VERSION "dbc-export 1 2026.26.6.5"

NS_ :

BS_:

BU_: APP BMS CC CMP CMPD CP DAS DI DIF DIR EPBL EPBR EVSE FC GTW HCML HCMR HVP ICR PCS PCS2 PM PMF PMR PTC SCCM SDCR TAS UMC V2G VC VCBATT VCBATT1 VCBATT2 VCFRONT VCFRONT1 VCLEFT VCRIGHT VCSEC

BO_ 947 UI_vehicleControl2: 8 GTW
 SG_ UI_gloveboxRequest : 0|1@1+ (1,0) [0|1] "" Vector__XXX
 SG_ UI_trunkRequest : 1|1@1+ (1,0) [0|1] "" Vector__XXX
 SG_ UI_PINToDriveEnabled : 6|1@1+ (1,0) [0|1] "" Vector__XXX
 SG_ UI_PINToDrivePassed : 7|1@1+ (1,0) [0|1] "" Vector__XXX
 SG_ UI_disableMirrorAutoDim : 8|1@1+ (1,0) [0|1] "" Vector__XXX
 SG_ UI_lightSwitch : 9|3@1+ (1,0) [0|7] "" Vector__XXX
 SG_ UI_readyToAddKey : 12|1@1+ (1,0) [0|1] "" Vector__XXX
 SG_ UI_alarmTriggerRequest : 13|1@1+ (1,0) [0|1] "" Vector__XXX
 SG_ UI_displayOnForUser : 18|1@1+ (1,0) [0|1] "" Vector__XXX
 SG_ UI_BLEPushNotificationRequest : 20|1@1+ (1,0) [0|1] "" Vector__XXX
 SG_ UI_keepAutopilotAwake : 22|1@1+ (1,0) [0|1] "" Vector__XXX
 SG_ UI_batteryPreconditioningRequest : 23|1@1+ (1,0) [0|1] "" Vector__XXX
 SG_ UI_autopilotPowerStateRequest : 25|2@1+ (1,0) [0|3] "" Vector__XXX
 SG_ UI_autoRollWindowsOnLockEnable : 29|1@1+ (1,0) [0|1] "" Vector__XXX
 SG_ UI_steeringWheelHeatReq : 33|1@1+ (1,0) [0|1] "" Vector__XXX
 SG_ UI_disableHorn : 34|1@1+ (1,0) [0|1] "" Vector__XXX
 SG_ UI_frontLeftSeatFanReq : 37|2@1+ (1,0) [0|3] "" Vector__XXX
 SG_ UI_frontRightSeatAutoClimateReq : 39|1@1+ (1,0) [0|1] "" Vector__XXX
 SG_ UI_frontRightSeatFanReq : 40|2@1+ (1,0) [0|3] "" Vector__XXX
 SG_ UI_frontLeftSeatAutoClimateReq : 56|1@1+ (1,0) [0|1] "" Vector__XXX
 SG_ UI_wiperHeaterReq : 57|1@1+ (1,0) [0|1] "" Vector__XXX
 SG_ UI_silentAlarm : 61|1@1+ (1,0) [0|1] "" Vector__XXX

BO_ 660 UI_vehicleControl3: 8 GTW
 SG_ UI_lightFlashRequest : 0|2@1+ (1,0) [0|3] "" Vector__XXX
 SG_ UI_phoneCallActive : 3|1@1+ (1,0) [0|1] "" Vector__XXX
 SG_ UI_lightShowClosuresEnabled : 8|1@1+ (1,0) [0|1] "" Vector__XXX
 SG_ UI_steeringWheelHeatAutoReq : 9|1@1+ (1,0) [0|1] "" Vector__XXX
 SG_ UI_steeringWheelHeatLevelReq : 10|2@1+ (1,0) [0|3] "" Vector__XXX
 SG_ UI_headlightPulseRequest : 12|1@1+ (1,0) [0|1] "" Vector__XXX
 SG_ UI_displayRedShiftActive : 24|1@1+ (1,0) [0|1] "" Vector__XXX
 SG_ UI_fasciaCameraWashRequest : 26|1@1+ (1,0) [0|1] "" Vector__XXX
 SG_ UI_leftRearSeatAdjustmentRequest : 28|3@1+ (1,0) [0|7] "" Vector__XXX
 SG_ UI_rightRearSeatAdjustmentReques : 32|3@1+ (1,0) [0|7] "" Vector__XXX
 SG_ UI_blindSpotIndicatorLightReques : 35|1@1+ (1,0) [0|1] "" Vector__XXX
 SG_ UI_keepOnAccessoryPortsReq : 38|1@1+ (1,0) [0|1] "" Vector__XXX
 SG_ UI_fasciaCameraShown : 39|1@1+ (1,0) [0|1] "" Vector__XXX
 SG_ UI_rearSeatChildLock : 40|2@1+ (1,0) [0|3] "" Vector__XXX
 SG_ UI_windowPercentageRequest : 42|6@1- (5,0) [-100|100] "%" Vector__XXX
 SG_ UI_windowRequestedFL : 48|1@1+ (1,0) [0|1] "" Vector__XXX
 SG_ UI_windowRequestedFR : 49|1@1+ (1,0) [0|1] "" Vector__XXX
 SG_ UI_windowRequestedRL : 50|1@1+ (1,0) [0|1] "" Vector__XXX
 SG_ UI_windowRequestedRR : 51|1@1+ (1,0) [0|1] "" Vector__XXX
 SG_ UI_windowRequest : 52|3@1+ (1,0) [0|7] "" Vector__XXX
 SG_ UI_closeTrunkRequest : 55|1@1+ (1,0) [0|1] "" Vector__XXX
 SG_ UI_childPresenceDetectionDisable : 56|1@1+ (1,0) [0|1] "" Vector__XXX
 SG_ UI_derivedLoadshedFeature : 59|1@1+ (1,0) [0|1] "" Vector__XXX
 SG_ UI_selfParkStandingBy : 62|1@1+ (1,0) [0|1] "" Vector__XXX

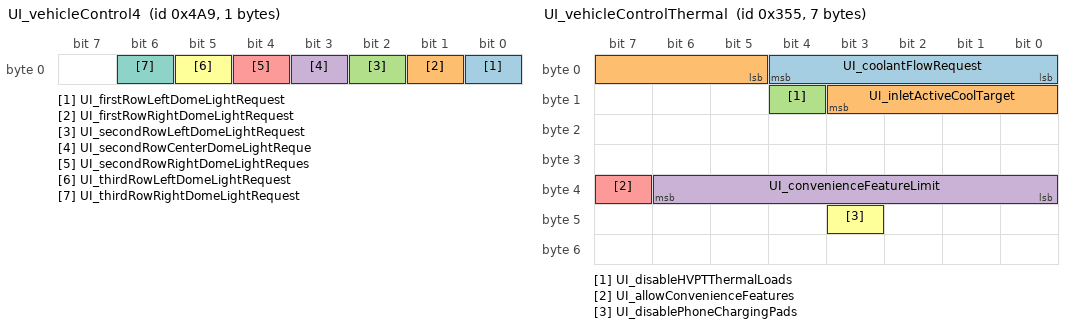
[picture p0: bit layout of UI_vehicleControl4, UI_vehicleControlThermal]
BO_ 1193 UI_vehicleControl4: 1 GTW
 SG_ UI_firstRowLeftDomeLightRequest : 0|1@1+ (1,0) [0|1] "" Vector__XXX
 SG_ UI_firstRowRightDomeLightRequest : 1|1@1+ (1,0) [0|1] "" Vector__XXX
 SG_ UI_secondRowLeftDomeLightRequest : 2|1@1+ (1,0) [0|1] "" Vector__XXX
 SG_ UI_secondRowCenterDomeLightReque : 3|1@1+ (1,0) [0|1] "" Vector__XXX
 SG_ UI_secondRowRightDomeLightReques : 4|1@1+ (1,0) [0|1] "" Vector__XXX
 SG_ UI_thirdRowLeftDomeLightRequest : 5|1@1+ (1,0) [0|1] "" Vector__XXX
 SG_ UI_thirdRowRightDomeLightRequest : 6|1@1+ (1,0) [0|1] "" Vector__XXX

BO_ 853 UI_vehicleControlThermal: 7 GTW
 SG_ UI_coolantFlowRequest : 0|5@1+ (1,0) [0|25] "LPM" Vector__XXX
 SG_ UI_inletActiveCoolTarget : 5|7@1+ (1,0) [0|127] "degC" Vector__XXX
 SG_ UI_disableHVPTThermalLoads : 12|1@1+ (1,0) [0|1] "" Vector__XXX
 SG_ UI_convenienceFeatureLimit : 32|7@1+ (1,0) [0|127] "%" Vector__XXX
 SG_ UI_allowConvenienceFeatures : 39|1@1+ (1,0) [0|1] "" Vector__XXX
 SG_ UI_disablePhoneChargingPads : 43|1@1+ (1,0) [0|1] "" Vector__XXX

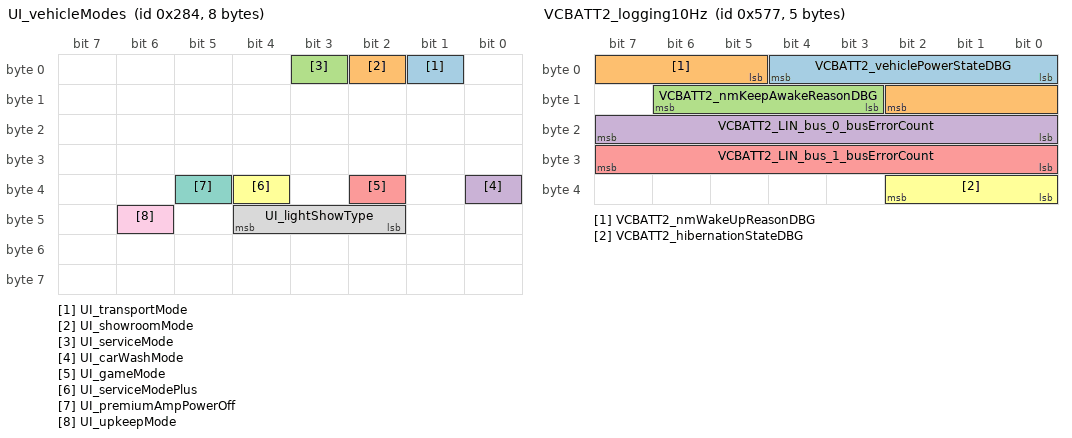
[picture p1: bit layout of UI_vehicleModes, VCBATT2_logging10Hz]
BO_ 644 UI_vehicleModes: 8 GTW
 SG_ UI_transportMode : 1|1@1+ (1,0) [0|1] "" Vector__XXX
 SG_ UI_showroomMode : 2|1@1+ (1,0) [0|1] "" Vector__XXX
 SG_ UI_serviceMode : 3|1@1+ (1,0) [0|1] "" Vector__XXX
 SG_ UI_carWashMode : 32|1@1+ (1,0) [0|1] "" Vector__XXX
 SG_ UI_gameMode : 34|1@1+ (1,0) [0|1] "" Vector__XXX
 SG_ UI_serviceModePlus : 36|1@1+ (1,0) [0|1] "" Vector__XXX
 SG_ UI_premiumAmpPowerOff : 37|1@1+ (1,0) [0|1] "" Vector__XXX
 SG_ UI_lightShowType : 42|3@1+ (1,0) [0|7] "" Vector__XXX
 SG_ UI_upkeepMode : 46|1@1+ (1,0) [0|1] "" Vector__XXX

BO_ 595 UI_ventPanelControlRequest: 8 GTW
 SG_ UI_ventPanelControlRequestIndex M : 0|1@1+ (1,0) [0|1] "" Vector__XXX
 SG_ UI_ventPanelLeftPositionX m0 : 8|8@1+ (0.5,0) [0|100] "%" Vector__XXX
 SG_ UI_ventPanelLeftPositionY m0 : 16|8@1+ (0.5,0) [0|100] "%" Vector__XXX
 SG_ UI_ventPanelLeftLateralSplit m0 : 24|8@1+ (0.5,0) [0|100] "%" Vector__XXX
 SG_ UI_ventPanelRightPositionX m0 : 32|8@1+ (0.5,0) [0|100] "%" Vector__XXX
 SG_ UI_ventPanelRightPositionY m0 : 40|8@1+ (0.5,0) [0|100] "%" Vector__XXX
 SG_ UI_ventPanelRightLateralSplit m0 : 48|8@1+ (0.5,0) [0|100] "%" Vector__XXX
 SG_ UI_ventPanelLeftLateralMode m0 : 56|2@1+ (1,0) [0|3] "" Vector__XXX
 SG_ UI_ventPanelRightLateralMode m0 : 58|2@1+ (1,0) [0|3] "" Vector__XXX
 SG_ UI_hvacReqActiveVents m0 : 60|2@1+ (1,0) [0|3] "" Vector__XXX
 SG_ UI_vent2RLeftPositionX m1 : 8|8@1+ (0.5,0) [0|100] "%" Vector__XXX
 SG_ UI_vent2RLeftPositionY m1 : 16|8@1+ (0.5,0) [0|100] "%" Vector__XXX
 SG_ UI_vent2RRightPositionX m1 : 24|8@1+ (0.5,0) [0|100] "%" Vector__XXX
 SG_ UI_vent2RRightPositionY m1 : 32|8@1+ (0.5,0) [0|100] "%" Vector__XXX
 SG_ UI_hvacReqThirdRowState m1 : 40|2@1+ (1,0) [0|3] "" Vector__XXX

BO_ 1285 UMC_smartAdapterInfo: 8 UMC
 SG_ SA_infoIndex M : 0|8@1+ (1,0) [0|255] "" Vector__XXX
 SG_ SA_genealogyVersion m0 : 8|8@1+ (1,0) [0|255] "" Vector__XXX
 SG_ SA_genealogyCrc m0 : 16|32@1+ (1,0) [0|4294967295] "" Vector__XXX
 SG_ SA_region m0 : 48|4@1+ (1,0) [0|15] "" Vector__XXX
 SG_ SA_OverTempThreshold m0 : 56|8@1+ (1,0) [0|255] "" Vector__XXX
 SG_ SA_partNumInt m31 : 8|32@1+ (1,0) [0|4294967295] "" Vector__XXX
 SG_ SA_partNumRev m31 : 40|8@1+ (1,0) [0|255] "" Vector__XXX
 SG_ SA_currentLimit m31 : 48|8@1+ (1,0) [0|255] "" Vector__XXX
 SG_ SA_l1Voltage m31 : 56|8@1+ (1,0) [0|255] "" Vector__XXX

BO_ 1949 V2G_evseLogData: 8 V2G
 SG_ V2G_evseLogDataSelect M : 0|5@1+ (1,0) [0|31] "" Vector__XXX
 SG_ V2G_chgParamRes_respCode m7 : 8|5@1+ (1,0) [0|31] "" Vector__XXX
 SG_ V2G_chgParamRes_finished m7 : 13|1@1+ (1,0) [0|1] "" Vector__XXX
 SG_ V2G_chgParamRes_evseStatus m7 : 14|4@1+ (1,0) [0|15] "" Vector__XXX
 SG_ V2G_chgParamRes_evseMaxILim m7 : 18|8@1+ (7.032,0) [0|1793.16] "A" Vector__XXX
 SG_ V2G_chgParamRes_evseMaxVLim m7 : 26|8@1+ (4.688,0) [0|1195.44] "V" Vector__XXX
 SG_ V2G_chgParamRes_evseMinILim m7 : 34|8@1+ (7.032,0) [0|1793.16] "A" Vector__XXX
 SG_ V2G_chgParamRes_evseMinVLim m7 : 42|8@1+ (4.688,0) [0|1195.44] "V" Vector__XXX
 SG_ V2G_chgParamRes_evseMaxPowerLim m7 : 50|8@1+ (5.9766,0) [0|1524.033] "kW" Vector__XXX
 SG_ V2G_chgParamRes_evseMaxPower_val m7 : 58|1@1+ (1,0) [0|1] "" Vector__XXX
 SG_ V2G_chgParamRes_isoState m7 : 59|3@1+ (1,0) [0|7] "" Vector__XXX
 SG_ V2G_chgParamRes_isoState_val m7 : 62|1@1+ (1,0) [0|1] "" Vector__XXX

BO_ 1858 VCBATT1_LVBMS_statusHigh: 8 VCBATT1
 SG_ VCBATT1_lvbmsStatusHighIndex M : 0|3@1+ (1,0) [0|7] "" Vector__XXX
 SG_ VCBATT1_LVBMS_packCurrent m0 : 3|22@1+ (0.001,-2000) [-2000|2194.302] "A" Vector__XXX
 SG_ VCBATT1_LVBMS_packVoltage m0 : 25|16@1+ (0.001,0) [0|65.534] "V" Vector__XXX
 SG_ VCBATT1_LVBMS_packTemperature m0 : 41|9@1+ (0.5,-50) [-50|205] "degC" Vector__XXX
 SG_ VCBATT1_LVBMS_MOSTemperature m0 : 50|12@1+ (0.5,-50) [-50|1997] "degC" Vector__XXX
 SG_ VCBATT1_LVBMS_sumCellVoltage m1 : 8|16@1+ (0.001,0) [0|65.534] "V" Vector__XXX
 SG_ VCBATT1_LVBMS_maxBrickVoltage m1 : 24|13@1+ (0.001,0) [0|8.19] "V" Vector__XXX
 SG_ VCBATT1_LVBMS_maxBrickVoltageInd m1 : 40|8@1+ (1,0) [0|254] "" Vector__XXX
 SG_ VCBATT1_totalLVLoadCurrent m2 : 8|14@1- (0.1,0) [-200|400] "A" Vector__XXX
 SG_ VCBATT1_LVPackChargeCurrentLimit m2 : 22|12@1+ (0.1,0) [0|400] "A" Vector__XXX
 SG_ VCBATT1_LVPackCurrent m2 : 34|14@1- (0.1,0) [-200|400] "A" Vector__XXX
 SG_ VCBATT1_LVBMS_estimatedPackOcv m2 : 48|16@1+ (0.001,0) [0|65.535] "V" Vector__XXX
 SG_ VCBATT1_LVBMS_voltageTarget m3 : 3|16@1+ (0.001,0) [0|65.534] "V" Vector__XXX
 SG_ VCBATT1_LVBMS_currentTarget m3 : 19|18@1+ (0.001,-122) [-120|120] "A" Vector__XXX
 SG_ VCBATT1_LVBMS_maxAllowedChargeCu m3 : 37|13@1+ (0.1,0) [0|819] "A" Vector__XXX
 SG_ VCBATT1_LVBMS_maxAllowedDischarg m3 : 50|13@1+ (0.1,0) [0|819] "A" Vector__XXX
 SG_ VCBATT1_LVBMS_MOSCommand m4 : 3|1@1+ (1,0) [0|1] "" Vector__XXX
 SG_ VCBATT1_LVBMS_ClearErrorCntrComm m4 : 4|1@1+ (1,0) [0|1] "" Vector__XXX
 SG_ VCBATT1_LVBMS_ClearHistoricFault m4 : 5|1@1+ (1,0) [0|1] "" Vector__XXX
 SG_ VCBATT1_LVBMS_ResetLVBMSCommand m4 : 6|1@1+ (1,0) [0|1] "" Vector__XXX
 SG_ VCBATT1_LVBMS_EnterHibernationCo m4 : 7|1@1+ (1,0) [0|1] "" Vector__XXX
 SG_ VCBATT1_LVBMS_ECPAState m4 : 8|2@1+ (1,0) [0|2] "" Vector__XXX
 SG_ VCBATT1_LVBMS_MOSState m4 : 10|2@1+ (1,0) [0|2] "" Vector__XXX
 SG_ VCBATT1_LVBMS_VehicleState m4 : 12|2@1+ (1,0) [0|3] "" Vector__XXX
 SG_ VCBATT1_LVBMS_LINWakeDisabled m4 : 14|1@1+ (1,0) [0|1] "" Vector__XXX
 SG_ VCBATT1_LVBMS_chargeType m4 : 16|3@1+ (1,0) [0|7] "" Vector__XXX
 SG_ VCBATT1_LVBMS_cellAndArcProtEnab m4 : 19|1@1+ (1,0) [0|1] "" Vector__XXX
 SG_ VCBATT1_LVBMS_avgBrickVoltage m4 : 24|13@1+ (0.001,0) [0|8.19] "V" Vector__XXX
 SG_ VCBATT1_LVBMS_minBrickVoltage m4 : 40|13@1+ (0.001,0) [0|8.19] "V" Vector__XXX
 SG_ VCBATT1_LVBMS_minBrickVoltageInd m4 : 56|8@1+ (1,0) [0|254] "" Vector__XXX

BO_ 1119 VCBATT1_LVSelfTests: 8 VCBATT1
 SG_ VCBATT1_LVSelfTestsChecksum : 0|8@1+ (1,0) [0|255] "" Vector__XXX
 SG_ VCBATT1_LVSelfTestsCounter : 8|4@1+ (1,0) [0|15] "" Vector__XXX
 SG_ VCBATT1_LVSelfTestsIndex M : 12|1@1+ (1,0) [0|1] "" Vector__XXX
 SG_ VCBATT1_lvProtectionSelfTestsEna m1 : 13|1@1+ (1,0) [0|1] "" Vector__XXX
 SG_ VCBATT1_startBattDomainOvercurre m1 : 14|1@1+ (1,0) [0|1] "" Vector__XXX
 SG_ VCBATT1_startBattDomainOvervolta m1 : 15|1@1+ (1,0) [0|1] "" Vector__XXX
 SG_ VCBATT1_startBattDomainUndervolt m1 : 16|1@1+ (1,0) [0|1] "" Vector__XXX
 SG_ VCBATT1_startDualPowerLoadsSelfT m1 : 17|1@1+ (1,0) [0|1] "" Vector__XXX
 SG_ VCBATT1_startVCBattBridgeEFuseAS m1 : 18|1@1+ (1,0) [0|1] "" Vector__XXX
 SG_ VCBATT1_startPCSOVShutdownSelfTe m1 : 19|1@1+ (1,0) [0|1] "" Vector__XXX
 SG_ VCBATT1_startPCSDomainOvervoltag m1 : 20|1@1+ (1,0) [0|1] "" Vector__XXX
 SG_ VCBATT1_startBattDomainUnde_0001 m1 : 21|1@1+ (1,0) [0|1] "" Vector__XXX
 SG_ VCBATT1_startPCSDomainUndervolta m1 : 22|1@1+ (1,0) [0|1] "" Vector__XXX
 SG_ VCBATT1_startVCFrontBridgeEFuseA m1 : 23|1@1+ (1,0) [0|1] "" Vector__XXX
 SG_ VCBATT1_battDomainOvercurrentSel m1 : 24|2@1+ (1,0) [0|3] "" Vector__XXX
 SG_ VCBATT1_battDomainOvercurre_0001 m1 : 26|3@1+ (1,0) [0|7] "" Vector__XXX
 SG_ VCBATT1_battDomainOvervoltageSel m1 : 29|2@1+ (1,0) [0|3] "" Vector__XXX
 SG_ VCBATT1_battDomainOvervolta_0001 m1 : 32|3@1+ (1,0) [0|7] "" Vector__XXX
 SG_ VCBATT1_battDomainUndervoltageSe m1 : 35|2@1+ (1,0) [0|3] "" Vector__XXX
 SG_ VCBATT1_battDomainUndervolt_0001 m1 : 37|3@1+ (1,0) [0|7] "" Vector__XXX
 SG_ VCBATT1_dualPowerLoadsSelfTestRe m1 : 40|2@1+ (1,0) [0|3] "" Vector__XXX
 SG_ VCBATT1_dualPowerLoadsSelfTestSt m1 : 42|3@1+ (1,0) [0|7] "" Vector__XXX
 SG_ VCBATT1_vcbattBridgeEFuseASICSel m1 : 45|2@1+ (1,0) [0|3] "" Vector__XXX
 SG_ VCBATT1_vcbattBridgeEFuseAS_0001 m1 : 48|3@1+ (1,0) [0|7] "" Vector__XXX
 SG_ VCBATT1_uvProtectionState m1 : 51|4@1+ (1,0) [0|15] "" Vector__XXX
 SG_ VCBATT1_undervoltageSelfTestFaul m1 : 55|1@1+ (1,0) [0|1] "" Vector__XXX
 SG_ VC_selfTestsRunningMode m1 : 56|3@1+ (1,0) [0|7] "" Vector__XXX

BO_ 1030 VCBATT1_eFuseDebugStatus: 7 VCBATT1
 SG_ VCBATT1_eFuseDebugStatusIndex M : 0|3@1+ (1,0) [0|7] "" Vector__XXX
 SG_ VCBATT1_leftControllerEFuseState m0 : 3|3@1+ (1,0) [0|7] "" Vector__XXX
 SG_ VCBATT1_leftControllerEFuseCurre m0 : 8|12@1+ (0.05,0) [0|204.75] "A" Vector__XXX
 SG_ VCBATT1_leftControllerEFuseOutpu m0 : 20|1@1+ (1,0) [0|1] "" Vector__XXX
 SG_ VCBATT1_leftControllerEFuse_0002 m0 : 21|1@1+ (1,0) [0|1] "" Vector__XXX
 SG_ VCBATT1_leftControllerEFuseBypas m0 : 22|1@1+ (1,0) [0|1] "" Vector__XXX
 SG_ VCBATT1_leftControllerEFuse_0001 m0 : 23|1@1+ (1,0) [0|1] "" Vector__XXX
 SG_ VCBATT1_leftControllerEFuseVolta m0 : 24|8@1+ (0.07,0) [0|17.85] "V" Vector__XXX
 SG_ VCBATT1_leftControllerEFuseTempe m0 : 32|8@1+ (1,-40) [-40|150] "degC" Vector__XXX
 SG_ VCBATT1_leftControllerEFuseManag m0 : 40|4@1+ (1,0) [0|15] "" Vector__XXX
 SG_ VCBATT1_leftControllerEFuseHardS m0 : 44|4@1+ (1,0) [0|15] "" Vector__XXX
 SG_ VCBATT1_leftControllerEFuseOCThr m0 : 48|5@1+ (1,0) [0|31] "" Vector__XXX
 SG_ VCBATT1_leftControllerEFuseType m0 : 53|2@1+ (1,0) [0|3] "" Vector__XXX
 SG_ VCBATT1_EPAS1EFuseState m1 : 3|3@1+ (1,0) [0|7] "" Vector__XXX
 SG_ VCBATT1_EPAS1EFuseCurrent m1 : 8|12@1+ (0.05,0) [0|204.75] "A" Vector__XXX
 SG_ VCBATT1_EPAS1EFuseOutput m1 : 20|1@1+ (1,0) [0|1] "" Vector__XXX
 SG_ VCBATT1_EPAS1EFuseOutputDesired m1 : 21|1@1+ (1,0) [0|1] "" Vector__XXX
 SG_ VCBATT1_EPAS1EFuseBypass m1 : 22|1@1+ (1,0) [0|1] "" Vector__XXX
 SG_ VCBATT1_EPAS1EFuseBypassDesired m1 : 23|1@1+ (1,0) [0|1] "" Vector__XXX
 SG_ VCBATT1_EPAS1EFuseVoltage m1 : 24|8@1+ (0.07,0) [0|17.85] "V" Vector__XXX
 SG_ VCBATT1_EPAS1EFuseTemperature m1 : 32|8@1+ (1,-40) [-40|150] "degC" Vector__XXX
 SG_ VCBATT1_EPAS1EFuseManagerState m1 : 40|4@1+ (1,0) [0|15] "" Vector__XXX
 SG_ VCBATT1_EPAS1EFuseHardShortThres m1 : 44|4@1+ (1,0) [0|15] "" Vector__XXX
 SG_ VCBATT1_EPAS1EFuseOCThreshold m1 : 48|5@1+ (1,0) [0|31] "" Vector__XXX
 SG_ VCBATT1_EPAS1EFuseType m1 : 53|2@1+ (1,0) [0|3] "" Vector__XXX
 SG_ VCBATT1_autopilot1EFuseState m3 : 3|3@1+ (1,0) [0|7] "" Vector__XXX
 SG_ VCBATT1_autopilot1EFuseCurrent m3 : 8|12@1+ (0.05,0) [0|204.75] "A" Vector__XXX
 SG_ VCBATT1_autopilot1EFuseOutput m3 : 20|1@1+ (1,0) [0|1] "" Vector__XXX
 SG_ VCBATT1_autopilot1EFuseOutputDes m3 : 21|1@1+ (1,0) [0|1] "" Vector__XXX
 SG_ VCBATT1_autopilot1EFuseBypass m3 : 22|1@1+ (1,0) [0|1] "" Vector__XXX
 SG_ VCBATT1_autopilot1EFuseBypassDes m3 : 23|1@1+ (1,0) [0|1] "" Vector__XXX
 SG_ VCBATT1_autopilot1EFuseVoltage m3 : 24|8@1+ (0.07,0) [0|17.85] "V" Vector__XXX
 SG_ VCBATT1_autopilot1EFuseTemperatu m3 : 32|8@1+ (1,-40) [-40|150] "degC" Vector__XXX
 SG_ VCBATT1_autopilot1EFuseManagerSt m3 : 40|4@1+ (1,0) [0|15] "" Vector__XXX
 SG_ VCBATT1_autopilot1EFuseHardShort m3 : 44|4@1+ (1,0) [0|15] "" Vector__XXX
 SG_ VCBATT1_autopilot1EFuseOCThresho m3 : 48|5@1+ (1,0) [0|31] "" Vector__XXX
 SG_ VCBATT1_autopilot1EFuseType m3 : 53|2@1+ (1,0) [0|3] "" Vector__XXX

BO_ 1399 VCBATT2_logging10Hz: 5 VCBATT2
 SG_ VCBATT2_vehiclePowerStateDBG : 0|5@1+ (1,0) [0|31] "" Vector__XXX
 SG_ VCBATT2_nmWakeUpReasonDBG : 5|6@1+ (1,0) [0|63] "" Vector__XXX
 SG_ VCBATT2_nmKeepAwakeReasonDBG : 11|4@1+ (1,0) [1|15] "" Vector__XXX
 SG_ VCBATT2_LIN_bus_0_busErrorCount : 16|8@1+ (1,0) [0|255] "" Vector__XXX
 SG_ VCBATT2_LIN_bus_1_busErrorCount : 24|8@1+ (1,0) [0|255] "" Vector__XXX
 SG_ VCBATT2_hibernationStateDBG : 32|3@1+ (1,0) [0|7] "" Vector__XXX

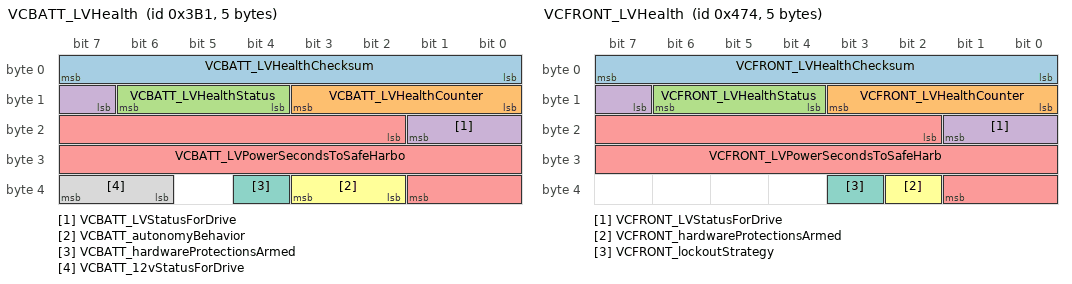
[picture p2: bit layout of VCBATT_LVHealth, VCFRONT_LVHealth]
BO_ 945 VCBATT_LVHealth: 5 VCBATT
 SG_ VCBATT_LVHealthChecksum : 0|8@1+ (1,0) [0|255] "" Vector__XXX
 SG_ VCBATT_LVHealthCounter : 8|4@1+ (1,0) [0|15] "" Vector__XXX
 SG_ VCBATT_LVHealthStatus : 12|3@1+ (1,0) [0|7] "" Vector__XXX
 SG_ VCBATT_LVStatusForDrive : 15|3@1+ (1,0) [0|7] "" Vector__XXX
 SG_ VCBATT_LVPowerSecondsToSafeHarbo : 18|16@1+ (1,0) [0|65535] "" Vector__XXX
 SG_ VCBATT_autonomyBehavior : 34|2@1+ (1,0) [0|3] "" Vector__XXX
 SG_ VCBATT_hardwareProtectionsArmed : 36|1@1+ (1,0) [0|1] "" Vector__XXX
 SG_ VCBATT_12vStatusForDrive : 38|2@1+ (1,0) [0|3] "" Vector__XXX

BO_ 1090 VCBATT_pcsInterface: 8 VCBATT
 SG_ VCBATT_pcsInterfaceMuxIndex M : 48|1@1+ (1,0) [0|1] "" Vector__XXX
 SG_ VCBATT_pcsInterfaceCounter : 50|4@1+ (1,0) [0|15] "" Vector__XXX
 SG_ VCBATT_pcsInterfaceChecksum : 56|8@1+ (1,0) [0|255] "" Vector__XXX
 SG_ VCBATT_pcsLVVoltageTarget m0 : 0|13@1+ (0.01,0) [0|65.535] "V" Vector__XXX
 SG_ VCBATT_pcsLVMinVoltageLimit m0 : 13|13@1+ (0.01,0) [0|65.535] "V" Vector__XXX
 SG_ VCBATT_pcsLVMaxVoltageLimit m0 : 27|13@1+ (0.01,0) [0|65.535] "V" Vector__XXX
 SG_ VCBATT_goodForPCSPowerCycle m0 : 46|1@1+ (1,0) [0|1] "" Vector__XXX
 SG_ VCBATT_LVBatteryCannotSupportVeh m0 : 47|1@1+ (1,0) [0|1] "" Vector__XXX
 SG_ VCBATT_pcsResistanceFiltered m1 : 0|16@1+ (0.01,0) [0|655.34] "mOhm" Vector__XXX
 SG_ VCBATT_pcsLVMaxDchrgCurrentLimit m1 : 16|12@1+ (0.1,0) [0|400] "A" Vector__XXX
 SG_ VCBATT_defaultPcsLVVoltageTarget m1 : 28|13@1+ (0.01,0) [0|65.535] "V" Vector__XXX
 SG_ VCBATT_lvHwProtSelfTestActive m1 : 41|1@1+ (1,0) [0|1] "" Vector__XXX
 SG_ VCBATT_lvBatteryDischargeRequest m1 : 42|1@1+ (1,0) [0|1] "" Vector__XXX

BO_ 1027 VCFRONT1_eFuseDebugStatus: 7 VCFRONT1
 SG_ VCFRONT1_eFuseDebugStatusIndex M : 0|3@1+ (1,0) [0|7] "" Vector__XXX
 SG_ VCFRONT1_EPAS2EFuseState m0 : 3|3@1+ (1,0) [0|7] "" Vector__XXX
 SG_ VCFRONT1_EPAS2EFuseCurrent m0 : 8|12@1+ (0.05,0) [0|204.75] "A" Vector__XXX
 SG_ VCFRONT1_EPAS2EFuseOutput m0 : 20|1@1+ (1,0) [0|1] "" Vector__XXX
 SG_ VCFRONT1_EPAS2EFuseOutputDesired m0 : 21|1@1+ (1,0) [0|1] "" Vector__XXX
 SG_ VCFRONT1_EPAS2EFuseBypass m0 : 22|1@1+ (1,0) [0|1] "" Vector__XXX
 SG_ VCFRONT1_EPAS2EFuseBypassDesired m0 : 23|1@1+ (1,0) [0|1] "" Vector__XXX
 SG_ VCFRONT1_EPAS2EFuseVoltage m0 : 24|8@1+ (0.07,0) [0|17.85] "V" Vector__XXX
 SG_ VCFRONT1_EPAS2EFuseTemperature m0 : 32|8@1+ (1,-40) [-40|150] "degC" Vector__XXX
 SG_ VCFRONT1_EPAS2EFuseManagerState m0 : 40|4@1+ (1,0) [0|15] "" Vector__XXX
 SG_ VCFRONT1_EPAS2EFuseHardShortThre m0 : 44|4@1+ (1,0) [0|15] "" Vector__XXX
 SG_ VCFRONT1_EPAS2EFuseOCThreshold m0 : 48|5@1+ (1,0) [0|31] "" Vector__XXX
 SG_ VCFRONT1_EPAS2EFuseType m0 : 53|2@1+ (1,0) [0|3] "" Vector__XXX
 SG_ VCFRONT1_rightControllerEFuseSta m1 : 3|3@1+ (1,0) [0|7] "" Vector__XXX
 SG_ VCFRONT1_rightControllerEFuseCur m1 : 8|12@1+ (0.05,0) [0|204.75] "A" Vector__XXX
 SG_ VCFRONT1_rightControllerEFuseOut m1 : 20|1@1+ (1,0) [0|1] "" Vector__XXX
 SG_ VCFRONT1_rightControllerEFu_0002 m1 : 21|1@1+ (1,0) [0|1] "" Vector__XXX
 SG_ VCFRONT1_rightControllerEFuseByp m1 : 22|1@1+ (1,0) [0|1] "" Vector__XXX
 SG_ VCFRONT1_rightControllerEFu_0001 m1 : 23|1@1+ (1,0) [0|1] "" Vector__XXX
 SG_ VCFRONT1_rightControllerEFuseVol m1 : 24|8@1+ (0.07,0) [0|17.85] "V" Vector__XXX
 SG_ VCFRONT1_rightControllerEFuseTem m1 : 32|8@1+ (1,-40) [-40|150] "degC" Vector__XXX
 SG_ VCFRONT1_rightControllerEFuseMan m1 : 40|4@1+ (1,0) [0|15] "" Vector__XXX
 SG_ VCFRONT1_rightControllerEFuseHar m1 : 44|4@1+ (1,0) [0|15] "" Vector__XXX
 SG_ VCFRONT1_rightControllerEFuseOCT m1 : 48|5@1+ (1,0) [0|31] "" Vector__XXX
 SG_ VCFRONT1_rightControllerEFuseTyp m1 : 53|2@1+ (1,0) [0|3] "" Vector__XXX
 SG_ VCFRONT1_autopilot2EFuseState m3 : 3|3@1+ (1,0) [0|7] "" Vector__XXX
 SG_ VCFRONT1_autopilot2EFuseCurrent m3 : 8|12@1+ (0.05,0) [0|204.75] "A" Vector__XXX
 SG_ VCFRONT1_autopilot2EFuseOutput m3 : 20|1@1+ (1,0) [0|1] "" Vector__XXX
 SG_ VCFRONT1_autopilot2EFuseOutputDe m3 : 21|1@1+ (1,0) [0|1] "" Vector__XXX
 SG_ VCFRONT1_autopilot2EFuseBypass m3 : 22|1@1+ (1,0) [0|1] "" Vector__XXX
 SG_ VCFRONT1_autopilot2EFuseBypassDe m3 : 23|1@1+ (1,0) [0|1] "" Vector__XXX
 SG_ VCFRONT1_autopilot2EFuseVoltage m3 : 24|8@1+ (0.07,0) [0|17.85] "V" Vector__XXX
 SG_ VCFRONT1_autopilot2EFuseTemperat m3 : 32|8@1+ (1,-40) [-40|150] "degC" Vector__XXX
 SG_ VCFRONT1_autopilot2EFuseManagerS m3 : 40|4@1+ (1,0) [0|15] "" Vector__XXX
 SG_ VCFRONT1_autopilot2EFuseHardShor m3 : 44|4@1+ (1,0) [0|15] "" Vector__XXX
 SG_ VCFRONT1_autopilot2EFuseOCThresh m3 : 48|5@1+ (1,0) [0|31] "" Vector__XXX
 SG_ VCFRONT1_autopilot2EFuseType m3 : 53|2@1+ (1,0) [0|3] "" Vector__XXX

BO_ 609 VCFRONT_12VBatteryStatus: 8 VCFRONT
 SG_ VCFRONT_12VBatteryStatusIndex M : 0|3@1+ (1,0) [0|7] "" Vector__XXX
 SG_ VCFRONT_good12VforUpdate : 46|1@1+ (1,0) [0|1] "" Vector__XXX
 SG_ VCFRONT_LVLoadRequest : 47|1@1+ (1,0) [0|1] "" Vector__XXX
 SG_ VCFRONT_12VBatteryStatusCounter : 52|4@1+ (1,0) [0|15] "" Vector__XXX
 SG_ VCFRONT_12VBatteryStatusChecksum : 56|8@1+ (1,0) [0|255] "" Vector__XXX
 SG_ VCFRONT_batterySupportRequest m1 : 3|1@1+ (1,0) [0|1] "" Vector__XXX
 SG_ VCFRONT_batterySMState m1 : 4|4@1+ (1,0) [0|15] "" Vector__XXX
 SG_ VCFRONT_eFuseRecoveryStateDBG m1 : 8|3@1+ (1,0) [0|7] "" Vector__XXX
 SG_ VCFRONT_batteryLINScheduleDBG m1 : 11|3@1+ (1,0) [0|6] "" Vector__XXX
 SG_ VCFRONT_resistanceEstimationTest m1 : 14|2@1+ (1,0) [0|3] "" Vector__XXX
 SG_ VCFRONT_IBSCurrent m1 : 16|16@1- (0.005,0) [-163.84|163.835] "A" Vector__XXX
 SG_ VCFRONT_IBSVoltage m1 : 32|14@1+ (0.005443676,0) [0|65.535] "V" Vector__XXX
 SG_ VCFRONT_reverseBatteryFault m1 : 48|1@1+ (1,0) [0|1] "" Vector__XXX
 SG_ VCFRONT_LVBatterySupported m1 : 49|1@1+ (1,0) [0|1] "" Vector__XXX
 SG_ VCFRONT_LVBatteryCannotSupportVe m1 : 50|1@1+ (1,0) [0|1] "" Vector__XXX
 SG_ VCFRONT_goodTemp12VforUpdate m1 : 51|1@1+ (1,0) [0|1] "" Vector__XXX
 SG_ VCFRONT_12VBatteryTargetVoltage m2 : 3|13@1+ (0.01,0) [0|65.535] "V" Vector__XXX
 SG_ VCFRONT_IBSTemperature m2 : 16|11@1+ (0.1,-24) [-24|124] "degC" Vector__XXX
 SG_ VCFRONT_currentSensorMismatchLea m2 : 27|7@1+ (2,0) [0|254] "PCT" Vector__XXX
 SG_ VCFRONT_LVBatteryEnergyRemaining m2 : 37|7@1+ (1,0) [0|127] "%" Vector__XXX
 SG_ VCFRONT_LVBatteryStatusForDrive m2 : 44|2@1+ (1,0) [0|3] "" Vector__XXX
 SG_ VCFRONT_LVBatteryType m2 : 48|3@1+ (1,0) [0|7] "" Vector__XXX
 SG_ VCFRONT_resistanceEstimationNeed m2 : 51|1@1+ (1,0) [0|1] "" Vector__XXX
 SG_ VCFRONT_IBSVoltageFiltered m3 : 3|14@1+ (0.005443676,0) [0|65.535] "V" Vector__XXX
 SG_ VCFRONT_LVBMS_LVBusVoltageSource m3 : 17|2@1+ (1,0) [0|3] "" Vector__XXX
 SG_ VCFRONT_LVBMS_LVPackCurrentSourc m3 : 19|2@1+ (1,0) [0|3] "" Vector__XXX
 SG_ VCFRONT_LVBatterySupportRqrdTrig m3 : 24|14@1+ (1,0) [0|16383] "" Vector__XXX
 SG_ VCFRONT_goodForPCSPowerCycleLeak m3 : 40|5@1+ (0.0005,0) [0|0.0155] "Ah" Vector__XXX
 SG_ VCFRONT_LVBusControlsFutile m3 : 45|1@1+ (1,0) [0|1] "" Vector__XXX
 SG_ VCFRONT_resistanceEstimatio_0001 m3 : 48|1@1+ (1,0) [0|1] "" Vector__XXX
 SG_ VCFRONT_resistanceEstimatio_0002 m3 : 49|1@1+ (1,0) [0|1] "" Vector__XXX
 SG_ VCFRONT_goodLVChargeForUpdate m3 : 50|1@1+ (1,0) [0|1] "" Vector__XXX
 SG_ VCFRONT_opportunisticDCRTestNeed m3 : 51|1@1+ (1,0) [0|1] "" Vector__XXX
 SG_ VCFRONT_voltageProfile m4 : 3|2@1+ (1,0) [0|3] "" Vector__XXX
 SG_ VCFRONT_IBSAmpHours m4 : 5|14@1- (0.005,0) [-40.96|40.955] "Ah" Vector__XXX
 SG_ VCFRONT_IBSVoltageRawDBG m4 : 19|14@1+ (0.005443676,0) [0|65.535] "V" Vector__XXX
 SG_ VCFRONT_LVBatteryLINCommsDetecte m4 : 33|1@1+ (1,0) [0|1] "" Vector__XXX
 SG_ VCFRONT_voltageSensorMismatchLea m4 : 34|7@1+ (2,0) [0|254] "PCT" Vector__XXX
 SG_ VCFRONT_LVBusControlMode m4 : 41|4@1+ (1,0) [0|15] "" Vector__XXX
 SG_ VCFRONT_resistanceEstimationExte m4 : 45|1@1+ (1,0) [0|1] "" Vector__XXX
 SG_ VCFRONT_LVBatteryFctryLimOverrid m4 : 50|1@1+ (1,0) [0|1] "" Vector__XXX
 SG_ VCFRONT_LVBatterySPICommsDetecte m4 : 51|1@1+ (1,0) [0|1] "" Vector__XXX
 SG_ VCFRONT_targetCurrent m5 : 3|11@1+ (0.125,-127) [0|120] "A" Vector__XXX
 SG_ VCFRONT_PCSMia m5 : 14|1@1+ (1,0) [0|1] "" Vector__XXX
 SG_ VCFRONT_chargeNeeded m5 : 15|1@1+ (1,0) [0|1] "" Vector__XXX
 SG_ VCFRONT_voltageControlLoopIntegr m5 : 16|14@1+ (0.006,0) [0|65.535] "V" Vector__XXX
 SG_ VCFRONT_currentControlLoopIntegr m5 : 30|14@1+ (0.006,0) [0|65.535] "V" Vector__XXX

BO_ 1847 VCFRONT_LVBMS_info: 7 VCFRONT
 SG_ VCFRONT_LVBMS_InfoIndex M : 0|8@1+ (1,0) [0|255] "" Vector__XXX
 SG_ VCFRONT_LVBMS_PcbaId m0 : 8|16@1+ (1,0) [0|65535] "" Vector__XXX
 SG_ VCFRONT_LVBMS_AssemblyId m0 : 24|16@1+ (1,0) [0|65535] "" Vector__XXX
 SG_ VCFRONT_LVBMS_SubUsageId m0 : 40|16@1+ (1,0) [0|65534] "" Vector__XXX
 SG_ VCFRONT_LVBMS_UsageId m1 : 8|16@1+ (1,0) [0|65535] "" Vector__XXX
 SG_ VCFRONT_LVBMS_AppCRC m1 : 24|32@1+ (1,0) [0|4294967295] "" Vector__XXX
 SG_ VCFRONT_LVBMS_FWBuildType m3 : 8|8@1+ (1,0) [0|255] "" Vector__XXX

BO_ 1140 VCFRONT_LVHealth: 5 VCFRONT
 SG_ VCFRONT_LVHealthChecksum : 0|8@1+ (1,0) [0|255] "" Vector__XXX
 SG_ VCFRONT_LVHealthCounter : 8|4@1+ (1,0) [0|15] "" Vector__XXX
 SG_ VCFRONT_LVHealthStatus : 12|3@1+ (1,0) [0|7] "" Vector__XXX
 SG_ VCFRONT_LVStatusForDrive : 15|3@1+ (1,0) [0|7] "" Vector__XXX
 SG_ VCFRONT_LVPowerSecondsToSafeHarb : 18|16@1+ (1,0) [0|65535] "" Vector__XXX
 SG_ VCFRONT_hardwareProtectionsArmed : 34|1@1+ (1,0) [0|1] "" Vector__XXX
 SG_ VCFRONT_lockoutStrategy : 35|1@1+ (1,0) [0|1] "" Vector__XXX

BO_ 1173 VCFRONT_LVHealthDebug: 6 VCFRONT
 SG_ VCFRONT_LVHealthDebugIndex M : 0|4@1+ (1,0) [0|15] "" Vector__XXX
 SG_ VCFRONT_LVHEALTH_placeholder m0 : 8|1@1+ (1,0) [0|1] "" Vector__XXX
 SG_ VCFRONT_LVHEALTH_activeDecelEner m0 : 9|1@1+ (1,0) [0|1] "" Vector__XXX
 SG_ VCFRONT_LVHEALTH_criticalPullove m0 : 10|1@1+ (1,0) [0|1] "" Vector__XXX
 SG_ VCFRONT_LVHEALTH_revBattEFuseOff m0 : 11|1@1+ (1,0) [0|1] "" Vector__XXX
 SG_ VCFRONT_LVHEALTH_LVBMBEFuseOpen m0 : 12|1@1+ (1,0) [0|1] "" Vector__XXX
 SG_ VCFRONT_LVHEALTH_lvBatteryCommsM m0 : 13|1@1+ (1,0) [0|1] "" Vector__XXX
 SG_ VCFRONT_LVHEALTH_pcsEFuseOff m0 : 14|1@1+ (1,0) [0|1] "" Vector__XXX
 SG_ VCFRONT_LVHEALTH_pcsNotActive m0 : 15|1@1+ (1,0) [0|1] "" Vector__XXX
 SG_ VCFRONT_LVHEALTH_pcsMIA m0 : 16|1@1+ (1,0) [0|1] "" Vector__XXX
 SG_ VCFRONT_LVHEALTH_IBSMIA m0 : 17|1@1+ (1,0) [0|1] "" Vector__XXX
 SG_ VCFRONT_LVHEALTH_LVBatteryElecDi m0 : 18|1@1+ (1,0) [0|1] "" Vector__XXX
 SG_ VCFRONT_LVHEALTH_LVBatteryE_0001 m0 : 19|1@1+ (1,0) [0|1] "" Vector__XXX
 SG_ VCFRONT_LVHEALTH_pcsOpenCircuit m0 : 20|1@1+ (1,0) [0|1] "" Vector__XXX
 SG_ VCFRONT_LVHEALTH_activeDecelPowe m0 : 21|1@1+ (1,0) [0|1] "" Vector__XXX
 SG_ VCFRONT_LVHEALTH_lvBatteryCapabi m0 : 22|1@1+ (1,0) [0|1] "" Vector__XXX
 SG_ VCFRONT_LVHEALTH_lvBatteryConfig m0 : 23|1@1+ (1,0) [0|1] "" Vector__XXX
 SG_ VCFRONT_LVHEALTH_lvBatteryImpeda m0 : 24|1@1+ (1,0) [0|1] "" Vector__XXX
 SG_ VCFRONT_LVHEALTH_lvBatteryExtend m0 : 25|1@1+ (1,0) [0|1] "" Vector__XXX

BO_ 545 VCFRONT_LVPowerState: 8 VCFRONT
 SG_ VCFRONT_LVPowerStateIndex M : 0|5@1+ (1,0) [0|31] "" Vector__XXX
 SG_ VCFRONT_vehiclePowerState : 5|2@1+ (1,0) [0|3] "" Vector__XXX
 SG_ VCFRONT_inAccessoryPlus : 50|1@1+ (1,0) [0|1] "" Vector__XXX
 SG_ VCFRONT_LVShuttingDown : 51|1@1+ (1,0) [0|1] "" Vector__XXX
 SG_ VCFRONT_LVPowerStateCounter : 52|4@1+ (1,0) [0|15] "" Vector__XXX
 SG_ VCFRONT_LVPowerStateChecksum : 56|8@1+ (1,0) [0|255] "" Vector__XXX
 SG_ VCFRONT_cpLVRequest m1 : 8|2@1+ (1,0) [0|3] "" Vector__XXX
 SG_ VCFRONT_epasLVState m1 : 10|2@1+ (1,0) [0|3] "" Vector__XXX
 SG_ VCFRONT_hvcLVRequest m1 : 12|2@1+ (1,0) [0|3] "" Vector__XXX
 SG_ VCFRONT_tasLVState m1 : 14|2@1+ (1,0) [0|3] "" Vector__XXX
 SG_ VCFRONT_pcsLVState m1 : 16|2@1+ (1,0) [0|3] "" Vector__XXX
 SG_ VCFRONT_CMPDLVState m1 : 18|2@1+ (1,0) [0|3] "" Vector__XXX
 SG_ VCFRONT_hcmlLVState m1 : 20|2@1+ (1,0) [0|3] "" Vector__XXX
 SG_ VCFRONT_hcmrLVState m1 : 22|2@1+ (1,0) [0|3] "" Vector__XXX
 SG_ VCFRONT_MCUAudioLVState m1 : 24|2@1+ (1,0) [0|3] "" Vector__XXX
 SG_ VCFRONT_espValveLVState m1 : 26|2@1+ (1,0) [0|3] "" Vector__XXX
 SG_ VCFRONT_MCUGraphicsLVState m1 : 28|2@1+ (1,0) [0|3] "" Vector__XXX
 SG_ VC_dcdcSupportRequest m1 : 30|1@1+ (1,0) [0|1] "" Vector__XXX
 SG_ VC_hvStateRequest m1 : 31|3@1+ (1,0) [0|7] "" Vector__XXX
 SG_ VC_autonomyBehavior m1 : 34|2@1+ (1,0) [0|3] "" Vector__XXX
 SG_ VC_persistAccPowerRequestOverrid m1 : 39|1@1+ (1,0) [0|1] "" Vector__XXX
 SG_ VC_accPortPowerRequest m1 : 40|1@1+ (1,0) [0|1] "" Vector__XXX
 SG_ VC_persistAccPortPowerState m1 : 41|3@1+ (1,0) [0|7] "" Vector__XXX
 SG_ VC_noAccDeviceDetectedWhileIdle m1 : 46|1@1+ (1,0) [0|1] "" Vector__XXX

BO_ 700 VCFRONT_LVThermalMotors10Hz: 8 VCFRONT
 SG_ VCFRONT_LVThermalMotorsIndex M : 0|4@1+ (1,0) [0|15] "" Vector__XXX
 SG_ VCFRONT_radiatorFanState m0 : 4|3@1+ (1,0) [0|7] "" Vector__XXX
 SG_ VCFRONT_radiatorFanTorque m0 : 8|10@1+ (0.006,-1.5) [-1.5|4.5] "Nm" Vector__XXX
 SG_ VCFRONT_radiatorFanIDc m0 : 24|7@1+ (0.5,0) [0|63] "A" Vector__XXX
 SG_ VCFRONT_mlxLINCurrentSchedule m0 : 32|2@1+ (1,0) [0|3] "" Vector__XXX
 SG_ VCFRONT_pumpPowertrainState m3 : 4|3@1+ (1,0) [0|7] "" Vector__XXX
 SG_ VCFRONT_pumpPowertrainTorque m3 : 8|10@1+ (0.006,-1.5) [-1.5|4.5] "Nm" Vector__XXX
 SG_ VCFRONT_pumpPowertrainIDc m3 : 24|7@1+ (0.5,0) [0|63] "A" Vector__XXX
 SG_ VCFRONT_pumpBatteryState m6 : 4|3@1+ (1,0) [0|7] "" Vector__XXX
 SG_ VCFRONT_pumpBatteryTorque m6 : 8|10@1+ (0.006,-1.5) [-1.5|4.5] "Nm" Vector__XXX
 SG_ VCFRONT_pumpBatteryIDc m6 : 24|7@1+ (0.5,0) [0|63] "A" Vector__XXX

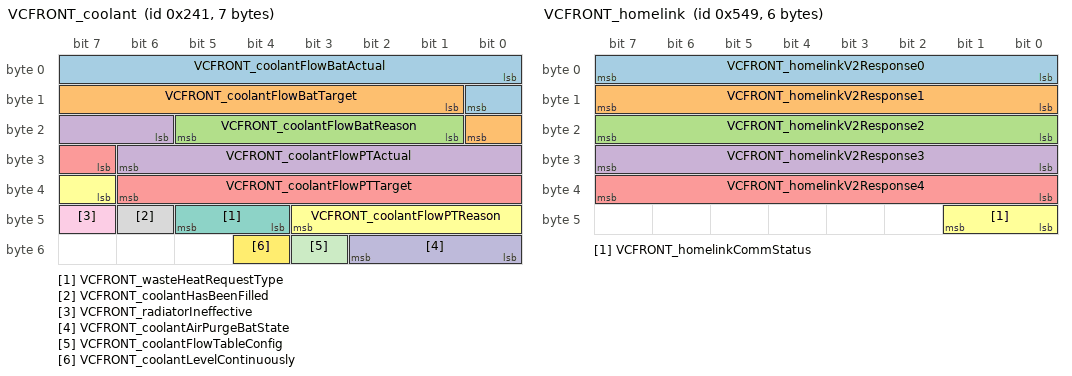
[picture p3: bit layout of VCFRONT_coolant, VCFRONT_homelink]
BO_ 577 VCFRONT_coolant: 7 VCFRONT
 SG_ VCFRONT_coolantFlowBatActual : 0|9@1+ (0.1,0) [0|40] "LPM" Vector__XXX
 SG_ VCFRONT_coolantFlowBatTarget : 9|8@1+ (0.2,0) [0|40] "LPM" Vector__XXX
 SG_ VCFRONT_coolantFlowBatReason : 17|5@1+ (1,0) [0|31] "" Vector__XXX
 SG_ VCFRONT_coolantFlowPTActual : 22|9@1+ (0.1,0) [0|40] "LPM" Vector__XXX
 SG_ VCFRONT_coolantFlowPTTarget : 31|8@1+ (0.2,0) [0|40] "LPM" Vector__XXX
 SG_ VCFRONT_coolantFlowPTReason : 39|5@1+ (1,0) [0|31] "" Vector__XXX
 SG_ VCFRONT_wasteHeatRequestType : 44|2@1+ (1,0) [0|3] "" Vector__XXX
 SG_ VCFRONT_coolantHasBeenFilled : 46|1@1+ (1,0) [0|1] "" Vector__XXX
 SG_ VCFRONT_radiatorIneffective : 47|1@1+ (1,0) [0|1] "" Vector__XXX
 SG_ VCFRONT_coolantAirPurgeBatState : 48|3@1+ (1,0) [0|7] "" Vector__XXX
 SG_ VCFRONT_coolantFlowTableConfig : 51|1@1+ (1,0) [0|1] "" Vector__XXX
 SG_ VCFRONT_coolantLevelContinuously : 52|1@1+ (1,0) [0|1] "" Vector__XXX

BO_ 753 VCFRONT_eFuseDebugStatus: 8 VCFRONT
 SG_ VCFRONT_eFuseDebugStatusIndex M : 0|5@1+ (1,0) [0|31] "" Vector__XXX
 SG_ VCFRONT_leftControllerState m1 : 8|2@1+ (1,0) [0|2] "" Vector__XXX
 SG_ VCFRONT_leftControllerFault m1 : 10|1@1+ (1,0) [0|1] "" Vector__XXX
 SG_ VCFRONT_vcleftSelfTestResult m1 : 11|4@1+ (1,0) [0|15] "" Vector__XXX
 SG_ VCFRONT_leftControllerTemp m1 : 15|11@1+ (0.125,-40) [-40|150] "degC" Vector__XXX
 SG_ VCFRONT_leftControllerEFuseVNFSt m1 : 26|3@1+ (1,0) [0|7] "" Vector__XXX
 SG_ VCFRONT_leftControllerEFuseOutpu m1 : 29|1@1+ (1,0) [0|1] "" Vector__XXX
 SG_ VCFRONT_leftControllerEFuse_0002 m1 : 30|1@1+ (1,0) [0|1] "" Vector__XXX
 SG_ VCFRONT_leftControllerVoltage m1 : 31|14@1+ (0.1,0) [0|1638.3] "V" Vector__XXX
 SG_ VCFRONT_leftControllerEFuseBypas m1 : 45|1@1+ (1,0) [0|1] "" Vector__XXX
 SG_ VCFRONT_leftControllerEFuse_0001 m1 : 46|1@1+ (1,0) [0|1] "" Vector__XXX
 SG_ VCFRONT_leftControllerCurrent m1 : 47|14@1+ (0.1,0) [0|1638.3] "A" Vector__XXX
 SG_ VCFRONT_leftControllerEFuseVNFSe m1 : 61|2@1+ (1,0) [0|3] "" Vector__XXX
 SG_ VCFRONT_PCSState m2 : 8|2@1+ (1,0) [0|2] "" Vector__XXX
 SG_ VCFRONT_PCSFault m2 : 10|1@1+ (1,0) [0|1] "" Vector__XXX
 SG_ VCFRONT_pcsSelfTestResult m2 : 11|4@1+ (1,0) [0|15] "" Vector__XXX
 SG_ VCFRONT_PCSTemp m2 : 15|11@1+ (0.125,-40) [-40|150] "degC" Vector__XXX
 SG_ VCFRONT_PCSEFuseVNFState m2 : 26|3@1+ (1,0) [0|7] "" Vector__XXX
 SG_ VCFRONT_PCSEFuseOutput m2 : 29|1@1+ (1,0) [0|1] "" Vector__XXX
 SG_ VCFRONT_PCSEFuseOutputDesired m2 : 30|1@1+ (1,0) [0|1] "" Vector__XXX
 SG_ VCFRONT_PCSVoltage m2 : 31|14@1+ (0.1,0) [0|1638.3] "V" Vector__XXX
 SG_ VCFRONT_PCSEFuseBypass m2 : 45|1@1+ (1,0) [0|1] "" Vector__XXX
 SG_ VCFRONT_PCSEFuseBypassDesired m2 : 46|1@1+ (1,0) [0|1] "" Vector__XXX
 SG_ VCFRONT_PCSEFuseVNFSelfTestStatu m2 : 61|2@1+ (1,0) [0|3] "" Vector__XXX
 SG_ VCFRONT_iBoosterState m3 : 8|2@1+ (1,0) [0|2] "" Vector__XXX
 SG_ VCFRONT_iBoosterFault m3 : 10|1@1+ (1,0) [0|1] "" Vector__XXX
 SG_ VCFRONT_iBoosterSelfTestResult m3 : 11|4@1+ (1,0) [0|15] "" Vector__XXX
 SG_ VCFRONT_iBoosterTemp m3 : 15|11@1+ (0.125,-40) [-40|150] "degC" Vector__XXX
 SG_ VCFRONT_iBoosterEFuseVNFState m3 : 26|3@1+ (1,0) [0|7] "" Vector__XXX
 SG_ VCFRONT_iBoosterEFuseOutput m3 : 29|1@1+ (1,0) [0|1] "" Vector__XXX
 SG_ VCFRONT_iBoosterEFuseOutputDesir m3 : 30|1@1+ (1,0) [0|1] "" Vector__XXX
 SG_ VCFRONT_iBoosterVoltage m3 : 31|9@1+ (0.1,0) [0|51.1] "V" Vector__XXX
 SG_ VCFRONT_iBoosterHardshortThresho m3 : 40|4@1+ (1,0) [0|15] "" Vector__XXX
 SG_ VCFRONT_iBoosterEFuseBypass m3 : 45|1@1+ (1,0) [0|1] "" Vector__XXX
 SG_ VCFRONT_iBoosterEFuseBypassDesir m3 : 46|1@1+ (1,0) [0|1] "" Vector__XXX
 SG_ VCFRONT_iBoosterCurrent m3 : 47|14@1+ (0.1,0) [0|1638.3] "A" Vector__XXX
 SG_ VCFRONT_iBoosterEFuseVNFSelfTest m3 : 61|2@1+ (1,0) [0|3] "" Vector__XXX
 SG_ VCFRONT_EPAS3PState m4 : 8|2@1+ (1,0) [0|2] "" Vector__XXX
 SG_ VCFRONT_EPAS3PFault m4 : 10|1@1+ (1,0) [0|1] "" Vector__XXX
 SG_ VCFRONT_EPAS3PSelfTestResult m4 : 11|4@1+ (1,0) [0|15] "" Vector__XXX
 SG_ VCFRONT_EPAS3PTemp m4 : 15|11@1+ (0.125,-40) [-40|150] "degC" Vector__XXX
 SG_ VCFRONT_EPAS3PEFuseVNFState m4 : 26|3@1+ (1,0) [0|7] "" Vector__XXX
 SG_ VCFRONT_EPAS3PEFuseOutput m4 : 29|1@1+ (1,0) [0|1] "" Vector__XXX
 SG_ VCFRONT_EPAS3PEFuseOutputDesired m4 : 30|1@1+ (1,0) [0|1] "" Vector__XXX
 SG_ VCFRONT_EPAS3PVoltage m4 : 31|9@1+ (0.1,0) [0|51.1] "V" Vector__XXX
 SG_ VCFRONT_EPAS3PEFuseHardshortThre m4 : 40|4@1+ (1,0) [0|15] "" Vector__XXX
 SG_ VCFRONT_EPAS3PEFuseBypass m4 : 45|1@1+ (1,0) [0|1] "" Vector__XXX
 SG_ VCFRONT_EPAS3PEFuseBypassDesired m4 : 46|1@1+ (1,0) [0|1] "" Vector__XXX
 SG_ VCFRONT_EPAS3PCurrent m4 : 47|14@1+ (0.1,0) [0|1638.3] "A" Vector__XXX
 SG_ VCFRONT_EPAS3PEFuseVNFSelfTestSt m4 : 61|2@1+ (1,0) [0|3] "" Vector__XXX
 SG_ VCFRONT_EPAS3SState m5 : 8|2@1+ (1,0) [0|2] "" Vector__XXX
 SG_ VCFRONT_EPAS3SFault m5 : 10|1@1+ (1,0) [0|1] "" Vector__XXX
 SG_ VCFRONT_EPAS3SSelfTestResult m5 : 11|4@1+ (1,0) [0|15] "" Vector__XXX
 SG_ VCFRONT_EPAS3STemp m5 : 15|11@1+ (0.125,-40) [-40|150] "degC" Vector__XXX
 SG_ VCFRONT_EPAS3SEFuseVNFState m5 : 26|3@1+ (1,0) [0|7] "" Vector__XXX
 SG_ VCFRONT_EPAS3SEFuseOutput m5 : 29|1@1+ (1,0) [0|1] "" Vector__XXX
 SG_ VCFRONT_EPAS3SEFuseOutputDesired m5 : 30|1@1+ (1,0) [0|1] "" Vector__XXX
 SG_ VCFRONT_EPAS3SVoltage m5 : 31|14@1+ (0.1,0) [0|1638.3] "V" Vector__XXX
 SG_ VCFRONT_EPAS3SEFuseBypass m5 : 45|1@1+ (1,0) [0|1] "" Vector__XXX
 SG_ VCFRONT_EPAS3SEFuseBypassDesired m5 : 46|1@1+ (1,0) [0|1] "" Vector__XXX
 SG_ VCFRONT_EPAS3SCurrent m5 : 47|14@1+ (0.1,0) [0|1638.3] "A" Vector__XXX
 SG_ VCFRONT_EPAS3SEFuseVNFSelfTestSt m5 : 61|2@1+ (1,0) [0|3] "" Vector__XXX
 SG_ VCFRONT_ESPMotorState m6 : 8|2@1+ (1,0) [0|2] "" Vector__XXX
 SG_ VCFRONT_ESPMotorFault m6 : 10|1@1+ (1,0) [0|1] "" Vector__XXX
 SG_ VCFRONT_ESPMotorSelfTestResult m6 : 11|4@1+ (1,0) [0|15] "" Vector__XXX
 SG_ VCFRONT_ESPMotorTemp m6 : 15|11@1+ (0.125,-40) [-40|150] "degC" Vector__XXX
 SG_ VCFRONT_ESPMotorEFuseVNFState m6 : 26|3@1+ (1,0) [0|7] "" Vector__XXX
 SG_ VCFRONT_ESPMotorEFuseOutput m6 : 29|1@1+ (1,0) [0|1] "" Vector__XXX
 SG_ VCFRONT_ESPMotorEFuseOutputDesir m6 : 30|1@1+ (1,0) [0|1] "" Vector__XXX
 SG_ VCFRONT_ESPMotorVoltage m6 : 31|14@1+ (0.1,0) [0|1638.3] "V" Vector__XXX
 SG_ VCFRONT_ESPMotorEFuseBypass m6 : 45|1@1+ (1,0) [0|1] "" Vector__XXX
 SG_ VCFRONT_ESPMotorEFuseBypassDesir m6 : 46|1@1+ (1,0) [0|1] "" Vector__XXX
 SG_ VCFRONT_ESPMotorCurrent m6 : 47|14@1+ (0.1,0) [0|1638.3] "A" Vector__XXX
 SG_ VCFRONT_ESPMotorEFuseVNFSelfTest m6 : 61|2@1+ (1,0) [0|3] "" Vector__XXX
 SG_ VCFRONT_ESPValveState m7 : 8|2@1+ (1,0) [0|2] "" Vector__XXX
 SG_ VCFRONT_ESPValveFault m7 : 10|1@1+ (1,0) [0|1] "" Vector__XXX
 SG_ VCFRONT_ESPValveTemp m7 : 12|11@1+ (0.125,-40) [-40|150] "degC" Vector__XXX
 SG_ VCFRONT_ESPValveVoltage m7 : 28|16@1+ (0.1,0) [0|6553.5] "V" Vector__XXX
 SG_ VCFRONT_ESPValveCurrent m7 : 44|16@1+ (0.01,0) [0|655.35] "A" Vector__XXX
 SG_ VCFRONT_autopilot2State m9 : 8|2@1+ (1,0) [0|2] "" Vector__XXX
 SG_ VCFRONT_autopilot2Fault m9 : 10|1@1+ (1,0) [0|1] "" Vector__XXX
 SG_ VCFRONT_autopilot2Temp m9 : 11|11@1+ (0.125,-40) [-40|150] "degC" Vector__XXX
 SG_ VCFRONT_autopilot2Voltage m9 : 27|16@1+ (0.1,0) [0|6553.5] "V" Vector__XXX
 SG_ VCFRONT_autopilot2Current m9 : 43|10@1+ (0.044,0) [0|45.012] "A" Vector__XXX
 SG_ VCFRONT_sleepBypassState m10 : 8|1@1+ (1,0) [0|1] "" Vector__XXX
 SG_ VCFRONT_sleepBypassFault m10 : 9|1@1+ (1,0) [0|1] "" Vector__XXX
 SG_ VCFRONT_sleepBypassVoltage m10 : 10|16@1+ (0.1,0) [0|6553.5] "V" Vector__XXX
 SG_ VCFRONT_sleepBypassCurrent m10 : 26|16@1+ (0.1,0) [0|6553.5] "A" Vector__XXX
 SG_ VCFRONT_vbatFusedHighState m13 : 8|1@1+ (1,0) [0|1] "" Vector__XXX
 SG_ VCFRONT_vbatFusedHighFault m13 : 9|1@1+ (1,0) [0|1] "" Vector__XXX
 SG_ VCFRONT_vbatFusedSelfTestResult m13 : 10|4@1+ (1,0) [0|15] "" Vector__XXX
 SG_ VCFRONT_vbatFusedHighTemp m13 : 14|11@1+ (0.125,-40) [-40|150] "degC" Vector__XXX
 SG_ VCFRONT_vbatFusedHighVoltage m13 : 30|16@1+ (0.1,0) [0|6553.5] "V" Vector__XXX
 SG_ VCFRONT_vbatFusedHighCurrent m13 : 46|16@1+ (0.1,0) [0|6553.5] "A" Vector__XXX
 SG_ VCFRONT_chargedIBSAmpHours m17 : 8|16@1+ (1,0) [0|65535] "Ah" Vector__XXX
 SG_ VCFRONT_dischargedIBSAmpHours m17 : 24|16@1+ (1,0) [0|65535] "Ah" Vector__XXX
 SG_ VCFRONT_IBSUnfilteredTemperature m17 : 40|16@1- (0.01,0) [-327.67|327.67] "degC" Vector__XXX

BO_ 1353 VCFRONT_homelink: 6 VCFRONT
 SG_ VCFRONT_homelinkV2Response0 : 0|8@1+ (1,0) [0|255] "" Vector__XXX
 SG_ VCFRONT_homelinkV2Response1 : 8|8@1+ (1,0) [0|255] "" Vector__XXX
 SG_ VCFRONT_homelinkV2Response2 : 16|8@1+ (1,0) [0|255] "" Vector__XXX
 SG_ VCFRONT_homelinkV2Response3 : 24|8@1+ (1,0) [0|255] "" Vector__XXX
 SG_ VCFRONT_homelinkV2Response4 : 32|8@1+ (1,0) [0|255] "" Vector__XXX
 SG_ VCFRONT_homelinkCommStatus : 40|2@1+ (1,0) [1|3] "" Vector__XXX

BO_TX_BU_ 947 : GTW;
BO_TX_BU_ 660 : GTW;
BO_TX_BU_ 1193 : GTW;
BO_TX_BU_ 853 : GTW;
BO_TX_BU_ 644 : GTW;
BO_TX_BU_ 595 : GTW;
BO_TX_BU_ 1285 : UMC;
BO_TX_BU_ 1949 : V2G;
BO_TX_BU_ 1858 : VCBATT1;
BO_TX_BU_ 1119 : VCBATT1;
BO_TX_BU_ 1030 : VCBATT1;
BO_TX_BU_ 1399 : VCBATT2;
BO_TX_BU_ 945 : VCBATT;
BO_TX_BU_ 1090 : VCBATT;
BO_TX_BU_ 1027 : VCFRONT1;
BO_TX_BU_ 609 : VCFRONT;
BO_TX_BU_ 1847 : VCFRONT;
BO_TX_BU_ 1140 : VCFRONT;
BO_TX_BU_ 1173 : VCFRONT;
BO_TX_BU_ 545 : VCFRONT;
BO_TX_BU_ 700 : VCFRONT;
BO_TX_BU_ 577 : VCFRONT;
BO_TX_BU_ 753 : VCFRONT;
BO_TX_BU_ 1353 : VCFRONT;
CM_ BO_ 947 "Touchscreen user interface computer message: vehicle control2; forwarded onto this bus by the gateway";
CM_ SG_ 947 UI_gloveboxRequest "UI request to open the glovebox";
CM_ SG_ 947 UI_trunkRequest "Rear trunk request";
CM_ SG_ 947 UI_PINToDriveEnabled "UI customer level request to pin to drive enabled.";
CM_ SG_ 947 UI_PINToDrivePassed "UI customer level request to enable drive with pin passed.";
CM_ SG_ 947 UI_disableMirrorAutoDim "Request to disable side and rear-view mirror auto dim";
CM_ SG_ 947 UI_lightSwitch "Headlight mode; raw 4 = signal not available (SNA)";
CM_ SG_ 947 UI_readyToAddKey "Ready to add key";
CM_ SG_ 947 UI_alarmTriggerRequest "Alarm activation request from UI";
CM_ SG_ 947 UI_displayOnForUser "User is present";
CM_ SG_ 947 UI_BLEPushNotificationRequest "Reports that the User Interface (UI) wants to talk to a phone and Vehicle Controller Security (VCSEC) should let all connected phones know.";
CM_ SG_ 947 UI_keepAutopilotAwake "Reports the request for Vehicle Controller (VC) to keep autopilot awake.";
CM_ SG_ 947 UI_batteryPreconditioningRequest "Requests battery preconditioning.";
CM_ SG_ 947 UI_autopilotPowerStateRequest "Requests different power states from autopilot ECU depending on feature usage.";
CM_ SG_ 947 UI_autoRollWindowsOnLockEnable "UI customer level request to enable auto-roll windows on lock";
CM_ SG_ 947 UI_steeringWheelHeatReq "Request to enable steering wheel heater";
CM_ SG_ 947 UI_disableHorn "Request to disable horn";
CM_ SG_ 947 UI_frontLeftSeatFanReq "Request for front left seat ventilation";
CM_ SG_ 947 UI_frontRightSeatAutoClimateReq "UI setting to enable auto seat heating and cooling for front right seat";
CM_ SG_ 947 UI_frontRightSeatFanReq "Request for front left seat ventilation";
CM_ SG_ 947 UI_frontLeftSeatAutoClimateReq "UI setting to enable auto seat heating and cooling for front left seat";
CM_ SG_ 947 UI_wiperHeaterReq "UI request to enable the wiper heater";
CM_ SG_ 947 UI_silentAlarm "Signal indicating alarms should be silenced";
CM_ BO_ 660 "Touchscreen user interface computer message: vehicle control3; forwarded onto this bus by the gateway";
CM_ SG_ 660 UI_lightFlashRequest "UI flash lights request";
CM_ SG_ 660 UI_phoneCallActive "On phone call via Bluetooth if active";
CM_ SG_ 660 UI_lightShowClosuresEnabled "Closure movements enabled during light show";
CM_ SG_ 660 UI_steeringWheelHeatAutoReq "UI setting to request auto steering wheel heat";
CM_ SG_ 660 UI_steeringWheelHeatLevelReq "Request for steering wheel heat";
CM_ SG_ 660 UI_headlightPulseRequest "Request headlights to pulse";
CM_ SG_ 660 UI_displayRedShiftActive "UI's reduce blue light setting is active";
CM_ SG_ 660 UI_fasciaCameraWashRequest "User request to activate fascia camera wash";
CM_ SG_ 660 UI_leftRearSeatAdjustmentRequest "Reports request from UI to actuate the left rear seat";
CM_ SG_ 660 UI_rightRearSeatAdjustmentReques "Reports request from UI to actuate the right rear seat";
CM_ SG_ 660 UI_blindSpotIndicatorLightReques "Request for blind spot indicator light";
CM_ SG_ 660 UI_keepOnAccessoryPortsReq "User setting to keep 12V outlets, USB ports, and phone chargers powered in CONDITIONING";
CM_ SG_ 660 UI_fasciaCameraShown "Whether the UI is currently showing the fascia camera view";
CM_ SG_ 660 UI_rearSeatChildLock "Reports the state of second row seat fold flat child lock from the UI";
CM_ SG_ 660 UI_windowPercentageRequest "Reports the window percentage value when window request is WINDOW_REQUEST_GOTO_PERCENT.";
CM_ SG_ 660 UI_windowRequestedFL "Reports that the front left window is requested.";
CM_ SG_ 660 UI_windowRequestedFR "Reports that the front right window is requested.";
CM_ SG_ 660 UI_windowRequestedRL "Reports that the rear left window is requested.";
CM_ SG_ 660 UI_windowRequestedRR "Reports that the rear right window is requested.";
CM_ SG_ 660 UI_windowRequest "Window operation request from the mobile app.";
CM_ SG_ 660 UI_closeTrunkRequest "Explicity request for the rear trunk to close";
CM_ SG_ 660 UI_childPresenceDetectionDisable "User request to disable child presence detection behaviors until the next drive cycle";
CM_ SG_ 660 UI_derivedLoadshedFeature "Reports whether vehicle controllers should enable derived loadshed feature.";
CM_ SG_ 660 UI_selfParkStandingBy "Reports that summon is in standby.";
CM_ BO_ 1193 "Touchscreen user interface computer message: vehicle control4; forwarded onto this bus by the gateway";
CM_ SG_ 1193 UI_firstRowLeftDomeLightRequest "Monitors the dome light switch for first row left side";
CM_ SG_ 1193 UI_firstRowRightDomeLightRequest "Monitors the dome light switch for first row right side";
CM_ SG_ 1193 UI_secondRowLeftDomeLightRequest "Monitors the dome light switch for second row left side";
CM_ SG_ 1193 UI_secondRowCenterDomeLightReque "Monitors the dome light switch for second row center side";
CM_ SG_ 1193 UI_secondRowRightDomeLightReques "Monitors the dome light switch for second row right side";
CM_ SG_ 1193 UI_thirdRowLeftDomeLightRequest "Monitors the dome light switch for third row left side";
CM_ SG_ 1193 UI_thirdRowRightDomeLightRequest "Monitors the dome light switch for third row right side";
CM_ BO_ 853 "Touchscreen user interface computer message: vehicle control thermal; forwarded onto this bus by the gateway";
CM_ SG_ 853 UI_coolantFlowRequest "request for coolant flow to MCU in LPM";
CM_ SG_ 853 UI_inletActiveCoolTarget "request for coolant temperature at Car Computer inlet";
CM_ SG_ 853 UI_disableHVPTThermalLoads "Request thermal system to disable active battery heating";
CM_ SG_ 853 UI_convenienceFeatureLimit "UI limit request in SOE (UI Gauge) for convenience features";
CM_ SG_ 853 UI_allowConvenienceFeatures "Whether UI allows convenenience features";
CM_ SG_ 853 UI_disablePhoneChargingPads "Reports requests from the User Interface (UI) to disable wireless phone charging.";
CM_ BO_ 644 "Touchscreen user interface computer message: vehicle modes; forwarded onto this bus by the gateway";
CM_ SG_ 644 UI_transportMode "Reports UI Transport mode. Distinct from GTW transport mode.";
CM_ SG_ 644 UI_showroomMode "Reports UI showroom mode.";
CM_ SG_ 644 UI_serviceMode "Service diagnostics mode active";
CM_ SG_ 644 UI_carWashMode "Car Wash Mode";
CM_ SG_ 644 UI_gameMode "Game mode";
CM_ SG_ 644 UI_serviceModePlus "Extended service diagnostics mode active";
CM_ SG_ 644 UI_premiumAmpPowerOff "Premium amplifier power off request";
CM_ SG_ 644 UI_lightShowType "Type of the light show to be run";
CM_ SG_ 644 UI_upkeepMode "Reports UI Upkeep Mode state.";
CM_ BO_ 595 "Touchscreen user interface computer message: vent panel control request; forwarded onto this bus by the gateway";
CM_ SG_ 595 UI_ventPanelControlRequestIndex "Touchscreen user interface computer: vent panel control request index";
CM_ SG_ 595 UI_ventPanelLeftPositionX "Airwave left X position.";
CM_ SG_ 595 UI_ventPanelLeftPositionY "Airwave left Y position.";
CM_ SG_ 595 UI_ventPanelLeftLateralSplit "Airwave left split amount.";
CM_ SG_ 595 UI_ventPanelRightPositionX "Airwave right X position.";
CM_ SG_ 595 UI_ventPanelRightPositionY "Airwave right Y position.";
CM_ SG_ 595 UI_ventPanelRightLateralSplit "Airwave right split amount.";
CM_ SG_ 595 UI_ventPanelLeftLateralMode "Airwave left focus or split.";
CM_ SG_ 595 UI_ventPanelRightLateralMode "Airwave right focus or split.";
CM_ SG_ 595 UI_hvacReqActiveVents "Active airwave sides - left/right/both";
CM_ SG_ 595 UI_vent2RLeftPositionX "Airwave left X position.";
CM_ SG_ 595 UI_vent2RLeftPositionY "Airwave left Y position.";
CM_ SG_ 595 UI_vent2RRightPositionX "Airwave left X position.";
CM_ SG_ 595 UI_vent2RRightPositionY "Airwave left Y position.";
CM_ SG_ 595 UI_hvacReqThirdRowState "Detects HVAC third row fan speed request.";
CM_ BO_ 1285 "UMC ECU message: smart adapter info";
CM_ SG_ 1285 SA_infoIndex "UMC ECU: info index";
CM_ SG_ 1285 SA_genealogyVersion "UMC ECU: genealogy version";
CM_ SG_ 1285 SA_genealogyCrc "UMC ECU: genealogy crc";
CM_ SG_ 1285 SA_region "Reports the smart adapter region from Electrically Erasable Programmable Read-Only Memory (EEPROM).";
CM_ SG_ 1285 SA_OverTempThreshold "Reports the smart adapter overtemperature threshold from Electrically Erasable Programmable Read-Only Memory (EEPROM).";
CM_ SG_ 1285 SA_partNumInt "Reports the smart adapter part number integer representation.";
CM_ SG_ 1285 SA_partNumRev "Reports the smart adapter part number revision.";
CM_ SG_ 1285 SA_currentLimit "Reports the smart adapter current limit from Electrically Erasable Programmable Read-Only Memory (EEPROM).";
CM_ SG_ 1285 SA_l1Voltage "Reports the smart adapter nominal voltage request from Electrically Erasable Programmable Read-Only Memory (EEPROM).";
CM_ BO_ 1949 "V2G ECU message: evse log data";
CM_ SG_ 1949 V2G_evseLogDataSelect "V2G ECU: evse log data select";
CM_ SG_ 1949 V2G_chgParamRes_respCode "Charge parameter response code reported by CCS DC charger";
CM_ SG_ 1949 V2G_chgParamRes_finished "V2G ECU: chg param res finished";
CM_ SG_ 1949 V2G_chgParamRes_evseStatus "Charge parameter discovery status reported by CCS DC charger";
CM_ SG_ 1949 V2G_chgParamRes_evseMaxILim "Maximum current limit reported by CCS DC charger in charge parameter discovery message";
CM_ SG_ 1949 V2G_chgParamRes_evseMaxVLim "Maximum voltage limit reported by CCS DC charger in charge parameter discovery message";
CM_ SG_ 1949 V2G_chgParamRes_evseMinILim "Minimum current limit reported by CCS DC charger in charge parameter discovery message";
CM_ SG_ 1949 V2G_chgParamRes_evseMinVLim "Minimum voltage limit reported by CCS DC charger in charge parameter discovery message";
CM_ SG_ 1949 V2G_chgParamRes_evseMaxPowerLim "Maximum power limit reported by CCS DC charger in charge parameter discovery message";
CM_ SG_ 1949 V2G_chgParamRes_evseMaxPower_val "Whether maximum power limit reported by CCS DC charger is valid in charge parameter discovery message";
CM_ SG_ 1949 V2G_chgParamRes_isoState "The EVSE's reported isolation status";
CM_ SG_ 1949 V2G_chgParamRes_isoState_val "The validity of the EVSE's reported isolation status";
CM_ BO_ 1858 "VCBATT1 ECU message: LVBMS status high";
CM_ SG_ 1858 VCBATT1_lvbmsStatusHighIndex "VCBATT1 ECU: lvbms status high index";
CM_ SG_ 1858 VCBATT1_LVBMS_packCurrent "Electrical current into the low voltage battery; raw 4194303 = signal not available (SNA)";
CM_ SG_ 1858 VCBATT1_LVBMS_packVoltage "Voltage of the low voltage battery; raw 65535 = signal not available (SNA)";
CM_ SG_ 1858 VCBATT1_LVBMS_packTemperature "Temperature of the low voltage battery; raw 511 = signal not available (SNA)";
CM_ SG_ 1858 VCBATT1_LVBMS_MOSTemperature "Temperature of the MOSFET on the low voltage battery; raw 4095 = signal not available (SNA)";
CM_ SG_ 1858 VCBATT1_LVBMS_sumCellVoltage "Sum of the cell voltage of the low voltage battery; raw 65535 = signal not available (SNA)";
CM_ SG_ 1858 VCBATT1_LVBMS_maxBrickVoltage "Maximum cell voltage in the low voltage battery; raw 8191 = signal not available (SNA)";
CM_ SG_ 1858 VCBATT1_LVBMS_maxBrickVoltageInd "VCBATT1 ECU: LVBMS max brick voltage index; raw 255 = signal not available (SNA)";
CM_ SG_ 1858 VCBATT1_totalLVLoadCurrent "Total LV load current of the vehicle.";
CM_ SG_ 1858 VCBATT1_LVPackChargeCurrentLimit "Charge current limit for the LV battery pack.";
CM_ SG_ 1858 VCBATT1_LVPackCurrent "Current of the LV battery pack.";
CM_ SG_ 1858 VCBATT1_LVBMS_estimatedPackOcv "VCBATT1 ECU: LVBMS estimated pack ocv";
CM_ SG_ 1858 VCBATT1_LVBMS_voltageTarget "Voltage target of the LV battery; raw 65535 = signal not available (SNA)";
CM_ SG_ 1858 VCBATT1_LVBMS_currentTarget "Target current requested by the LV battery; raw 262143 = signal not available (SNA)";
CM_ SG_ 1858 VCBATT1_LVBMS_maxAllowedChargeCu "Maximum allowed charge current of the battery; raw 8191 = signal not available (SNA)";
CM_ SG_ 1858 VCBATT1_LVBMS_maxAllowedDischarg "Maximum allowed discharge current of the battery; raw 8191 = signal not available (SNA)";
CM_ SG_ 1858 VCBATT1_LVBMS_MOSCommand "Current state of the MOS command to the LV battery";
CM_ SG_ 1858 VCBATT1_LVBMS_ClearErrorCntrComm "VCBATT1 ECU: LVBMS clear error cntr command";
CM_ SG_ 1858 VCBATT1_LVBMS_ClearHistoricFault "VCBATT1 ECU: LVBMS clear historic fault command";
CM_ SG_ 1858 VCBATT1_LVBMS_ResetLVBMSCommand "Reset command issued to LVBMS, commanded by VC";
CM_ SG_ 1858 VCBATT1_LVBMS_EnterHibernationCo "VCBATT1 ECU: LVBMS enter hibernation command";
CM_ SG_ 1858 VCBATT1_LVBMS_ECPAState "Current state of the E-CPA on the LV battery; raw 3 = signal not available (SNA)";
CM_ SG_ 1858 VCBATT1_LVBMS_MOSState "Current state of the MOS on the LV battery; raw 3 = signal not available (SNA)";
CM_ SG_ 1858 VCBATT1_LVBMS_VehicleState "VCBATT1 ECU: LVBMS vehicle state";
CM_ SG_ 1858 VCBATT1_LVBMS_LINWakeDisabled "VCBATT1 ECU: LVBMS LIN wake disabled";
CM_ SG_ 1858 VCBATT1_LVBMS_chargeType "VCBATT1 ECU: LVBMS charge type; raw 4 = signal not available (SNA)";
CM_ SG_ 1858 VCBATT1_LVBMS_cellAndArcProtEnab "Indicates whether the VC has commanded cell protections to be active";
CM_ SG_ 1858 VCBATT1_LVBMS_avgBrickVoltage "Average voltage of all cells in the low voltage battery; raw 8191 = signal not available (SNA)";
CM_ SG_ 1858 VCBATT1_LVBMS_minBrickVoltage "Minimum cell voltage in the low voltage battery; raw 8191 = signal not available (SNA)";
CM_ SG_ 1858 VCBATT1_LVBMS_minBrickVoltageInd "VCBATT1 ECU: LVBMS min brick voltage index; raw 255 = signal not available (SNA)";
CM_ BO_ 1119 "VCBATT1 ECU message: LV self tests";
CM_ SG_ 1119 VCBATT1_LVSelfTestsChecksum "VCBATT1 ECU: LV self tests checksum";
CM_ SG_ 1119 VCBATT1_LVSelfTestsCounter "VCBATT1 ECU: LV self tests counter";
CM_ SG_ 1119 VCBATT1_LVSelfTestsIndex "VCBATT1 ECU: LV self tests index";
CM_ SG_ 1119 VCBATT1_lvProtectionSelfTestsEna "VCBATT1 ECU: lv protection self tests enabled";
CM_ SG_ 1119 VCBATT1_startBattDomainOvercurre "VCBATT1 ECU: start batt domain overcurrent self test";
CM_ SG_ 1119 VCBATT1_startBattDomainOvervolta "VCBATT1 ECU: start batt domain overvoltage self test";
CM_ SG_ 1119 VCBATT1_startBattDomainUndervolt "VCBATT1 ECU: start batt domain undervoltage self test";
CM_ SG_ 1119 VCBATT1_startDualPowerLoadsSelfT "VCBATT1 ECU: start dual power loads self test";
CM_ SG_ 1119 VCBATT1_startVCBattBridgeEFuseAS "VCBATT1 ECU: start VC batt bridge e fuse ASIC self test";
CM_ SG_ 1119 VCBATT1_startPCSOVShutdownSelfTe "VCBATT1 ECU: start PCSOV shutdown self test";
CM_ SG_ 1119 VCBATT1_startPCSDomainOvervoltag "VCBATT1 ECU: start PCS domain overvoltage self test";
CM_ SG_ 1119 VCBATT1_startBattDomainUnde_0001 "VCBATT1 ECU: start batt domain undervoltage VC left self test";
CM_ SG_ 1119 VCBATT1_startPCSDomainUndervolta "VCBATT1 ECU: start PCS domain undervoltage self test";
CM_ SG_ 1119 VCBATT1_startVCFrontBridgeEFuseA "VCBATT1 ECU: start VC front bridge e fuse ASIC self test";
CM_ SG_ 1119 VCBATT1_battDomainOvercurrentSel "Self-Test Result.";
CM_ SG_ 1119 VCBATT1_battDomainOvercurre_0001 "Self-Test State.; raw 4 = signal not available (SNA)";
CM_ SG_ 1119 VCBATT1_battDomainOvervoltageSel "Self-Test Result.";
CM_ SG_ 1119 VCBATT1_battDomainOvervolta_0001 "Self-Test State.; raw 4 = signal not available (SNA)";
CM_ SG_ 1119 VCBATT1_battDomainUndervoltageSe "Self-Test Result.";
CM_ SG_ 1119 VCBATT1_battDomainUndervolt_0001 "Self-Test State.; raw 4 = signal not available (SNA)";
CM_ SG_ 1119 VCBATT1_dualPowerLoadsSelfTestRe "Self-Test Result.";
CM_ SG_ 1119 VCBATT1_dualPowerLoadsSelfTestSt "Self-Test State.; raw 4 = signal not available (SNA)";
CM_ SG_ 1119 VCBATT1_vcbattBridgeEFuseASICSel "Self-Test Result.";
CM_ SG_ 1119 VCBATT1_vcbattBridgeEFuseAS_0001 "Self-Test State.; raw 4 = signal not available (SNA)";
CM_ SG_ 1119 VCBATT1_uvProtectionState "VCBATT1 ECU: uv protection state";
CM_ SG_ 1119 VCBATT1_undervoltageSelfTestFaul "VCBATT1 ECU: undervoltage self test fault injection ready";
CM_ SG_ 1119 VC_selfTestsRunningMode "VCBATT1 ECU: self tests running mode";
CM_ BO_ 1030 "VCBATT1 ECU message: e fuse debug status";
CM_ SG_ 1030 VCBATT1_eFuseDebugStatusIndex "VCBATT1 ECU: e fuse debug status index";
CM_ SG_ 1030 VCBATT1_leftControllerEFuseState "VCBATT1 ECU: left controller e fuse state";
CM_ SG_ 1030 VCBATT1_leftControllerEFuseCurre "VCBATT1 ECU: left controller e fuse current";
CM_ SG_ 1030 VCBATT1_leftControllerEFuseOutpu "VCBATT1 ECU: left controller e fuse output";
CM_ SG_ 1030 VCBATT1_leftControllerEFuse_0002 "VCBATT1 ECU: left controller e fuse output desired";
CM_ SG_ 1030 VCBATT1_leftControllerEFuseBypas "VCBATT1 ECU: left controller e fuse bypass";
CM_ SG_ 1030 VCBATT1_leftControllerEFuse_0001 "VCBATT1 ECU: left controller e fuse bypass desired";
CM_ SG_ 1030 VCBATT1_leftControllerEFuseVolta "VCBATT1 ECU: left controller e fuse voltage";
CM_ SG_ 1030 VCBATT1_leftControllerEFuseTempe "VCBATT1 ECU: left controller e fuse temperature";
CM_ SG_ 1030 VCBATT1_leftControllerEFuseManag "VCBATT1 ECU: left controller e fuse manager state";
CM_ SG_ 1030 VCBATT1_leftControllerEFuseHardS "VCBATT1 ECU: left controller e fuse hard short threshold";
CM_ SG_ 1030 VCBATT1_leftControllerEFuseOCThr "VCBATT1 ECU: left controller e fuse OC threshold";
CM_ SG_ 1030 VCBATT1_leftControllerEFuseType "Reports the type of the left controller eFuse.";
CM_ SG_ 1030 VCBATT1_EPAS1EFuseState "VCBATT1 ECU: EPAS1 e fuse state";
CM_ SG_ 1030 VCBATT1_EPAS1EFuseCurrent "VCBATT1 ECU: EPAS1 e fuse current";
CM_ SG_ 1030 VCBATT1_EPAS1EFuseOutput "VCBATT1 ECU: EPAS1 e fuse output";
CM_ SG_ 1030 VCBATT1_EPAS1EFuseOutputDesired "VCBATT1 ECU: EPAS1 e fuse output desired";
CM_ SG_ 1030 VCBATT1_EPAS1EFuseBypass "VCBATT1 ECU: EPAS1 e fuse bypass";
CM_ SG_ 1030 VCBATT1_EPAS1EFuseBypassDesired "VCBATT1 ECU: EPAS1 e fuse bypass desired";
CM_ SG_ 1030 VCBATT1_EPAS1EFuseVoltage "VCBATT1 ECU: EPAS1 e fuse voltage";
CM_ SG_ 1030 VCBATT1_EPAS1EFuseTemperature "VCBATT1 ECU: EPAS1 e fuse temperature";
CM_ SG_ 1030 VCBATT1_EPAS1EFuseManagerState "VCBATT1 ECU: EPAS1 e fuse manager state";
CM_ SG_ 1030 VCBATT1_EPAS1EFuseHardShortThres "VCBATT1 ECU: EPAS1 e fuse hard short threshold";
CM_ SG_ 1030 VCBATT1_EPAS1EFuseOCThreshold "VCBATT1 ECU: EPAS1 e fuse OC threshold";
CM_ SG_ 1030 VCBATT1_EPAS1EFuseType "Reports the type of the EPAS1 eFuse.";
CM_ SG_ 1030 VCBATT1_autopilot1EFuseState "VCBATT1 ECU: autopilot1 e fuse state";
CM_ SG_ 1030 VCBATT1_autopilot1EFuseCurrent "VCBATT1 ECU: autopilot1 e fuse current";
CM_ SG_ 1030 VCBATT1_autopilot1EFuseOutput "VCBATT1 ECU: autopilot1 e fuse output";
CM_ SG_ 1030 VCBATT1_autopilot1EFuseOutputDes "VCBATT1 ECU: autopilot1 e fuse output desired";
CM_ SG_ 1030 VCBATT1_autopilot1EFuseBypass "VCBATT1 ECU: autopilot1 e fuse bypass";
CM_ SG_ 1030 VCBATT1_autopilot1EFuseBypassDes "VCBATT1 ECU: autopilot1 e fuse bypass desired";
CM_ SG_ 1030 VCBATT1_autopilot1EFuseVoltage "VCBATT1 ECU: autopilot1 e fuse voltage";
CM_ SG_ 1030 VCBATT1_autopilot1EFuseTemperatu "VCBATT1 ECU: autopilot1 e fuse temperature";
CM_ SG_ 1030 VCBATT1_autopilot1EFuseManagerSt "VCBATT1 ECU: autopilot1 e fuse manager state";
CM_ SG_ 1030 VCBATT1_autopilot1EFuseHardShort "VCBATT1 ECU: autopilot1 e fuse hard short threshold";
CM_ SG_ 1030 VCBATT1_autopilot1EFuseOCThresho "VCBATT1 ECU: autopilot1 e fuse OC threshold";
CM_ SG_ 1030 VCBATT1_autopilot1EFuseType "Reports the type of the autopilot1 eFuse.";
CM_ BO_ 1399 "VCBATT2 ECU message: logging10 hz";
CM_ SG_ 1399 VCBATT2_vehiclePowerStateDBG "VCBATT2 ECU: vehicle power state DBG";
CM_ SG_ 1399 VCBATT2_nmWakeUpReasonDBG "VCBATT2 ECU: nm wake up reason DBG";
CM_ SG_ 1399 VCBATT2_nmKeepAwakeReasonDBG "VCBATT2 ECU: nm keep awake reason DBG; raw 0 = signal not available (SNA)";
CM_ SG_ 1399 VCBATT2_LIN_bus_0_busErrorCount "LIN bus 0 (Thermal) HW bus error count";
CM_ SG_ 1399 VCBATT2_LIN_bus_1_busErrorCount "LIN bus 1 (Homelink/Headlamp) HW bus error count";
CM_ SG_ 1399 VCBATT2_hibernationStateDBG "VCBATT2 ECU: hibernation state DBG";
CM_ BO_ 945 "VCBATT ECU message: LV health";
CM_ SG_ 945 VCBATT_LVHealthChecksum "VCBATT ECU: LV health checksum";
CM_ SG_ 945 VCBATT_LVHealthCounter "VCBATT ECU: LV health counter";
CM_ SG_ 945 VCBATT_LVHealthStatus "Health status of the LV system";
CM_ SG_ 945 VCBATT_LVStatusForDrive "Status for drive based on health status of the LV system";
CM_ SG_ 945 VCBATT_LVPowerSecondsToSafeHarbo "Reports the amount of time (in seconds) the Low Voltage (LV) power system indicates the vehicle has to achieve safe harbor.";
CM_ SG_ 945 VCBATT_autonomyBehavior "Current autonomy mode and expected vehicle behaviors.";
CM_ SG_ 945 VCBATT_hardwareProtectionsArmed "Hardware protections armed";
CM_ SG_ 945 VCBATT_12vStatusForDrive "VCBATT ECU: 12v status for drive";
CM_ BO_ 1090 "VCBATT ECU message: pcs interface";
CM_ SG_ 1090 VCBATT_pcsInterfaceMuxIndex "VCBATT ECU: pcs interface mux index";
CM_ SG_ 1090 VCBATT_pcsInterfaceCounter "VCBATT ECU: pcs interface counter";
CM_ SG_ 1090 VCBATT_pcsInterfaceChecksum "VCBATT ECU: pcs interface checksum";
CM_ SG_ 1090 VCBATT_pcsLVVoltageTarget "VCBATT ECU: pcs LV voltage target";
CM_ SG_ 1090 VCBATT_pcsLVMinVoltageLimit "VCBATT ECU: pcs LV min voltage limit";
CM_ SG_ 1090 VCBATT_pcsLVMaxVoltageLimit "VCBATT ECU: pcs LV max voltage limit";
CM_ SG_ 1090 VCBATT_goodForPCSPowerCycle "VCBATT ECU: good for PCS power cycle";
CM_ SG_ 1090 VCBATT_LVBatteryCannotSupportVeh "VCBATT ECU: LV battery cannot support vehicle";
CM_ SG_ 1090 VCBATT_pcsResistanceFiltered "VCBATT ECU: pcs resistance filtered; raw 65535 = signal not available (SNA)";
CM_ SG_ 1090 VCBATT_pcsLVMaxDchrgCurrentLimit "VCBATT ECU: pcs LV max dchrg current limit";
CM_ SG_ 1090 VCBATT_defaultPcsLVVoltageTarget "VCBATT ECU: default pcs LV voltage target";
CM_ SG_ 1090 VCBATT_lvHwProtSelfTestActive "Reports whether Low Voltage (LV) Hardware (HW) protection self-tests are running or about to run due to a retry.";
CM_ SG_ 1090 VCBATT_lvBatteryDischargeRequest "VCBATT ECU: lv battery discharge request";
CM_ BO_ 1027 "VCFRONT1 ECU message: e fuse debug status";
CM_ SG_ 1027 VCFRONT1_eFuseDebugStatusIndex "VCFRONT1 ECU: e fuse debug status index";
CM_ SG_ 1027 VCFRONT1_EPAS2EFuseState "VCFRONT1 ECU: EPAS2 e fuse state";
CM_ SG_ 1027 VCFRONT1_EPAS2EFuseCurrent "VCFRONT1 ECU: EPAS2 e fuse current";
CM_ SG_ 1027 VCFRONT1_EPAS2EFuseOutput "VCFRONT1 ECU: EPAS2 e fuse output";
CM_ SG_ 1027 VCFRONT1_EPAS2EFuseOutputDesired "VCFRONT1 ECU: EPAS2 e fuse output desired";
CM_ SG_ 1027 VCFRONT1_EPAS2EFuseBypass "VCFRONT1 ECU: EPAS2 e fuse bypass";
CM_ SG_ 1027 VCFRONT1_EPAS2EFuseBypassDesired "VCFRONT1 ECU: EPAS2 e fuse bypass desired";
CM_ SG_ 1027 VCFRONT1_EPAS2EFuseVoltage "VCFRONT1 ECU: EPAS2 e fuse voltage";
CM_ SG_ 1027 VCFRONT1_EPAS2EFuseTemperature "VCFRONT1 ECU: EPAS2 e fuse temperature";
CM_ SG_ 1027 VCFRONT1_EPAS2EFuseManagerState "VCFRONT1 ECU: EPAS2 e fuse manager state";
CM_ SG_ 1027 VCFRONT1_EPAS2EFuseHardShortThre "VCFRONT1 ECU: EPAS2 e fuse hard short threshold";
CM_ SG_ 1027 VCFRONT1_EPAS2EFuseOCThreshold "VCFRONT1 ECU: EPAS2 e fuse OC threshold";
CM_ SG_ 1027 VCFRONT1_EPAS2EFuseType "Reports the type of the EPAS2 eFuse.";
CM_ SG_ 1027 VCFRONT1_rightControllerEFuseSta "VCFRONT1 ECU: right controller e fuse state";
CM_ SG_ 1027 VCFRONT1_rightControllerEFuseCur "VCFRONT1 ECU: right controller e fuse current";
CM_ SG_ 1027 VCFRONT1_rightControllerEFuseOut "VCFRONT1 ECU: right controller e fuse output";
CM_ SG_ 1027 VCFRONT1_rightControllerEFu_0002 "VCFRONT1 ECU: right controller e fuse output desired";
CM_ SG_ 1027 VCFRONT1_rightControllerEFuseByp "VCFRONT1 ECU: right controller e fuse bypass";
CM_ SG_ 1027 VCFRONT1_rightControllerEFu_0001 "VCFRONT1 ECU: right controller e fuse bypass desired";
CM_ SG_ 1027 VCFRONT1_rightControllerEFuseVol "VCFRONT1 ECU: right controller e fuse voltage";
CM_ SG_ 1027 VCFRONT1_rightControllerEFuseTem "VCFRONT1 ECU: right controller e fuse temperature";
CM_ SG_ 1027 VCFRONT1_rightControllerEFuseMan "VCFRONT1 ECU: right controller e fuse manager state";
CM_ SG_ 1027 VCFRONT1_rightControllerEFuseHar "VCFRONT1 ECU: right controller e fuse hard short threshold";
CM_ SG_ 1027 VCFRONT1_rightControllerEFuseOCT "VCFRONT1 ECU: right controller e fuse OC threshold";
CM_ SG_ 1027 VCFRONT1_rightControllerEFuseTyp "Reports the type of the right controller eFuse.";
CM_ SG_ 1027 VCFRONT1_autopilot2EFuseState "VCFRONT1 ECU: autopilot2 e fuse state";
CM_ SG_ 1027 VCFRONT1_autopilot2EFuseCurrent "VCFRONT1 ECU: autopilot2 e fuse current";
CM_ SG_ 1027 VCFRONT1_autopilot2EFuseOutput "VCFRONT1 ECU: autopilot2 e fuse output";
CM_ SG_ 1027 VCFRONT1_autopilot2EFuseOutputDe "VCFRONT1 ECU: autopilot2 e fuse output desired";
CM_ SG_ 1027 VCFRONT1_autopilot2EFuseBypass "VCFRONT1 ECU: autopilot2 e fuse bypass";
CM_ SG_ 1027 VCFRONT1_autopilot2EFuseBypassDe "VCFRONT1 ECU: autopilot2 e fuse bypass desired";
CM_ SG_ 1027 VCFRONT1_autopilot2EFuseVoltage "VCFRONT1 ECU: autopilot2 e fuse voltage";
CM_ SG_ 1027 VCFRONT1_autopilot2EFuseTemperat "VCFRONT1 ECU: autopilot2 e fuse temperature";
CM_ SG_ 1027 VCFRONT1_autopilot2EFuseManagerS "VCFRONT1 ECU: autopilot2 e fuse manager state";
CM_ SG_ 1027 VCFRONT1_autopilot2EFuseHardShor "VCFRONT1 ECU: autopilot2 e fuse hard short threshold";
CM_ SG_ 1027 VCFRONT1_autopilot2EFuseOCThresh "VCFRONT1 ECU: autopilot2 e fuse OC threshold";
CM_ SG_ 1027 VCFRONT1_autopilot2EFuseType "Reports the type of the autopilot2 eFuse.";
CM_ BO_ 609 "Front body controller message: 12 v battery status";
CM_ SG_ 609 VCFRONT_12VBatteryStatusIndex "Front body controller: 12 v battery status index";
CM_ SG_ 609 VCFRONT_good12VforUpdate "Indicates the Low Voltage (LV) battery health as it pertains to permitting an Over-The-Air (OTA) update.";
CM_ SG_ 609 VCFRONT_LVLoadRequest "Controls the loading of the Low Voltage (LV) battery for diagnostic purposes.";
CM_ SG_ 609 VCFRONT_12VBatteryStatusCounter "Front body controller: 12 v battery status counter";
CM_ SG_ 609 VCFRONT_12VBatteryStatusChecksum "Front body controller: 12 v battery status checksum";
CM_ SG_ 609 VCFRONT_batterySupportRequest "Reports the request to the Power Conversion System (PCS) to supply power to the Low Voltage (LV) battery.";
CM_ SG_ 609 VCFRONT_batterySMState "Reports the Low Voltage (LV) battery maintenance state machine state.";
CM_ SG_ 609 VCFRONT_eFuseRecoveryStateDBG "Reports the state of the Low Voltage (LV) battery eFuse recovery state machine.";
CM_ SG_ 609 VCFRONT_batteryLINScheduleDBG "Front body controller: battery LIN schedule DBG; raw 7 = signal not available (SNA)";
CM_ SG_ 609 VCFRONT_resistanceEstimationTest "Front body controller: resistance estimation test counter";
CM_ SG_ 609 VCFRONT_IBSCurrent "Electrical current into the 12V battery";
CM_ SG_ 609 VCFRONT_IBSVoltage "Voltage of the 12V battery; raw 4095 = signal not available (SNA)";
CM_ SG_ 609 VCFRONT_reverseBatteryFault "Indicates a fault on the reverse battery eFuse.";
CM_ SG_ 609 VCFRONT_LVBatterySupported "Indicates whether the Low Voltage (LV) battery is being supported.";
CM_ SG_ 609 VCFRONT_LVBatteryCannotSupportVe "Front body controller: LV battery cannot support vehicle";
CM_ SG_ 609 VCFRONT_goodTemp12VforUpdate "Front body controller: good temp12 vfor update";
CM_ SG_ 609 VCFRONT_12VBatteryTargetVoltage "Reports the target Low Voltage (LV) battery voltage.";
CM_ SG_ 609 VCFRONT_IBSTemperature "Front body controller: IBS temperature; raw 2047 = signal not available (SNA)";
CM_ SG_ 609 VCFRONT_currentSensorMismatchLea "Front body controller: current sensor mismatch leaky bkt pct DBG";
CM_ SG_ 609 VCFRONT_LVBatteryEnergyRemaining "Reports the percentage of energy remaining in the Low Voltage (LV) battery.";
CM_ SG_ 609 VCFRONT_LVBatteryStatusForDrive "Indicates the Low Voltage (LV) battery health status as it pertains to drive readiness. May trigger a Graceful Power Off (GPO) and block drive.";
CM_ SG_ 609 VCFRONT_LVBatteryType "Reports the type of Low Voltage (LV) battery that the firmware is configured for.";
CM_ SG_ 609 VCFRONT_resistanceEstimationNeed "Indication that the conditions which require a resistance estimation test to be performed have been met";
CM_ SG_ 609 VCFRONT_IBSVoltageFiltered "Measures the filtered voltage of the Low Voltage (LV) bus.; raw 16383 = signal not available (SNA)";
CM_ SG_ 609 VCFRONT_LVBMS_LVBusVoltageSource "Reports the source of the Low Voltage (LV) bus voltage used for the Low Voltage Battery Management System (LVBMS).";
CM_ SG_ 609 VCFRONT_LVBMS_LVPackCurrentSourc "Reports the source of the Low Voltage (LV) pack current used for LV battery charge regulation.";
CM_ SG_ 609 VCFRONT_LVBatterySupportRqrdTrig "Reports what caused the Low Voltage (LV) battery support required trigger when the vehicle wakes to charge.";
CM_ SG_ 609 VCFRONT_goodForPCSPowerCycleLeak "Front body controller: good for PCS power cycle leaky bkt DBG";
CM_ SG_ 609 VCFRONT_LVBusControlsFutile "Indicates that a required condition is not met for the Low Voltage (LV) bus controllers to operate properly.";
CM_ SG_ 609 VCFRONT_resistanceEstimatio_0001 "Front body controller: resistance estimation test valid";
CM_ SG_ 609 VCFRONT_resistanceEstimatio_0002 "Front body controller: resistance estimation tests expended";
CM_ SG_ 609 VCFRONT_goodLVChargeForUpdate "Indicates that the Low Voltage (LV) battery charge is sufficient to permit an Over-The-Air (OTA) update.";
CM_ SG_ 609 VCFRONT_opportunisticDCRTestNeed "Front body controller: opportunistic DCR test needed";
CM_ SG_ 609 VCFRONT_voltageProfile "Indicates which voltage profile is used to support the 12V battery";
CM_ SG_ 609 VCFRONT_IBSAmpHours "Measures the energy state of the Low Voltage (LV) battery in amp hours.";
CM_ SG_ 609 VCFRONT_IBSVoltageRawDBG "Front body controller: IBS voltage raw DBG; raw 16383 = signal not available (SNA)";
CM_ SG_ 609 VCFRONT_LVBatteryLINCommsDetecte "Front body controller: LV battery LIN comms detected DBG";
CM_ SG_ 609 VCFRONT_voltageSensorMismatchLea "Front body controller: voltage sensor mismatch leaky bkt pct DBG";
CM_ SG_ 609 VCFRONT_LVBusControlMode "Front body controller: LV bus control mode";
CM_ SG_ 609 VCFRONT_resistanceEstimationExte "Front body controller: resistance estimation extended test enabled";
CM_ SG_ 609 VCFRONT_LVBatteryFctryLimOverrid "Front body controller: LV battery fctry lim override ok";
CM_ SG_ 609 VCFRONT_LVBatterySPICommsDetecte "Front body controller: LV battery SPI comms detected DBG";
CM_ SG_ 609 VCFRONT_targetCurrent "Reports the target current set by the Low Voltage Battery Management System (LVBMS).";
CM_ SG_ 609 VCFRONT_PCSMia "Indicates that the Power Conversion System (PCS) is not communicating on CAN.";
CM_ SG_ 609 VCFRONT_chargeNeeded "Indicates that the Low Voltage (LV) battery needs to be charged.";
CM_ SG_ 609 VCFRONT_voltageControlLoopIntegr "Front body controller: voltage control loop integration val";
CM_ SG_ 609 VCFRONT_currentControlLoopIntegr "Front body controller: current control loop integration val";
CM_ BO_ 1847 "Front body controller message: LVBMS info";
CM_ SG_ 1847 VCFRONT_LVBMS_InfoIndex "Front body controller: LVBMS info index";
CM_ SG_ 1847 VCFRONT_LVBMS_PcbaId "Front body controller: LVBMS pcba id";
CM_ SG_ 1847 VCFRONT_LVBMS_AssemblyId "Front body controller: LVBMS assembly id";
CM_ SG_ 1847 VCFRONT_LVBMS_SubUsageId "LVBMS Sub Usage ID; raw 65535 = signal not available (SNA)";
CM_ SG_ 1847 VCFRONT_LVBMS_UsageId "Front body controller: LVBMS usage id";
CM_ SG_ 1847 VCFRONT_LVBMS_AppCRC "LVBMS application cyclic redundancy check";
CM_ SG_ 1847 VCFRONT_LVBMS_FWBuildType "Front body controller: LVBMS FW build type";
CM_ BO_ 1140 "Front body controller message: LV health";
CM_ SG_ 1140 VCFRONT_LVHealthChecksum "Front body controller: LV health checksum";
CM_ SG_ 1140 VCFRONT_LVHealthCounter "Front body controller: LV health counter";
CM_ SG_ 1140 VCFRONT_LVHealthStatus "Health status of the LV system";
CM_ SG_ 1140 VCFRONT_LVStatusForDrive "Front body controller: LV status for drive";
CM_ SG_ 1140 VCFRONT_LVPowerSecondsToSafeHarb "Reports the amount of time (in seconds) the Low Voltage (LV) power system indicates the vehicle has to achieve safe harbor.";
CM_ SG_ 1140 VCFRONT_hardwareProtectionsArmed "Front body controller: hardware protections armed";
CM_ SG_ 1140 VCFRONT_lockoutStrategy "Front body controller: lockout strategy";
CM_ BO_ 1173 "Front body controller message: LV health debug";
CM_ SG_ 1173 VCFRONT_LVHealthDebugIndex "Front body controller: LV health debug index";
CM_ SG_ 1173 VCFRONT_LVHEALTH_placeholder "Whether the LV health has determined that the <placeholder>";
CM_ SG_ 1173 VCFRONT_LVHEALTH_activeDecelEner "Whether the VCFRONT cannot confirm that the battery has sufficient energy to support an active decel scenario";
CM_ SG_ 1173 VCFRONT_LVHEALTH_criticalPullove "Whether the VCFRONT cannot confirm that the battery has sufficient energy to support a critical pullover scenario";
CM_ SG_ 1173 VCFRONT_LVHEALTH_revBattEFuseOff "Whether the LV health has determined that the LVBMB EFuse has opened";
CM_ SG_ 1173 VCFRONT_LVHEALTH_LVBMBEFuseOpen "Whether the LV health has determined that the LVBMB EFuse has opened";
CM_ SG_ 1173 VCFRONT_LVHEALTH_lvBatteryCommsM "Whether the LV health has determined that LV battery communications are missing";
CM_ SG_ 1173 VCFRONT_LVHEALTH_pcsEFuseOff "Whether VCFRONT has determined that the PCS eFuse is off or faulted when it's needed to be on";
CM_ SG_ 1173 VCFRONT_LVHEALTH_pcsNotActive "Whether the LV health has determined that the PCS is not actively providing LV support";
CM_ SG_ 1173 VCFRONT_LVHEALTH_pcsMIA "Whether the LV health has determined that messages are missing from PCS critical for determining health";
CM_ SG_ 1173 VCFRONT_LVHEALTH_IBSMIA "Whether the LV health has determined that the INA228 LV battery sensor signals are invalid or not yet configured";
CM_ SG_ 1173 VCFRONT_LVHEALTH_LVBatteryElecDi "Whether the VCFRONT has determined that the LV battery is electrically disconnected";
CM_ SG_ 1173 VCFRONT_LVHEALTH_LVBatteryE_0001 "Whether the VCFRONT has determined that the LV battery electrical connection status has been unknown for too long";
CM_ SG_ 1173 VCFRONT_LVHEALTH_pcsOpenCircuit "Whether VCFRONT has determined that the electrical connection between the PCS and VCFRONT is disconnected";
CM_ SG_ 1173 VCFRONT_LVHEALTH_activeDecelPowe "Whether the VCFRONT cannot confirm that the battery has sufficient power to support a active decel scenario";
CM_ SG_ 1173 VCFRONT_LVHEALTH_lvBatteryCapabi "Whether the LV health has determined that LV battery power/energy capability estimation accuracy is too low";
CM_ SG_ 1173 VCFRONT_LVHEALTH_lvBatteryConfig "Whether the LV health has determined that LV battery configuration is incorrect";
CM_ SG_ 1173 VCFRONT_LVHEALTH_lvBatteryImpeda "Whether the LV health has determined that LV battery impedance is too high";
CM_ SG_ 1173 VCFRONT_LVHEALTH_lvBatteryExtend "Whether the LV health has determined that an extended over voltage event has occurred";
CM_ BO_ 545 "Front body controller message: LV power state";
CM_ SG_ 545 VCFRONT_LVPowerStateIndex "Front body controller: LV power state index";
CM_ SG_ 545 VCFRONT_vehiclePowerState "Front body controller: vehicle power state";
CM_ SG_ 545 VCFRONT_inAccessoryPlus "Front body controller: in accessory plus";
CM_ SG_ 545 VCFRONT_LVShuttingDown "Front body controller: LV shutting down";
CM_ SG_ 545 VCFRONT_LVPowerStateCounter "Front body controller: LV power state counter";
CM_ SG_ 545 VCFRONT_LVPowerStateChecksum "Front body controller: LV power state checksum";
CM_ SG_ 545 VCFRONT_cpLVRequest "Front body controller: cp LV request";
CM_ SG_ 545 VCFRONT_epasLVState "Front body controller: epas LV state";
CM_ SG_ 545 VCFRONT_hvcLVRequest "Front body controller: hvc LV request";
CM_ SG_ 545 VCFRONT_tasLVState "Front body controller: tas LV state";
CM_ SG_ 545 VCFRONT_pcsLVState "Front body controller: pcs LV state";
CM_ SG_ 545 VCFRONT_CMPDLVState "Front body controller: CMPDLV state";
CM_ SG_ 545 VCFRONT_hcmlLVState "Front body controller: hcml LV state";
CM_ SG_ 545 VCFRONT_hcmrLVState "Front body controller: hcmr LV state";
CM_ SG_ 545 VCFRONT_MCUAudioLVState "Front body controller: MCU audio LV state";
CM_ SG_ 545 VCFRONT_espValveLVState "Front body controller: esp valve LV state";
CM_ SG_ 545 VCFRONT_MCUGraphicsLVState "Front body controller: MCU graphics LV state";
CM_ SG_ 545 VC_dcdcSupportRequest "Front body controller: dcdc support request";
CM_ SG_ 545 VC_hvStateRequest "Reports the request for the High Voltage (HV) system state.";
CM_ SG_ 545 VC_autonomyBehavior "Current autonomy mode and expected vehicle behaviors.";
CM_ SG_ 545 VC_persistAccPowerRequestOverrid "Front body controller: persist acc power request overridden";
CM_ SG_ 545 VC_accPortPowerRequest "Front body controller: acc port power request";
CM_ SG_ 545 VC_persistAccPortPowerState "Front body controller: persist acc port power state";
CM_ SG_ 545 VC_noAccDeviceDetectedWhileIdle "Front body controller: no acc device detected while idle";
CM_ BO_ 700 "Front body controller message: LV thermal motors10 hz";
CM_ SG_ 700 VCFRONT_LVThermalMotorsIndex "Front body controller: LV thermal motors index";
CM_ SG_ 700 VCFRONT_radiatorFanState "Radiator Fan motor controller state";
CM_ SG_ 700 VCFRONT_radiatorFanTorque "Radiator Fan motor torque; raw 1023 = signal not available (SNA)";
CM_ SG_ 700 VCFRONT_radiatorFanIDc "Radiator Fan DC current; raw 127 = signal not available (SNA)";
CM_ SG_ 700 VCFRONT_mlxLINCurrentSchedule "Currently set schedule for MLX LIN bus";
CM_ SG_ 700 VCFRONT_pumpPowertrainState "Powertrain Pump motor controller state";
CM_ SG_ 700 VCFRONT_pumpPowertrainTorque "Powertrain Pump motor torque; raw 1023 = signal not available (SNA)";
CM_ SG_ 700 VCFRONT_pumpPowertrainIDc "Powertrain Pump DC current; raw 127 = signal not available (SNA)";
CM_ SG_ 700 VCFRONT_pumpBatteryState "Battery Pump motor controller state";
CM_ SG_ 700 VCFRONT_pumpBatteryTorque "Battery Pump motor torque; raw 1023 = signal not available (SNA)";
CM_ SG_ 700 VCFRONT_pumpBatteryIDc "Battery Pump DC current; raw 127 = signal not available (SNA)";
CM_ BO_ 577 "Front body controller message: coolant";
CM_ SG_ 577 VCFRONT_coolantFlowBatActual "Front body controller: coolant flow bat actual";
CM_ SG_ 577 VCFRONT_coolantFlowBatTarget "Front body controller: coolant flow bat target";
CM_ SG_ 577 VCFRONT_coolantFlowBatReason "Front body controller: coolant flow bat reason";
CM_ SG_ 577 VCFRONT_coolantFlowPTActual "Front body controller: coolant flow PT actual";
CM_ SG_ 577 VCFRONT_coolantFlowPTTarget "Front body controller: coolant flow PT target";
CM_ SG_ 577 VCFRONT_coolantFlowPTReason "Front body controller: coolant flow PT reason";
CM_ SG_ 577 VCFRONT_wasteHeatRequestType "Front body controller: waste heat request type";
CM_ SG_ 577 VCFRONT_coolantHasBeenFilled "Front body controller: coolant has been filled";
CM_ SG_ 577 VCFRONT_radiatorIneffective "Indication that the efficiency of the radiator is reduced";
CM_ SG_ 577 VCFRONT_coolantAirPurgeBatState "Front body controller: coolant air purge bat state";
CM_ SG_ 577 VCFRONT_coolantFlowTableConfig "Front body controller: coolant flow table config";
CM_ SG_ 577 VCFRONT_coolantLevelContinuously "Front body controller: coolant level continuously low";
CM_ BO_ 753 "Front body controller message: e fuse debug status";
CM_ SG_ 753 VCFRONT_eFuseDebugStatusIndex "Front body controller: e fuse debug status index";
CM_ SG_ 753 VCFRONT_leftControllerState "Front body controller: left controller state; raw 3 = signal not available (SNA)";
CM_ SG_ 753 VCFRONT_leftControllerFault "Front body controller: left controller fault";
CM_ SG_ 753 VCFRONT_vcleftSelfTestResult "Reports the result of the most recent self-test of the Vehicle Controller Left (VCLEFT) eFuse.; raw 12 = signal not available (SNA)";
CM_ SG_ 753 VCFRONT_leftControllerTemp "Front body controller: left controller temp";
CM_ SG_ 753 VCFRONT_leftControllerEFuseVNFSt "State of the leftController eFuse";
CM_ SG_ 753 VCFRONT_leftControllerEFuseOutpu "Output state of the leftController efuse";
CM_ SG_ 753 VCFRONT_leftControllerEFuse_0002 "Output of the leftController efuse";
CM_ SG_ 753 VCFRONT_leftControllerVoltage "Front body controller: left controller voltage";
CM_ SG_ 753 VCFRONT_leftControllerEFuseBypas "Bypass output state of the leftController efuse";
CM_ SG_ 753 VCFRONT_leftControllerEFuse_0001 "Bypass output of the leftController efuse";
CM_ SG_ 753 VCFRONT_leftControllerCurrent "Front body controller: left controller current";
CM_ SG_ 753 VCFRONT_leftControllerEFuseVNFSe "Front body controller: left controller e fuse VNF self test status";
CM_ SG_ 753 VCFRONT_PCSState "Front body controller: PCS state; raw 3 = signal not available (SNA)";
CM_ SG_ 753 VCFRONT_PCSFault "Front body controller: PCS fault";
CM_ SG_ 753 VCFRONT_pcsSelfTestResult "Reports the result of the most recent self-test of the Power Conversion System (PCS) eFuse.; raw 12 = signal not available (SNA)";
CM_ SG_ 753 VCFRONT_PCSTemp "Front body controller: PCS temp";
CM_ SG_ 753 VCFRONT_PCSEFuseVNFState "State of the PCS eFuse";
CM_ SG_ 753 VCFRONT_PCSEFuseOutput "Output state of the PCS efuse";
CM_ SG_ 753 VCFRONT_PCSEFuseOutputDesired "Output of the PCS efuse";
CM_ SG_ 753 VCFRONT_PCSVoltage "Voltage of the power conversion system circuit";
CM_ SG_ 753 VCFRONT_PCSEFuseBypass "Bypass output state of the PCS efuse";
CM_ SG_ 753 VCFRONT_PCSEFuseBypassDesired "Bypass output of the PCS efuse";
CM_ SG_ 753 VCFRONT_PCSEFuseVNFSelfTestStatu "Front body controller: PCSE fuse VNF self test status";
CM_ SG_ 753 VCFRONT_iBoosterState "Front body controller: i booster state; raw 3 = signal not available (SNA)";
CM_ SG_ 753 VCFRONT_iBoosterFault "Front body controller: i booster fault";
CM_ SG_ 753 VCFRONT_iBoosterSelfTestResult "Reports the result of the most recent self-test of the iBooster eFuse.; raw 12 = signal not available (SNA)";
CM_ SG_ 753 VCFRONT_iBoosterTemp "Front body controller: i booster temp";
CM_ SG_ 753 VCFRONT_iBoosterEFuseVNFState "State of the IBooster eFuse";
CM_ SG_ 753 VCFRONT_iBoosterEFuseOutput "Output state of the IBooster efuse";
CM_ SG_ 753 VCFRONT_iBoosterEFuseOutputDesir "Output of the IBooster efuse";
CM_ SG_ 753 VCFRONT_iBoosterVoltage "Front body controller: i booster voltage";
CM_ SG_ 753 VCFRONT_iBoosterHardshortThresho "Front body controller: i booster hardshort threshold dbg";
CM_ SG_ 753 VCFRONT_iBoosterEFuseBypass "Bypass output state of the IBooster efuse";
CM_ SG_ 753 VCFRONT_iBoosterEFuseBypassDesir "Bypass output of the IBooster efuse";
CM_ SG_ 753 VCFRONT_iBoosterCurrent "Front body controller: i booster current";
CM_ SG_ 753 VCFRONT_iBoosterEFuseVNFSelfTest "Front body controller: i booster e fuse VNF self test status";
CM_ SG_ 753 VCFRONT_EPAS3PState "State of the primary power steering circuit; raw 3 = signal not available (SNA)";
CM_ SG_ 753 VCFRONT_EPAS3PFault "Front body controller: EPAS3 p fault";
CM_ SG_ 753 VCFRONT_EPAS3PSelfTestResult "Reports the result of the most recent self-test of the Electric Power Assisted Steering Primary (EPAS3P) eFuse.; raw 12 = signal not available (SNA)";
CM_ SG_ 753 VCFRONT_EPAS3PTemp "Front body controller: EPAS3 p temp";
CM_ SG_ 753 VCFRONT_EPAS3PEFuseVNFState "State of the EPAS3P eFuse";
CM_ SG_ 753 VCFRONT_EPAS3PEFuseOutput "Output state of the EPAS3P efuse";
CM_ SG_ 753 VCFRONT_EPAS3PEFuseOutputDesired "Output of the EPAS3P efuse";
CM_ SG_ 753 VCFRONT_EPAS3PVoltage "Voltage of the primary power steering circuit";
CM_ SG_ 753 VCFRONT_EPAS3PEFuseHardshortThre "Front body controller: EPAS3 PE fuse hardshort threshold dbg";
CM_ SG_ 753 VCFRONT_EPAS3PEFuseBypass "Bypass output state of the EPAS3P efuse";
CM_ SG_ 753 VCFRONT_EPAS3PEFuseBypassDesired "Bypass output of the EPAS3P efuse";
CM_ SG_ 753 VCFRONT_EPAS3PCurrent "Electrical current of the primary power steering circuit";
CM_ SG_ 753 VCFRONT_EPAS3PEFuseVNFSelfTestSt "Front body controller: EPAS3 PE fuse VNF self test status";
CM_ SG_ 753 VCFRONT_EPAS3SState "State of the secondary power steering circuit; raw 3 = signal not available (SNA)";
CM_ SG_ 753 VCFRONT_EPAS3SFault "Front body controller: EPAS3 s fault";
CM_ SG_ 753 VCFRONT_EPAS3SSelfTestResult "Reports the result of the most recent self-test of the Electric Power Assisted Steering Secondary (EPAS3S) eFuse.; raw 12 = signal not available (SNA)";
CM_ SG_ 753 VCFRONT_EPAS3STemp "Front body controller: EPAS3 s temp";
CM_ SG_ 753 VCFRONT_EPAS3SEFuseVNFState "State of the EPAS3S eFuse";
CM_ SG_ 753 VCFRONT_EPAS3SEFuseOutput "Output state of the EPAS3S efuse";
CM_ SG_ 753 VCFRONT_EPAS3SEFuseOutputDesired "Output of the EPAS3S efuse";
CM_ SG_ 753 VCFRONT_EPAS3SVoltage "Voltage of the secondary power steering circuit";
CM_ SG_ 753 VCFRONT_EPAS3SEFuseBypass "Bypass output state of the EPAS3S efuse";
CM_ SG_ 753 VCFRONT_EPAS3SEFuseBypassDesired "Bypass output of the EPAS3S efuse";
CM_ SG_ 753 VCFRONT_EPAS3SCurrent "Electrical current of the secondary power steering circuit";
CM_ SG_ 753 VCFRONT_EPAS3SEFuseVNFSelfTestSt "Front body controller: EPAS3 SE fuse VNF self test status";
CM_ SG_ 753 VCFRONT_ESPMotorState "Front body controller: ESP motor state; raw 3 = signal not available (SNA)";
CM_ SG_ 753 VCFRONT_ESPMotorFault "Front body controller: ESP motor fault";
CM_ SG_ 753 VCFRONT_ESPMotorSelfTestResult "Reports the result of the most recent self-test of the Electronic Stability Program Motor (ESP Motor) eFuse.; raw 12 = signal not available (SNA)";
CM_ SG_ 753 VCFRONT_ESPMotorTemp "Front body controller: ESP motor temp";
CM_ SG_ 753 VCFRONT_ESPMotorEFuseVNFState "State of the ESPMotor eFuse";
CM_ SG_ 753 VCFRONT_ESPMotorEFuseOutput "Output state of the ESPMotor efuse";
CM_ SG_ 753 VCFRONT_ESPMotorEFuseOutputDesir "Output of the ESPMotor efuse";
CM_ SG_ 753 VCFRONT_ESPMotorVoltage "Front body controller: ESP motor voltage";
CM_ SG_ 753 VCFRONT_ESPMotorEFuseBypass "Bypass output state of the ESPMotor efuse";
CM_ SG_ 753 VCFRONT_ESPMotorEFuseBypassDesir "Bypass output of the ESPMotor efuse";
CM_ SG_ 753 VCFRONT_ESPMotorCurrent "Front body controller: ESP motor current";
CM_ SG_ 753 VCFRONT_ESPMotorEFuseVNFSelfTest "Front body controller: ESP motor e fuse VNF self test status";
CM_ SG_ 753 VCFRONT_ESPValveState "State of the stability controller motor circuit; raw 3 = signal not available (SNA)";
CM_ SG_ 753 VCFRONT_ESPValveFault "Front body controller: ESP valve fault";
CM_ SG_ 753 VCFRONT_ESPValveTemp "Front body controller: ESP valve temp";
CM_ SG_ 753 VCFRONT_ESPValveVoltage "Front body controller: ESP valve voltage";
CM_ SG_ 753 VCFRONT_ESPValveCurrent "Electrical current of the stability controller motor circuit";
CM_ SG_ 753 VCFRONT_autopilot2State "Front body controller: autopilot2 state; raw 3 = signal not available (SNA)";
CM_ SG_ 753 VCFRONT_autopilot2Fault "Front body controller: autopilot2 fault";
CM_ SG_ 753 VCFRONT_autopilot2Temp "Front body controller: autopilot2 temp";
CM_ SG_ 753 VCFRONT_autopilot2Voltage "Front body controller: autopilot2 voltage";
CM_ SG_ 753 VCFRONT_autopilot2Current "Front body controller: autopilot2 current";
CM_ SG_ 753 VCFRONT_sleepBypassState "State of the sleep bypass circuit";
CM_ SG_ 753 VCFRONT_sleepBypassFault "Front body controller: sleep bypass fault";
CM_ SG_ 753 VCFRONT_sleepBypassVoltage "Front body controller: sleep bypass voltage";
CM_ SG_ 753 VCFRONT_sleepBypassCurrent "Front body controller: sleep bypass current";
CM_ SG_ 753 VCFRONT_vbatFusedHighState "Front body controller: vbat fused high state";
CM_ SG_ 753 VCFRONT_vbatFusedHighFault "Front body controller: vbat fused high fault";
CM_ SG_ 753 VCFRONT_vbatFusedSelfTestResult "Front body controller: vbat fused self test result; raw 12 = signal not available (SNA)";
CM_ SG_ 753 VCFRONT_vbatFusedHighTemp "Front body controller: vbat fused high temp";
CM_ SG_ 753 VCFRONT_vbatFusedHighVoltage "Front body controller: vbat fused high voltage";
CM_ SG_ 753 VCFRONT_vbatFusedHighCurrent "Front body controller: vbat fused high current";
CM_ SG_ 753 VCFRONT_chargedIBSAmpHours "Front body controller: charged IBS amp hours";
CM_ SG_ 753 VCFRONT_dischargedIBSAmpHours "Front body controller: discharged IBS amp hours";
CM_ SG_ 753 VCFRONT_IBSUnfilteredTemperature "Front body controller: IBS unfiltered temperature; raw 32768 = signal not available (SNA)";
CM_ BO_ 1353 "Front body controller message: homelink";
CM_ SG_ 1353 VCFRONT_homelinkV2Response0 "Front body controller: homelink V2 response0";
CM_ SG_ 1353 VCFRONT_homelinkV2Response1 "Front body controller: homelink V2 response1";
CM_ SG_ 1353 VCFRONT_homelinkV2Response2 "Front body controller: homelink V2 response2";
CM_ SG_ 1353 VCFRONT_homelinkV2Response3 "Front body controller: homelink V2 response3";
CM_ SG_ 1353 VCFRONT_homelinkV2Response4 "Front body controller: homelink V2 response4";
CM_ SG_ 1353 VCFRONT_homelinkCommStatus "Homelink communication status; raw 0 = signal not available (SNA)";
BA_DEF_ BO_ "GenMsgCycleTime" INT 0 3600000;
BA_DEF_ BO_ "GenMsgSendType" ENUM "Cyclic","NotUsed","NotUsed","NotUsed","NotUsed","NotUsed","NotUsed","IfActive","NoMsgSendType","NotUsed";
BA_DEF_ BO_ "VFrameFormat" ENUM "StandardCAN","ExtendedCAN","reserved","J1939PG","reserved","reserved","reserved","reserved","reserved","reserved","reserved","reserved","reserved","reserved","StandardCAN_FD","ExtendedCAN_FD";
BA_DEF_ BO_ "CANFD_BRS" ENUM "0","1";
BA_DEF_ SG_ "GenSigSNA" STRING;
BA_DEF_ SG_ "SystemSignalLongSymbol" STRING;
BA_DEF_ SG_ "Confidence" ENUM "validated","plausible","layout-only","contradicted";
BA_DEF_DEF_ "GenMsgCycleTime" 0;
BA_DEF_DEF_ "GenMsgSendType" "NoMsgSendType";
BA_DEF_DEF_ "VFrameFormat" "StandardCAN";
BA_DEF_DEF_ "CANFD_BRS" "1";
BA_DEF_DEF_ "GenSigSNA" "";
BA_DEF_DEF_ "SystemSignalLongSymbol" "";
BA_DEF_DEF_ "Confidence" "layout-only";
BA_ "GenMsgCycleTime" BO_ 947 500;
BA_ "GenMsgSendType" BO_ 947 0;
BA_ "GenMsgCycleTime" BO_ 660 500;
BA_ "GenMsgSendType" BO_ 660 0;
BA_ "GenMsgCycleTime" BO_ 1193 500;
BA_ "GenMsgSendType" BO_ 1193 0;
BA_ "GenMsgCycleTime" BO_ 853 1000;
BA_ "GenMsgSendType" BO_ 853 0;
BA_ "GenMsgCycleTime" BO_ 644 500;
BA_ "GenMsgSendType" BO_ 644 0;
BA_ "GenMsgCycleTime" BO_ 595 500;
BA_ "GenMsgSendType" BO_ 595 0;
BA_ "GenMsgCycleTime" BO_ 1285 100;
BA_ "GenMsgSendType" BO_ 1285 0;
BA_ "GenMsgCycleTime" BO_ 1858 40;
BA_ "GenMsgSendType" BO_ 1858 0;
BA_ "GenMsgCycleTime" BO_ 1119 500;
BA_ "GenMsgSendType" BO_ 1119 0;
BA_ "GenMsgCycleTime" BO_ 1030 200;
BA_ "GenMsgSendType" BO_ 1030 0;
BA_ "GenMsgCycleTime" BO_ 1399 100;
BA_ "GenMsgSendType" BO_ 1399 0;
BA_ "GenMsgCycleTime" BO_ 945 100;
BA_ "GenMsgSendType" BO_ 945 0;
BA_ "GenMsgCycleTime" BO_ 1090 50;
BA_ "GenMsgSendType" BO_ 1090 0;
BA_ "GenMsgCycleTime" BO_ 1027 200;
BA_ "GenMsgSendType" BO_ 1027 0;
BA_ "GenMsgCycleTime" BO_ 609 16;
BA_ "GenMsgSendType" BO_ 609 0;
BA_ "GenMsgCycleTime" BO_ 1847 1000;
BA_ "GenMsgSendType" BO_ 1847 0;
BA_ "GenMsgCycleTime" BO_ 1140 100;
BA_ "GenMsgSendType" BO_ 1140 0;
BA_ "GenMsgCycleTime" BO_ 1173 1000;
BA_ "GenMsgSendType" BO_ 1173 0;
BA_ "GenMsgCycleTime" BO_ 545 50;
BA_ "GenMsgSendType" BO_ 545 0;
BA_ "GenMsgCycleTime" BO_ 700 8;
BA_ "GenMsgSendType" BO_ 700 0;
BA_ "GenMsgCycleTime" BO_ 577 100;
BA_ "GenMsgSendType" BO_ 577 0;
BA_ "GenMsgCycleTime" BO_ 753 100;
BA_ "GenMsgSendType" BO_ 753 0;
BA_ "GenMsgCycleTime" BO_ 1353 10000;
BA_ "GenMsgSendType" BO_ 1353 0;
BA_ "Confidence" SG_ 947 UI_gloveboxRequest 0;
BA_ "Confidence" SG_ 947 UI_trunkRequest 0;
BA_ "Confidence" SG_ 947 UI_PINToDriveEnabled 0;
BA_ "Confidence" SG_ 947 UI_PINToDrivePassed 0;
BA_ "Confidence" SG_ 947 UI_disableMirrorAutoDim 0;
BA_ "Confidence" SG_ 947 UI_lightSwitch 0;
BA_ "GenSigSNA" SG_ 947 UI_lightSwitch "4";
BA_ "Confidence" SG_ 947 UI_readyToAddKey 0;
BA_ "Confidence" SG_ 947 UI_alarmTriggerRequest 0;
BA_ "Confidence" SG_ 947 UI_displayOnForUser 0;
BA_ "Confidence" SG_ 947 UI_BLEPushNotificationRequest 0;
BA_ "Confidence" SG_ 947 UI_keepAutopilotAwake 0;
BA_ "Confidence" SG_ 947 UI_batteryPreconditioningRequest 0;
BA_ "Confidence" SG_ 947 UI_autopilotPowerStateRequest 0;
BA_ "Confidence" SG_ 947 UI_autoRollWindowsOnLockEnable 0;
BA_ "Confidence" SG_ 947 UI_steeringWheelHeatReq 0;
BA_ "Confidence" SG_ 947 UI_disableHorn 0;
BA_ "Confidence" SG_ 947 UI_frontLeftSeatFanReq 0;
BA_ "Confidence" SG_ 947 UI_frontRightSeatAutoClimateReq 0;
BA_ "Confidence" SG_ 947 UI_frontRightSeatFanReq 0;
BA_ "Confidence" SG_ 947 UI_frontLeftSeatAutoClimateReq 0;
BA_ "Confidence" SG_ 947 UI_wiperHeaterReq 0;
BA_ "Confidence" SG_ 947 UI_silentAlarm 0;
BA_ "Confidence" SG_ 660 UI_lightFlashRequest 0;
BA_ "Confidence" SG_ 660 UI_phoneCallActive 0;
BA_ "Confidence" SG_ 660 UI_lightShowClosuresEnabled 0;
BA_ "Confidence" SG_ 660 UI_steeringWheelHeatAutoReq 0;
BA_ "Confidence" SG_ 660 UI_steeringWheelHeatLevelReq 0;
BA_ "Confidence" SG_ 660 UI_headlightPulseRequest 0;
BA_ "Confidence" SG_ 660 UI_displayRedShiftActive 0;
BA_ "Confidence" SG_ 660 UI_fasciaCameraWashRequest 0;
BA_ "Confidence" SG_ 660 UI_leftRearSeatAdjustmentRequest 0;
BA_ "Confidence" SG_ 660 UI_rightRearSeatAdjustmentReques 0;
BA_ "SystemSignalLongSymbol" SG_ 660 UI_rightRearSeatAdjustmentReques "UI_rightRearSeatAdjustmentRequest";
BA_ "Confidence" SG_ 660 UI_blindSpotIndicatorLightReques 0;
BA_ "SystemSignalLongSymbol" SG_ 660 UI_blindSpotIndicatorLightReques "UI_blindSpotIndicatorLightRequest";
BA_ "Confidence" SG_ 660 UI_keepOnAccessoryPortsReq 0;
BA_ "Confidence" SG_ 660 UI_fasciaCameraShown 0;
BA_ "Confidence" SG_ 660 UI_rearSeatChildLock 0;
BA_ "Confidence" SG_ 660 UI_windowPercentageRequest 0;
BA_ "Confidence" SG_ 660 UI_windowRequestedFL 0;
BA_ "Confidence" SG_ 660 UI_windowRequestedFR 0;
BA_ "Confidence" SG_ 660 UI_windowRequestedRL 0;
BA_ "Confidence" SG_ 660 UI_windowRequestedRR 0;
BA_ "Confidence" SG_ 660 UI_windowRequest 0;
BA_ "Confidence" SG_ 660 UI_closeTrunkRequest 0;
BA_ "Confidence" SG_ 660 UI_childPresenceDetectionDisable 0;
BA_ "SystemSignalLongSymbol" SG_ 660 UI_childPresenceDetectionDisable "UI_childPresenceDetectionDisableRequest";
BA_ "Confidence" SG_ 660 UI_derivedLoadshedFeature 0;
BA_ "Confidence" SG_ 660 UI_selfParkStandingBy 0;
BA_ "Confidence" SG_ 1193 UI_firstRowLeftDomeLightRequest 0;
BA_ "Confidence" SG_ 1193 UI_firstRowRightDomeLightRequest 0;
BA_ "Confidence" SG_ 1193 UI_secondRowLeftDomeLightRequest 0;
BA_ "Confidence" SG_ 1193 UI_secondRowCenterDomeLightReque 0;
BA_ "SystemSignalLongSymbol" SG_ 1193 UI_secondRowCenterDomeLightReque "UI_secondRowCenterDomeLightRequest";
BA_ "Confidence" SG_ 1193 UI_secondRowRightDomeLightReques 0;
BA_ "SystemSignalLongSymbol" SG_ 1193 UI_secondRowRightDomeLightReques "UI_secondRowRightDomeLightRequest";
BA_ "Confidence" SG_ 1193 UI_thirdRowLeftDomeLightRequest 0;
BA_ "Confidence" SG_ 1193 UI_thirdRowRightDomeLightRequest 0;
BA_ "Confidence" SG_ 853 UI_coolantFlowRequest 0;
BA_ "Confidence" SG_ 853 UI_inletActiveCoolTarget 0;
BA_ "Confidence" SG_ 853 UI_disableHVPTThermalLoads 0;
BA_ "Confidence" SG_ 853 UI_convenienceFeatureLimit 0;
BA_ "Confidence" SG_ 853 UI_allowConvenienceFeatures 0;
BA_ "Confidence" SG_ 853 UI_disablePhoneChargingPads 0;
BA_ "Confidence" SG_ 644 UI_transportMode 0;
BA_ "Confidence" SG_ 644 UI_showroomMode 0;
BA_ "Confidence" SG_ 644 UI_serviceMode 0;
BA_ "Confidence" SG_ 644 UI_carWashMode 0;
BA_ "Confidence" SG_ 644 UI_gameMode 0;
BA_ "Confidence" SG_ 644 UI_serviceModePlus 0;
BA_ "Confidence" SG_ 644 UI_premiumAmpPowerOff 0;
BA_ "Confidence" SG_ 644 UI_lightShowType 0;
BA_ "Confidence" SG_ 644 UI_upkeepMode 0;
BA_ "Confidence" SG_ 595 UI_ventPanelControlRequestIndex 1;
BA_ "Confidence" SG_ 595 UI_ventPanelLeftPositionX 0;
BA_ "Confidence" SG_ 595 UI_ventPanelLeftPositionY 0;
BA_ "Confidence" SG_ 595 UI_ventPanelLeftLateralSplit 0;
BA_ "Confidence" SG_ 595 UI_ventPanelRightPositionX 0;
BA_ "Confidence" SG_ 595 UI_ventPanelRightPositionY 0;
BA_ "Confidence" SG_ 595 UI_ventPanelRightLateralSplit 0;
BA_ "Confidence" SG_ 595 UI_ventPanelLeftLateralMode 0;
BA_ "Confidence" SG_ 595 UI_ventPanelRightLateralMode 0;
BA_ "Confidence" SG_ 595 UI_hvacReqActiveVents 0;
BA_ "Confidence" SG_ 595 UI_vent2RLeftPositionX 0;
BA_ "Confidence" SG_ 595 UI_vent2RLeftPositionY 0;
BA_ "Confidence" SG_ 595 UI_vent2RRightPositionX 0;
BA_ "Confidence" SG_ 595 UI_vent2RRightPositionY 0;
BA_ "Confidence" SG_ 595 UI_hvacReqThirdRowState 0;
BA_ "Confidence" SG_ 1285 SA_infoIndex 1;
BA_ "Confidence" SG_ 1285 SA_genealogyVersion 0;
BA_ "Confidence" SG_ 1285 SA_genealogyCrc 0;
BA_ "Confidence" SG_ 1285 SA_region 0;
BA_ "Confidence" SG_ 1285 SA_OverTempThreshold 0;
BA_ "Confidence" SG_ 1285 SA_partNumInt 0;
BA_ "Confidence" SG_ 1285 SA_partNumRev 0;
BA_ "Confidence" SG_ 1285 SA_currentLimit 0;
BA_ "Confidence" SG_ 1285 SA_l1Voltage 0;
BA_ "Confidence" SG_ 1949 V2G_evseLogDataSelect 1;
BA_ "Confidence" SG_ 1949 V2G_chgParamRes_respCode 0;
BA_ "Confidence" SG_ 1949 V2G_chgParamRes_finished 0;
BA_ "Confidence" SG_ 1949 V2G_chgParamRes_evseStatus 0;
BA_ "Confidence" SG_ 1949 V2G_chgParamRes_evseMaxILim 0;
BA_ "Confidence" SG_ 1949 V2G_chgParamRes_evseMaxVLim 0;
BA_ "Confidence" SG_ 1949 V2G_chgParamRes_evseMinILim 0;
BA_ "Confidence" SG_ 1949 V2G_chgParamRes_evseMinVLim 0;
BA_ "Confidence" SG_ 1949 V2G_chgParamRes_evseMaxPowerLim 0;
BA_ "Confidence" SG_ 1949 V2G_chgParamRes_evseMaxPower_val 0;
BA_ "Confidence" SG_ 1949 V2G_chgParamRes_isoState 0;
BA_ "Confidence" SG_ 1949 V2G_chgParamRes_isoState_val 0;
BA_ "Confidence" SG_ 1858 VCBATT1_lvbmsStatusHighIndex 1;
BA_ "Confidence" SG_ 1858 VCBATT1_LVBMS_packCurrent 0;
BA_ "GenSigSNA" SG_ 1858 VCBATT1_LVBMS_packCurrent "4194303";
BA_ "Confidence" SG_ 1858 VCBATT1_LVBMS_packVoltage 0;
BA_ "GenSigSNA" SG_ 1858 VCBATT1_LVBMS_packVoltage "65535";
BA_ "Confidence" SG_ 1858 VCBATT1_LVBMS_packTemperature 0;
BA_ "GenSigSNA" SG_ 1858 VCBATT1_LVBMS_packTemperature "511";
BA_ "Confidence" SG_ 1858 VCBATT1_LVBMS_MOSTemperature 0;
BA_ "GenSigSNA" SG_ 1858 VCBATT1_LVBMS_MOSTemperature "4095";
BA_ "Confidence" SG_ 1858 VCBATT1_LVBMS_sumCellVoltage 0;
BA_ "GenSigSNA" SG_ 1858 VCBATT1_LVBMS_sumCellVoltage "65535";
BA_ "Confidence" SG_ 1858 VCBATT1_LVBMS_maxBrickVoltage 0;
BA_ "GenSigSNA" SG_ 1858 VCBATT1_LVBMS_maxBrickVoltage "8191";
BA_ "Confidence" SG_ 1858 VCBATT1_LVBMS_maxBrickVoltageInd 0;
BA_ "GenSigSNA" SG_ 1858 VCBATT1_LVBMS_maxBrickVoltageInd "255";
BA_ "SystemSignalLongSymbol" SG_ 1858 VCBATT1_LVBMS_maxBrickVoltageInd "VCBATT1_LVBMS_maxBrickVoltageIndex";
BA_ "Confidence" SG_ 1858 VCBATT1_totalLVLoadCurrent 0;
BA_ "Confidence" SG_ 1858 VCBATT1_LVPackChargeCurrentLimit 0;
BA_ "Confidence" SG_ 1858 VCBATT1_LVPackCurrent 0;
BA_ "Confidence" SG_ 1858 VCBATT1_LVBMS_estimatedPackOcv 0;
BA_ "Confidence" SG_ 1858 VCBATT1_LVBMS_voltageTarget 0;
BA_ "GenSigSNA" SG_ 1858 VCBATT1_LVBMS_voltageTarget "65535";
BA_ "Confidence" SG_ 1858 VCBATT1_LVBMS_currentTarget 0;
BA_ "GenSigSNA" SG_ 1858 VCBATT1_LVBMS_currentTarget "262143";
BA_ "Confidence" SG_ 1858 VCBATT1_LVBMS_maxAllowedChargeCu 0;
BA_ "GenSigSNA" SG_ 1858 VCBATT1_LVBMS_maxAllowedChargeCu "8191";
BA_ "SystemSignalLongSymbol" SG_ 1858 VCBATT1_LVBMS_maxAllowedChargeCu "VCBATT1_LVBMS_maxAllowedChargeCurrent";
BA_ "Confidence" SG_ 1858 VCBATT1_LVBMS_maxAllowedDischarg 0;
BA_ "GenSigSNA" SG_ 1858 VCBATT1_LVBMS_maxAllowedDischarg "8191";
BA_ "SystemSignalLongSymbol" SG_ 1858 VCBATT1_LVBMS_maxAllowedDischarg "VCBATT1_LVBMS_maxAllowedDischargeCurrent";
BA_ "Confidence" SG_ 1858 VCBATT1_LVBMS_MOSCommand 0;
BA_ "Confidence" SG_ 1858 VCBATT1_LVBMS_ClearErrorCntrComm 0;
BA_ "SystemSignalLongSymbol" SG_ 1858 VCBATT1_LVBMS_ClearErrorCntrComm "VCBATT1_LVBMS_ClearErrorCntrCommand";
BA_ "Confidence" SG_ 1858 VCBATT1_LVBMS_ClearHistoricFault 0;
BA_ "SystemSignalLongSymbol" SG_ 1858 VCBATT1_LVBMS_ClearHistoricFault "VCBATT1_LVBMS_ClearHistoricFaultCommand";
BA_ "Confidence" SG_ 1858 VCBATT1_LVBMS_ResetLVBMSCommand 0;
BA_ "Confidence" SG_ 1858 VCBATT1_LVBMS_EnterHibernationCo 0;
BA_ "SystemSignalLongSymbol" SG_ 1858 VCBATT1_LVBMS_EnterHibernationCo "VCBATT1_LVBMS_EnterHibernationCommand";
BA_ "Confidence" SG_ 1858 VCBATT1_LVBMS_ECPAState 0;
BA_ "GenSigSNA" SG_ 1858 VCBATT1_LVBMS_ECPAState "3";
BA_ "Confidence" SG_ 1858 VCBATT1_LVBMS_MOSState 0;
BA_ "GenSigSNA" SG_ 1858 VCBATT1_LVBMS_MOSState "3";
BA_ "Confidence" SG_ 1858 VCBATT1_LVBMS_VehicleState 0;
BA_ "Confidence" SG_ 1858 VCBATT1_LVBMS_LINWakeDisabled 0;
BA_ "Confidence" SG_ 1858 VCBATT1_LVBMS_chargeType 0;
BA_ "GenSigSNA" SG_ 1858 VCBATT1_LVBMS_chargeType "4";
BA_ "Confidence" SG_ 1858 VCBATT1_LVBMS_cellAndArcProtEnab 0;
BA_ "SystemSignalLongSymbol" SG_ 1858 VCBATT1_LVBMS_cellAndArcProtEnab "VCBATT1_LVBMS_cellAndArcProtEnabled";
BA_ "Confidence" SG_ 1858 VCBATT1_LVBMS_avgBrickVoltage 0;
BA_ "GenSigSNA" SG_ 1858 VCBATT1_LVBMS_avgBrickVoltage "8191";
BA_ "Confidence" SG_ 1858 VCBATT1_LVBMS_minBrickVoltage 0;
BA_ "GenSigSNA" SG_ 1858 VCBATT1_LVBMS_minBrickVoltage "8191";
BA_ "Confidence" SG_ 1858 VCBATT1_LVBMS_minBrickVoltageInd 0;
BA_ "GenSigSNA" SG_ 1858 VCBATT1_LVBMS_minBrickVoltageInd "255";
BA_ "SystemSignalLongSymbol" SG_ 1858 VCBATT1_LVBMS_minBrickVoltageInd "VCBATT1_LVBMS_minBrickVoltageIndex";
BA_ "Confidence" SG_ 1119 VCBATT1_LVSelfTestsChecksum 0;
BA_ "Confidence" SG_ 1119 VCBATT1_LVSelfTestsCounter 0;
BA_ "Confidence" SG_ 1119 VCBATT1_LVSelfTestsIndex 1;
BA_ "Confidence" SG_ 1119 VCBATT1_lvProtectionSelfTestsEna 0;
BA_ "SystemSignalLongSymbol" SG_ 1119 VCBATT1_lvProtectionSelfTestsEna "VCBATT1_lvProtectionSelfTestsEnabled";
BA_ "Confidence" SG_ 1119 VCBATT1_startBattDomainOvercurre 0;
BA_ "SystemSignalLongSymbol" SG_ 1119 VCBATT1_startBattDomainOvercurre "VCBATT1_startBattDomainOvercurrentSelfTest";
BA_ "Confidence" SG_ 1119 VCBATT1_startBattDomainOvervolta 0;
BA_ "SystemSignalLongSymbol" SG_ 1119 VCBATT1_startBattDomainOvervolta "VCBATT1_startBattDomainOvervoltageSelfTest";
BA_ "Confidence" SG_ 1119 VCBATT1_startBattDomainUndervolt 0;
BA_ "SystemSignalLongSymbol" SG_ 1119 VCBATT1_startBattDomainUndervolt "VCBATT1_startBattDomainUndervoltageSelfTest";
BA_ "Confidence" SG_ 1119 VCBATT1_startDualPowerLoadsSelfT 0;
BA_ "SystemSignalLongSymbol" SG_ 1119 VCBATT1_startDualPowerLoadsSelfT "VCBATT1_startDualPowerLoadsSelfTest";
BA_ "Confidence" SG_ 1119 VCBATT1_startVCBattBridgeEFuseAS 0;
BA_ "SystemSignalLongSymbol" SG_ 1119 VCBATT1_startVCBattBridgeEFuseAS "VCBATT1_startVCBattBridgeEFuseASICSelfTest";
BA_ "Confidence" SG_ 1119 VCBATT1_startPCSOVShutdownSelfTe 0;
BA_ "SystemSignalLongSymbol" SG_ 1119 VCBATT1_startPCSOVShutdownSelfTe "VCBATT1_startPCSOVShutdownSelfTest";
BA_ "Confidence" SG_ 1119 VCBATT1_startPCSDomainOvervoltag 0;
BA_ "SystemSignalLongSymbol" SG_ 1119 VCBATT1_startPCSDomainOvervoltag "VCBATT1_startPCSDomainOvervoltageSelfTest";
BA_ "Confidence" SG_ 1119 VCBATT1_startBattDomainUnde_0001 0;
BA_ "SystemSignalLongSymbol" SG_ 1119 VCBATT1_startBattDomainUnde_0001 "VCBATT1_startBattDomainUndervoltageVCLeftSelfTest";
BA_ "Confidence" SG_ 1119 VCBATT1_startPCSDomainUndervolta 0;
BA_ "SystemSignalLongSymbol" SG_ 1119 VCBATT1_startPCSDomainUndervolta "VCBATT1_startPCSDomainUndervoltageSelfTest";
BA_ "Confidence" SG_ 1119 VCBATT1_startVCFrontBridgeEFuseA 0;
BA_ "SystemSignalLongSymbol" SG_ 1119 VCBATT1_startVCFrontBridgeEFuseA "VCBATT1_startVCFrontBridgeEFuseASICSelfTest";
BA_ "Confidence" SG_ 1119 VCBATT1_battDomainOvercurrentSel 0;
BA_ "SystemSignalLongSymbol" SG_ 1119 VCBATT1_battDomainOvercurrentSel "VCBATT1_battDomainOvercurrentSelfTestResult";
BA_ "Confidence" SG_ 1119 VCBATT1_battDomainOvercurre_0001 0;
BA_ "GenSigSNA" SG_ 1119 VCBATT1_battDomainOvercurre_0001 "4";
BA_ "SystemSignalLongSymbol" SG_ 1119 VCBATT1_battDomainOvercurre_0001 "VCBATT1_battDomainOvercurrentSelfTestState";
BA_ "Confidence" SG_ 1119 VCBATT1_battDomainOvervoltageSel 0;
BA_ "SystemSignalLongSymbol" SG_ 1119 VCBATT1_battDomainOvervoltageSel "VCBATT1_battDomainOvervoltageSelfTestResult";
BA_ "Confidence" SG_ 1119 VCBATT1_battDomainOvervolta_0001 0;
BA_ "GenSigSNA" SG_ 1119 VCBATT1_battDomainOvervolta_0001 "4";
BA_ "SystemSignalLongSymbol" SG_ 1119 VCBATT1_battDomainOvervolta_0001 "VCBATT1_battDomainOvervoltageSelfTestState";
BA_ "Confidence" SG_ 1119 VCBATT1_battDomainUndervoltageSe 0;
BA_ "SystemSignalLongSymbol" SG_ 1119 VCBATT1_battDomainUndervoltageSe "VCBATT1_battDomainUndervoltageSelfTestResult";
BA_ "Confidence" SG_ 1119 VCBATT1_battDomainUndervolt_0001 0;
BA_ "GenSigSNA" SG_ 1119 VCBATT1_battDomainUndervolt_0001 "4";
BA_ "SystemSignalLongSymbol" SG_ 1119 VCBATT1_battDomainUndervolt_0001 "VCBATT1_battDomainUndervoltageSelfTestState";
BA_ "Confidence" SG_ 1119 VCBATT1_dualPowerLoadsSelfTestRe 0;
BA_ "SystemSignalLongSymbol" SG_ 1119 VCBATT1_dualPowerLoadsSelfTestRe "VCBATT1_dualPowerLoadsSelfTestResult";
BA_ "Confidence" SG_ 1119 VCBATT1_dualPowerLoadsSelfTestSt 0;
BA_ "GenSigSNA" SG_ 1119 VCBATT1_dualPowerLoadsSelfTestSt "4";
BA_ "SystemSignalLongSymbol" SG_ 1119 VCBATT1_dualPowerLoadsSelfTestSt "VCBATT1_dualPowerLoadsSelfTestState";
BA_ "Confidence" SG_ 1119 VCBATT1_vcbattBridgeEFuseASICSel 0;
BA_ "SystemSignalLongSymbol" SG_ 1119 VCBATT1_vcbattBridgeEFuseASICSel "VCBATT1_vcbattBridgeEFuseASICSelfTestResult";
BA_ "Confidence" SG_ 1119 VCBATT1_vcbattBridgeEFuseAS_0001 0;
BA_ "GenSigSNA" SG_ 1119 VCBATT1_vcbattBridgeEFuseAS_0001 "4";
BA_ "SystemSignalLongSymbol" SG_ 1119 VCBATT1_vcbattBridgeEFuseAS_0001 "VCBATT1_vcbattBridgeEFuseASICSelfTestState";
BA_ "Confidence" SG_ 1119 VCBATT1_uvProtectionState 0;
BA_ "Confidence" SG_ 1119 VCBATT1_undervoltageSelfTestFaul 0;
BA_ "SystemSignalLongSymbol" SG_ 1119 VCBATT1_undervoltageSelfTestFaul "VCBATT1_undervoltageSelfTestFaultInjectionReady";
BA_ "Confidence" SG_ 1119 VC_selfTestsRunningMode 0;
BA_ "Confidence" SG_ 1030 VCBATT1_eFuseDebugStatusIndex 1;
BA_ "Confidence" SG_ 1030 VCBATT1_leftControllerEFuseState 0;
BA_ "Confidence" SG_ 1030 VCBATT1_leftControllerEFuseCurre 0;
BA_ "SystemSignalLongSymbol" SG_ 1030 VCBATT1_leftControllerEFuseCurre "VCBATT1_leftControllerEFuseCurrent";
BA_ "Confidence" SG_ 1030 VCBATT1_leftControllerEFuseOutpu 0;
BA_ "SystemSignalLongSymbol" SG_ 1030 VCBATT1_leftControllerEFuseOutpu "VCBATT1_leftControllerEFuseOutput";
BA_ "Confidence" SG_ 1030 VCBATT1_leftControllerEFuse_0002 0;
BA_ "SystemSignalLongSymbol" SG_ 1030 VCBATT1_leftControllerEFuse_0002 "VCBATT1_leftControllerEFuseOutputDesired";
BA_ "Confidence" SG_ 1030 VCBATT1_leftControllerEFuseBypas 0;
BA_ "SystemSignalLongSymbol" SG_ 1030 VCBATT1_leftControllerEFuseBypas "VCBATT1_leftControllerEFuseBypass";
BA_ "Confidence" SG_ 1030 VCBATT1_leftControllerEFuse_0001 0;
BA_ "SystemSignalLongSymbol" SG_ 1030 VCBATT1_leftControllerEFuse_0001 "VCBATT1_leftControllerEFuseBypassDesired";
BA_ "Confidence" SG_ 1030 VCBATT1_leftControllerEFuseVolta 0;
BA_ "SystemSignalLongSymbol" SG_ 1030 VCBATT1_leftControllerEFuseVolta "VCBATT1_leftControllerEFuseVoltage";
BA_ "Confidence" SG_ 1030 VCBATT1_leftControllerEFuseTempe 0;
BA_ "SystemSignalLongSymbol" SG_ 1030 VCBATT1_leftControllerEFuseTempe "VCBATT1_leftControllerEFuseTemperature";
BA_ "Confidence" SG_ 1030 VCBATT1_leftControllerEFuseManag 0;
BA_ "SystemSignalLongSymbol" SG_ 1030 VCBATT1_leftControllerEFuseManag "VCBATT1_leftControllerEFuseManagerState";
BA_ "Confidence" SG_ 1030 VCBATT1_leftControllerEFuseHardS 0;
BA_ "SystemSignalLongSymbol" SG_ 1030 VCBATT1_leftControllerEFuseHardS "VCBATT1_leftControllerEFuseHardShortThreshold";
BA_ "Confidence" SG_ 1030 VCBATT1_leftControllerEFuseOCThr 0;
BA_ "SystemSignalLongSymbol" SG_ 1030 VCBATT1_leftControllerEFuseOCThr "VCBATT1_leftControllerEFuseOCThreshold";
BA_ "Confidence" SG_ 1030 VCBATT1_leftControllerEFuseType 0;
BA_ "Confidence" SG_ 1030 VCBATT1_EPAS1EFuseState 0;
BA_ "Confidence" SG_ 1030 VCBATT1_EPAS1EFuseCurrent 0;
BA_ "Confidence" SG_ 1030 VCBATT1_EPAS1EFuseOutput 0;
BA_ "Confidence" SG_ 1030 VCBATT1_EPAS1EFuseOutputDesired 0;
BA_ "Confidence" SG_ 1030 VCBATT1_EPAS1EFuseBypass 0;
BA_ "Confidence" SG_ 1030 VCBATT1_EPAS1EFuseBypassDesired 0;
BA_ "Confidence" SG_ 1030 VCBATT1_EPAS1EFuseVoltage 0;
BA_ "Confidence" SG_ 1030 VCBATT1_EPAS1EFuseTemperature 0;
BA_ "Confidence" SG_ 1030 VCBATT1_EPAS1EFuseManagerState 0;
BA_ "Confidence" SG_ 1030 VCBATT1_EPAS1EFuseHardShortThres 0;
BA_ "SystemSignalLongSymbol" SG_ 1030 VCBATT1_EPAS1EFuseHardShortThres "VCBATT1_EPAS1EFuseHardShortThreshold";
BA_ "Confidence" SG_ 1030 VCBATT1_EPAS1EFuseOCThreshold 0;
BA_ "Confidence" SG_ 1030 VCBATT1_EPAS1EFuseType 0;
BA_ "Confidence" SG_ 1030 VCBATT1_autopilot1EFuseState 0;
BA_ "Confidence" SG_ 1030 VCBATT1_autopilot1EFuseCurrent 0;
BA_ "Confidence" SG_ 1030 VCBATT1_autopilot1EFuseOutput 0;
BA_ "Confidence" SG_ 1030 VCBATT1_autopilot1EFuseOutputDes 0;
BA_ "SystemSignalLongSymbol" SG_ 1030 VCBATT1_autopilot1EFuseOutputDes "VCBATT1_autopilot1EFuseOutputDesired";
BA_ "Confidence" SG_ 1030 VCBATT1_autopilot1EFuseBypass 0;
BA_ "Confidence" SG_ 1030 VCBATT1_autopilot1EFuseBypassDes 0;
BA_ "SystemSignalLongSymbol" SG_ 1030 VCBATT1_autopilot1EFuseBypassDes "VCBATT1_autopilot1EFuseBypassDesired";
BA_ "Confidence" SG_ 1030 VCBATT1_autopilot1EFuseVoltage 0;
BA_ "Confidence" SG_ 1030 VCBATT1_autopilot1EFuseTemperatu 0;
BA_ "SystemSignalLongSymbol" SG_ 1030 VCBATT1_autopilot1EFuseTemperatu "VCBATT1_autopilot1EFuseTemperature";
BA_ "Confidence" SG_ 1030 VCBATT1_autopilot1EFuseManagerSt 0;
BA_ "SystemSignalLongSymbol" SG_ 1030 VCBATT1_autopilot1EFuseManagerSt "VCBATT1_autopilot1EFuseManagerState";
BA_ "Confidence" SG_ 1030 VCBATT1_autopilot1EFuseHardShort 0;
BA_ "SystemSignalLongSymbol" SG_ 1030 VCBATT1_autopilot1EFuseHardShort "VCBATT1_autopilot1EFuseHardShortThreshold";
BA_ "Confidence" SG_ 1030 VCBATT1_autopilot1EFuseOCThresho 0;
BA_ "SystemSignalLongSymbol" SG_ 1030 VCBATT1_autopilot1EFuseOCThresho "VCBATT1_autopilot1EFuseOCThreshold";
BA_ "Confidence" SG_ 1030 VCBATT1_autopilot1EFuseType 0;
BA_ "Confidence" SG_ 1399 VCBATT2_vehiclePowerStateDBG 0;
BA_ "Confidence" SG_ 1399 VCBATT2_nmWakeUpReasonDBG 0;
BA_ "Confidence" SG_ 1399 VCBATT2_nmKeepAwakeReasonDBG 0;
BA_ "GenSigSNA" SG_ 1399 VCBATT2_nmKeepAwakeReasonDBG "0";
BA_ "Confidence" SG_ 1399 VCBATT2_LIN_bus_0_busErrorCount 0;
BA_ "Confidence" SG_ 1399 VCBATT2_LIN_bus_1_busErrorCount 0;
BA_ "Confidence" SG_ 1399 VCBATT2_hibernationStateDBG 0;
BA_ "Confidence" SG_ 945 VCBATT_LVHealthChecksum 0;
BA_ "Confidence" SG_ 945 VCBATT_LVHealthCounter 0;
BA_ "Confidence" SG_ 945 VCBATT_LVHealthStatus 0;
BA_ "Confidence" SG_ 945 VCBATT_LVStatusForDrive 0;
BA_ "Confidence" SG_ 945 VCBATT_LVPowerSecondsToSafeHarbo 0;
BA_ "SystemSignalLongSymbol" SG_ 945 VCBATT_LVPowerSecondsToSafeHarbo "VCBATT_LVPowerSecondsToSafeHarbor";
BA_ "Confidence" SG_ 945 VCBATT_autonomyBehavior 0;
BA_ "Confidence" SG_ 945 VCBATT_hardwareProtectionsArmed 0;
BA_ "Confidence" SG_ 945 VCBATT_12vStatusForDrive 0;
BA_ "Confidence" SG_ 1090 VCBATT_pcsInterfaceMuxIndex 1;
BA_ "Confidence" SG_ 1090 VCBATT_pcsInterfaceCounter 0;
BA_ "Confidence" SG_ 1090 VCBATT_pcsInterfaceChecksum 0;
BA_ "Confidence" SG_ 1090 VCBATT_pcsLVVoltageTarget 0;
BA_ "Confidence" SG_ 1090 VCBATT_pcsLVMinVoltageLimit 0;
BA_ "Confidence" SG_ 1090 VCBATT_pcsLVMaxVoltageLimit 0;
BA_ "Confidence" SG_ 1090 VCBATT_goodForPCSPowerCycle 0;
BA_ "Confidence" SG_ 1090 VCBATT_LVBatteryCannotSupportVeh 0;
BA_ "SystemSignalLongSymbol" SG_ 1090 VCBATT_LVBatteryCannotSupportVeh "VCBATT_LVBatteryCannotSupportVehicle";
BA_ "Confidence" SG_ 1090 VCBATT_pcsResistanceFiltered 0;
BA_ "GenSigSNA" SG_ 1090 VCBATT_pcsResistanceFiltered "65535";
BA_ "Confidence" SG_ 1090 VCBATT_pcsLVMaxDchrgCurrentLimit 0;
BA_ "Confidence" SG_ 1090 VCBATT_defaultPcsLVVoltageTarget 0;
BA_ "Confidence" SG_ 1090 VCBATT_lvHwProtSelfTestActive 0;
BA_ "Confidence" SG_ 1090 VCBATT_lvBatteryDischargeRequest 0;
BA_ "Confidence" SG_ 1027 VCFRONT1_eFuseDebugStatusIndex 1;
BA_ "Confidence" SG_ 1027 VCFRONT1_EPAS2EFuseState 0;
BA_ "Confidence" SG_ 1027 VCFRONT1_EPAS2EFuseCurrent 0;
BA_ "Confidence" SG_ 1027 VCFRONT1_EPAS2EFuseOutput 0;
BA_ "Confidence" SG_ 1027 VCFRONT1_EPAS2EFuseOutputDesired 0;
BA_ "Confidence" SG_ 1027 VCFRONT1_EPAS2EFuseBypass 0;
BA_ "Confidence" SG_ 1027 VCFRONT1_EPAS2EFuseBypassDesired 0;
BA_ "Confidence" SG_ 1027 VCFRONT1_EPAS2EFuseVoltage 0;
BA_ "Confidence" SG_ 1027 VCFRONT1_EPAS2EFuseTemperature 0;
BA_ "Confidence" SG_ 1027 VCFRONT1_EPAS2EFuseManagerState 0;
BA_ "Confidence" SG_ 1027 VCFRONT1_EPAS2EFuseHardShortThre 0;
BA_ "SystemSignalLongSymbol" SG_ 1027 VCFRONT1_EPAS2EFuseHardShortThre "VCFRONT1_EPAS2EFuseHardShortThreshold";
BA_ "Confidence" SG_ 1027 VCFRONT1_EPAS2EFuseOCThreshold 0;
BA_ "Confidence" SG_ 1027 VCFRONT1_EPAS2EFuseType 0;
BA_ "Confidence" SG_ 1027 VCFRONT1_rightControllerEFuseSta 0;
BA_ "SystemSignalLongSymbol" SG_ 1027 VCFRONT1_rightControllerEFuseSta "VCFRONT1_rightControllerEFuseState";
BA_ "Confidence" SG_ 1027 VCFRONT1_rightControllerEFuseCur 0;
BA_ "SystemSignalLongSymbol" SG_ 1027 VCFRONT1_rightControllerEFuseCur "VCFRONT1_rightControllerEFuseCurrent";
BA_ "Confidence" SG_ 1027 VCFRONT1_rightControllerEFuseOut 0;
BA_ "SystemSignalLongSymbol" SG_ 1027 VCFRONT1_rightControllerEFuseOut "VCFRONT1_rightControllerEFuseOutput";
BA_ "Confidence" SG_ 1027 VCFRONT1_rightControllerEFu_0002 0;
BA_ "SystemSignalLongSymbol" SG_ 1027 VCFRONT1_rightControllerEFu_0002 "VCFRONT1_rightControllerEFuseOutputDesired";
BA_ "Confidence" SG_ 1027 VCFRONT1_rightControllerEFuseByp 0;
BA_ "SystemSignalLongSymbol" SG_ 1027 VCFRONT1_rightControllerEFuseByp "VCFRONT1_rightControllerEFuseBypass";
BA_ "Confidence" SG_ 1027 VCFRONT1_rightControllerEFu_0001 0;
BA_ "SystemSignalLongSymbol" SG_ 1027 VCFRONT1_rightControllerEFu_0001 "VCFRONT1_rightControllerEFuseBypassDesired";
BA_ "Confidence" SG_ 1027 VCFRONT1_rightControllerEFuseVol 0;
BA_ "SystemSignalLongSymbol" SG_ 1027 VCFRONT1_rightControllerEFuseVol "VCFRONT1_rightControllerEFuseVoltage";
BA_ "Confidence" SG_ 1027 VCFRONT1_rightControllerEFuseTem 0;
BA_ "SystemSignalLongSymbol" SG_ 1027 VCFRONT1_rightControllerEFuseTem "VCFRONT1_rightControllerEFuseTemperature";
BA_ "Confidence" SG_ 1027 VCFRONT1_rightControllerEFuseMan 0;
BA_ "SystemSignalLongSymbol" SG_ 1027 VCFRONT1_rightControllerEFuseMan "VCFRONT1_rightControllerEFuseManagerState";
BA_ "Confidence" SG_ 1027 VCFRONT1_rightControllerEFuseHar 0;
BA_ "SystemSignalLongSymbol" SG_ 1027 VCFRONT1_rightControllerEFuseHar "VCFRONT1_rightControllerEFuseHardShortThreshold";
BA_ "Confidence" SG_ 1027 VCFRONT1_rightControllerEFuseOCT 0;
BA_ "SystemSignalLongSymbol" SG_ 1027 VCFRONT1_rightControllerEFuseOCT "VCFRONT1_rightControllerEFuseOCThreshold";
BA_ "Confidence" SG_ 1027 VCFRONT1_rightControllerEFuseTyp 0;
BA_ "SystemSignalLongSymbol" SG_ 1027 VCFRONT1_rightControllerEFuseTyp "VCFRONT1_rightControllerEFuseType";
BA_ "Confidence" SG_ 1027 VCFRONT1_autopilot2EFuseState 0;
BA_ "Confidence" SG_ 1027 VCFRONT1_autopilot2EFuseCurrent 0;
BA_ "Confidence" SG_ 1027 VCFRONT1_autopilot2EFuseOutput 0;
BA_ "Confidence" SG_ 1027 VCFRONT1_autopilot2EFuseOutputDe 0;
BA_ "SystemSignalLongSymbol" SG_ 1027 VCFRONT1_autopilot2EFuseOutputDe "VCFRONT1_autopilot2EFuseOutputDesired";
BA_ "Confidence" SG_ 1027 VCFRONT1_autopilot2EFuseBypass 0;
BA_ "Confidence" SG_ 1027 VCFRONT1_autopilot2EFuseBypassDe 0;
BA_ "SystemSignalLongSymbol" SG_ 1027 VCFRONT1_autopilot2EFuseBypassDe "VCFRONT1_autopilot2EFuseBypassDesired";
BA_ "Confidence" SG_ 1027 VCFRONT1_autopilot2EFuseVoltage 0;
BA_ "Confidence" SG_ 1027 VCFRONT1_autopilot2EFuseTemperat 0;
BA_ "SystemSignalLongSymbol" SG_ 1027 VCFRONT1_autopilot2EFuseTemperat "VCFRONT1_autopilot2EFuseTemperature";
BA_ "Confidence" SG_ 1027 VCFRONT1_autopilot2EFuseManagerS 0;
BA_ "SystemSignalLongSymbol" SG_ 1027 VCFRONT1_autopilot2EFuseManagerS "VCFRONT1_autopilot2EFuseManagerState";
BA_ "Confidence" SG_ 1027 VCFRONT1_autopilot2EFuseHardShor 0;
BA_ "SystemSignalLongSymbol" SG_ 1027 VCFRONT1_autopilot2EFuseHardShor "VCFRONT1_autopilot2EFuseHardShortThreshold";
BA_ "Confidence" SG_ 1027 VCFRONT1_autopilot2EFuseOCThresh 0;
BA_ "SystemSignalLongSymbol" SG_ 1027 VCFRONT1_autopilot2EFuseOCThresh "VCFRONT1_autopilot2EFuseOCThreshold";
BA_ "Confidence" SG_ 1027 VCFRONT1_autopilot2EFuseType 0;
BA_ "Confidence" SG_ 609 VCFRONT_12VBatteryStatusIndex 1;
BA_ "Confidence" SG_ 609 VCFRONT_good12VforUpdate 0;
BA_ "Confidence" SG_ 609 VCFRONT_LVLoadRequest 0;
BA_ "Confidence" SG_ 609 VCFRONT_12VBatteryStatusCounter 0;
BA_ "Confidence" SG_ 609 VCFRONT_12VBatteryStatusChecksum 0;
BA_ "Confidence" SG_ 609 VCFRONT_batterySupportRequest 0;
BA_ "Confidence" SG_ 609 VCFRONT_batterySMState 0;
BA_ "Confidence" SG_ 609 VCFRONT_eFuseRecoveryStateDBG 0;
BA_ "Confidence" SG_ 609 VCFRONT_batteryLINScheduleDBG 0;
BA_ "GenSigSNA" SG_ 609 VCFRONT_batteryLINScheduleDBG "7";
BA_ "Confidence" SG_ 609 VCFRONT_resistanceEstimationTest 0;
BA_ "SystemSignalLongSymbol" SG_ 609 VCFRONT_resistanceEstimationTest "VCFRONT_resistanceEstimationTestCounter";
BA_ "Confidence" SG_ 609 VCFRONT_IBSCurrent 0;
BA_ "Confidence" SG_ 609 VCFRONT_IBSVoltage 0;
BA_ "GenSigSNA" SG_ 609 VCFRONT_IBSVoltage "4095";
BA_ "Confidence" SG_ 609 VCFRONT_reverseBatteryFault 0;
BA_ "Confidence" SG_ 609 VCFRONT_LVBatterySupported 0;
BA_ "Confidence" SG_ 609 VCFRONT_LVBatteryCannotSupportVe 0;
BA_ "SystemSignalLongSymbol" SG_ 609 VCFRONT_LVBatteryCannotSupportVe "VCFRONT_LVBatteryCannotSupportVehicle";
BA_ "Confidence" SG_ 609 VCFRONT_goodTemp12VforUpdate 0;
BA_ "Confidence" SG_ 609 VCFRONT_12VBatteryTargetVoltage 0;
BA_ "Confidence" SG_ 609 VCFRONT_IBSTemperature 0;
BA_ "GenSigSNA" SG_ 609 VCFRONT_IBSTemperature "2047";
BA_ "Confidence" SG_ 609 VCFRONT_currentSensorMismatchLea 0;
BA_ "SystemSignalLongSymbol" SG_ 609 VCFRONT_currentSensorMismatchLea "VCFRONT_currentSensorMismatchLeakyBktPctDBG";
BA_ "Confidence" SG_ 609 VCFRONT_LVBatteryEnergyRemaining 0;
BA_ "SystemSignalLongSymbol" SG_ 609 VCFRONT_LVBatteryEnergyRemaining "VCFRONT_LVBatteryEnergyRemainingPCT";
BA_ "Confidence" SG_ 609 VCFRONT_LVBatteryStatusForDrive 0;
BA_ "Confidence" SG_ 609 VCFRONT_LVBatteryType 0;
BA_ "Confidence" SG_ 609 VCFRONT_resistanceEstimationNeed 0;
BA_ "SystemSignalLongSymbol" SG_ 609 VCFRONT_resistanceEstimationNeed "VCFRONT_resistanceEstimationNeeded";
BA_ "Confidence" SG_ 609 VCFRONT_IBSVoltageFiltered 0;
BA_ "GenSigSNA" SG_ 609 VCFRONT_IBSVoltageFiltered "16383";
BA_ "Confidence" SG_ 609 VCFRONT_LVBMS_LVBusVoltageSource 0;
BA_ "SystemSignalLongSymbol" SG_ 609 VCFRONT_LVBMS_LVBusVoltageSource "VCFRONT_LVBMS_LVBusVoltageSourceDBG";
BA_ "Confidence" SG_ 609 VCFRONT_LVBMS_LVPackCurrentSourc 0;
BA_ "SystemSignalLongSymbol" SG_ 609 VCFRONT_LVBMS_LVPackCurrentSourc "VCFRONT_LVBMS_LVPackCurrentSourceDBG";
BA_ "Confidence" SG_ 609 VCFRONT_LVBatterySupportRqrdTrig 0;
BA_ "SystemSignalLongSymbol" SG_ 609 VCFRONT_LVBatterySupportRqrdTrig "VCFRONT_LVBatterySupportRqrdTrigger";
BA_ "Confidence" SG_ 609 VCFRONT_goodForPCSPowerCycleLeak 0;
BA_ "SystemSignalLongSymbol" SG_ 609 VCFRONT_goodForPCSPowerCycleLeak "VCFRONT_goodForPCSPowerCycleLeakyBktDBG";
BA_ "Confidence" SG_ 609 VCFRONT_LVBusControlsFutile 0;
BA_ "Confidence" SG_ 609 VCFRONT_resistanceEstimatio_0001 0;
BA_ "SystemSignalLongSymbol" SG_ 609 VCFRONT_resistanceEstimatio_0001 "VCFRONT_resistanceEstimationTestValid";
BA_ "Confidence" SG_ 609 VCFRONT_resistanceEstimatio_0002 0;
BA_ "SystemSignalLongSymbol" SG_ 609 VCFRONT_resistanceEstimatio_0002 "VCFRONT_resistanceEstimationTestsExpended";
BA_ "Confidence" SG_ 609 VCFRONT_goodLVChargeForUpdate 0;
BA_ "Confidence" SG_ 609 VCFRONT_opportunisticDCRTestNeed 0;
BA_ "SystemSignalLongSymbol" SG_ 609 VCFRONT_opportunisticDCRTestNeed "VCFRONT_opportunisticDCRTestNeeded";
BA_ "Confidence" SG_ 609 VCFRONT_voltageProfile 0;
BA_ "Confidence" SG_ 609 VCFRONT_IBSAmpHours 0;
BA_ "Confidence" SG_ 609 VCFRONT_IBSVoltageRawDBG 0;
BA_ "GenSigSNA" SG_ 609 VCFRONT_IBSVoltageRawDBG "16383";
BA_ "Confidence" SG_ 609 VCFRONT_LVBatteryLINCommsDetecte 0;
BA_ "SystemSignalLongSymbol" SG_ 609 VCFRONT_LVBatteryLINCommsDetecte "VCFRONT_LVBatteryLINCommsDetectedDBG";
BA_ "Confidence" SG_ 609 VCFRONT_voltageSensorMismatchLea 0;
BA_ "SystemSignalLongSymbol" SG_ 609 VCFRONT_voltageSensorMismatchLea "VCFRONT_voltageSensorMismatchLeakyBktPctDBG";
BA_ "Confidence" SG_ 609 VCFRONT_LVBusControlMode 0;
BA_ "Confidence" SG_ 609 VCFRONT_resistanceEstimationExte 0;
BA_ "SystemSignalLongSymbol" SG_ 609 VCFRONT_resistanceEstimationExte "VCFRONT_resistanceEstimationExtendedTestEnabled";
BA_ "Confidence" SG_ 609 VCFRONT_LVBatteryFctryLimOverrid 0;
BA_ "SystemSignalLongSymbol" SG_ 609 VCFRONT_LVBatteryFctryLimOverrid "VCFRONT_LVBatteryFctryLimOverrideOk";
BA_ "Confidence" SG_ 609 VCFRONT_LVBatterySPICommsDetecte 0;
BA_ "SystemSignalLongSymbol" SG_ 609 VCFRONT_LVBatterySPICommsDetecte "VCFRONT_LVBatterySPICommsDetectedDBG";
BA_ "Confidence" SG_ 609 VCFRONT_targetCurrent 0;
BA_ "Confidence" SG_ 609 VCFRONT_PCSMia 0;
BA_ "Confidence" SG_ 609 VCFRONT_chargeNeeded 0;
BA_ "Confidence" SG_ 609 VCFRONT_voltageControlLoopIntegr 0;
BA_ "SystemSignalLongSymbol" SG_ 609 VCFRONT_voltageControlLoopIntegr "VCFRONT_voltageControlLoopIntegrationVal";
BA_ "Confidence" SG_ 609 VCFRONT_currentControlLoopIntegr 0;
BA_ "SystemSignalLongSymbol" SG_ 609 VCFRONT_currentControlLoopIntegr "VCFRONT_currentControlLoopIntegrationVal";
BA_ "Confidence" SG_ 1847 VCFRONT_LVBMS_InfoIndex 1;
BA_ "Confidence" SG_ 1847 VCFRONT_LVBMS_PcbaId 0;
BA_ "Confidence" SG_ 1847 VCFRONT_LVBMS_AssemblyId 0;
BA_ "Confidence" SG_ 1847 VCFRONT_LVBMS_SubUsageId 0;
BA_ "GenSigSNA" SG_ 1847 VCFRONT_LVBMS_SubUsageId "65535";
BA_ "Confidence" SG_ 1847 VCFRONT_LVBMS_UsageId 0;
BA_ "Confidence" SG_ 1847 VCFRONT_LVBMS_AppCRC 0;
BA_ "Confidence" SG_ 1847 VCFRONT_LVBMS_FWBuildType 0;
BA_ "Confidence" SG_ 1140 VCFRONT_LVHealthChecksum 0;
BA_ "Confidence" SG_ 1140 VCFRONT_LVHealthCounter 0;
BA_ "Confidence" SG_ 1140 VCFRONT_LVHealthStatus 0;
BA_ "Confidence" SG_ 1140 VCFRONT_LVStatusForDrive 0;
BA_ "Confidence" SG_ 1140 VCFRONT_LVPowerSecondsToSafeHarb 0;
BA_ "SystemSignalLongSymbol" SG_ 1140 VCFRONT_LVPowerSecondsToSafeHarb "VCFRONT_LVPowerSecondsToSafeHarbor";
BA_ "Confidence" SG_ 1140 VCFRONT_hardwareProtectionsArmed 0;
BA_ "Confidence" SG_ 1140 VCFRONT_lockoutStrategy 0;
BA_ "Confidence" SG_ 1173 VCFRONT_LVHealthDebugIndex 1;
BA_ "Confidence" SG_ 1173 VCFRONT_LVHEALTH_placeholder 0;
BA_ "Confidence" SG_ 1173 VCFRONT_LVHEALTH_activeDecelEner 0;
BA_ "SystemSignalLongSymbol" SG_ 1173 VCFRONT_LVHEALTH_activeDecelEner "VCFRONT_LVHEALTH_activeDecelEnergyWarning";
BA_ "Confidence" SG_ 1173 VCFRONT_LVHEALTH_criticalPullove 0;
BA_ "SystemSignalLongSymbol" SG_ 1173 VCFRONT_LVHEALTH_criticalPullove "VCFRONT_LVHEALTH_criticalPulloverEnergyWarning";
BA_ "Confidence" SG_ 1173 VCFRONT_LVHEALTH_revBattEFuseOff 0;
BA_ "Confidence" SG_ 1173 VCFRONT_LVHEALTH_LVBMBEFuseOpen 0;
BA_ "Confidence" SG_ 1173 VCFRONT_LVHEALTH_lvBatteryCommsM 0;
BA_ "SystemSignalLongSymbol" SG_ 1173 VCFRONT_LVHEALTH_lvBatteryCommsM "VCFRONT_LVHEALTH_lvBatteryCommsMia";
BA_ "Confidence" SG_ 1173 VCFRONT_LVHEALTH_pcsEFuseOff 0;
BA_ "Confidence" SG_ 1173 VCFRONT_LVHEALTH_pcsNotActive 0;
BA_ "Confidence" SG_ 1173 VCFRONT_LVHEALTH_pcsMIA 0;
BA_ "Confidence" SG_ 1173 VCFRONT_LVHEALTH_IBSMIA 0;
BA_ "Confidence" SG_ 1173 VCFRONT_LVHEALTH_LVBatteryElecDi 0;
BA_ "SystemSignalLongSymbol" SG_ 1173 VCFRONT_LVHEALTH_LVBatteryElecDi "VCFRONT_LVHEALTH_LVBatteryElecDisc";
BA_ "Confidence" SG_ 1173 VCFRONT_LVHEALTH_LVBatteryE_0001 0;
BA_ "SystemSignalLongSymbol" SG_ 1173 VCFRONT_LVHEALTH_LVBatteryE_0001 "VCFRONT_LVHEALTH_LVBatteryElecDiscUnknown";
BA_ "Confidence" SG_ 1173 VCFRONT_LVHEALTH_pcsOpenCircuit 0;
BA_ "Confidence" SG_ 1173 VCFRONT_LVHEALTH_activeDecelPowe 0;
BA_ "SystemSignalLongSymbol" SG_ 1173 VCFRONT_LVHEALTH_activeDecelPowe "VCFRONT_LVHEALTH_activeDecelPowerWarning";
BA_ "Confidence" SG_ 1173 VCFRONT_LVHEALTH_lvBatteryCapabi 0;
BA_ "SystemSignalLongSymbol" SG_ 1173 VCFRONT_LVHEALTH_lvBatteryCapabi "VCFRONT_LVHEALTH_lvBatteryCapabilityLowAccuracy";
BA_ "Confidence" SG_ 1173 VCFRONT_LVHEALTH_lvBatteryConfig 0;
BA_ "SystemSignalLongSymbol" SG_ 1173 VCFRONT_LVHEALTH_lvBatteryConfig "VCFRONT_LVHEALTH_lvBatteryConfiguration";
BA_ "Confidence" SG_ 1173 VCFRONT_LVHEALTH_lvBatteryImpeda 0;
BA_ "SystemSignalLongSymbol" SG_ 1173 VCFRONT_LVHEALTH_lvBatteryImpeda "VCFRONT_LVHEALTH_lvBatteryImpedance";
BA_ "Confidence" SG_ 1173 VCFRONT_LVHEALTH_lvBatteryExtend 0;
BA_ "SystemSignalLongSymbol" SG_ 1173 VCFRONT_LVHEALTH_lvBatteryExtend "VCFRONT_LVHEALTH_lvBatteryExtendedOverVoltage";
BA_ "Confidence" SG_ 545 VCFRONT_LVPowerStateIndex 1;
BA_ "Confidence" SG_ 545 VCFRONT_vehiclePowerState 0;
BA_ "Confidence" SG_ 545 VCFRONT_inAccessoryPlus 0;
BA_ "Confidence" SG_ 545 VCFRONT_LVShuttingDown 0;
BA_ "Confidence" SG_ 545 VCFRONT_LVPowerStateCounter 0;
BA_ "Confidence" SG_ 545 VCFRONT_LVPowerStateChecksum 0;
BA_ "Confidence" SG_ 545 VCFRONT_cpLVRequest 0;
BA_ "Confidence" SG_ 545 VCFRONT_epasLVState 0;
BA_ "Confidence" SG_ 545 VCFRONT_hvcLVRequest 0;
BA_ "Confidence" SG_ 545 VCFRONT_tasLVState 0;
BA_ "Confidence" SG_ 545 VCFRONT_pcsLVState 0;
BA_ "Confidence" SG_ 545 VCFRONT_CMPDLVState 0;
BA_ "Confidence" SG_ 545 VCFRONT_hcmlLVState 0;
BA_ "Confidence" SG_ 545 VCFRONT_hcmrLVState 0;
BA_ "Confidence" SG_ 545 VCFRONT_MCUAudioLVState 0;
BA_ "Confidence" SG_ 545 VCFRONT_espValveLVState 0;
BA_ "Confidence" SG_ 545 VCFRONT_MCUGraphicsLVState 0;
BA_ "Confidence" SG_ 545 VC_dcdcSupportRequest 0;
BA_ "Confidence" SG_ 545 VC_hvStateRequest 0;
BA_ "Confidence" SG_ 545 VC_autonomyBehavior 0;
BA_ "Confidence" SG_ 545 VC_persistAccPowerRequestOverrid 0;
BA_ "SystemSignalLongSymbol" SG_ 545 VC_persistAccPowerRequestOverrid "VC_persistAccPowerRequestOverridden";
BA_ "Confidence" SG_ 545 VC_accPortPowerRequest 0;
BA_ "Confidence" SG_ 545 VC_persistAccPortPowerState 0;
BA_ "Confidence" SG_ 545 VC_noAccDeviceDetectedWhileIdle 0;
BA_ "Confidence" SG_ 700 VCFRONT_LVThermalMotorsIndex 1;
BA_ "Confidence" SG_ 700 VCFRONT_radiatorFanState 0;
BA_ "Confidence" SG_ 700 VCFRONT_radiatorFanTorque 0;
BA_ "GenSigSNA" SG_ 700 VCFRONT_radiatorFanTorque "1023";
BA_ "Confidence" SG_ 700 VCFRONT_radiatorFanIDc 0;
BA_ "GenSigSNA" SG_ 700 VCFRONT_radiatorFanIDc "127";
BA_ "Confidence" SG_ 700 VCFRONT_mlxLINCurrentSchedule 0;
BA_ "Confidence" SG_ 700 VCFRONT_pumpPowertrainState 0;
BA_ "Confidence" SG_ 700 VCFRONT_pumpPowertrainTorque 0;
BA_ "GenSigSNA" SG_ 700 VCFRONT_pumpPowertrainTorque "1023";
BA_ "Confidence" SG_ 700 VCFRONT_pumpPowertrainIDc 0;
BA_ "GenSigSNA" SG_ 700 VCFRONT_pumpPowertrainIDc "127";
BA_ "Confidence" SG_ 700 VCFRONT_pumpBatteryState 0;
BA_ "Confidence" SG_ 700 VCFRONT_pumpBatteryTorque 0;
BA_ "GenSigSNA" SG_ 700 VCFRONT_pumpBatteryTorque "1023";
BA_ "Confidence" SG_ 700 VCFRONT_pumpBatteryIDc 0;
BA_ "GenSigSNA" SG_ 700 VCFRONT_pumpBatteryIDc "127";
BA_ "Confidence" SG_ 577 VCFRONT_coolantFlowBatActual 0;
BA_ "Confidence" SG_ 577 VCFRONT_coolantFlowBatTarget 0;
BA_ "Confidence" SG_ 577 VCFRONT_coolantFlowBatReason 0;
BA_ "Confidence" SG_ 577 VCFRONT_coolantFlowPTActual 0;
BA_ "Confidence" SG_ 577 VCFRONT_coolantFlowPTTarget 0;
BA_ "Confidence" SG_ 577 VCFRONT_coolantFlowPTReason 0;
BA_ "Confidence" SG_ 577 VCFRONT_wasteHeatRequestType 0;
BA_ "Confidence" SG_ 577 VCFRONT_coolantHasBeenFilled 0;
BA_ "Confidence" SG_ 577 VCFRONT_radiatorIneffective 0;
BA_ "Confidence" SG_ 577 VCFRONT_coolantAirPurgeBatState 0;
BA_ "Confidence" SG_ 577 VCFRONT_coolantFlowTableConfig 0;
BA_ "Confidence" SG_ 577 VCFRONT_coolantLevelContinuously 0;
BA_ "SystemSignalLongSymbol" SG_ 577 VCFRONT_coolantLevelContinuously "VCFRONT_coolantLevelContinuouslyLow";
BA_ "Confidence" SG_ 753 VCFRONT_eFuseDebugStatusIndex 1;
BA_ "Confidence" SG_ 753 VCFRONT_leftControllerState 0;
BA_ "GenSigSNA" SG_ 753 VCFRONT_leftControllerState "3";
BA_ "Confidence" SG_ 753 VCFRONT_leftControllerFault 0;
BA_ "Confidence" SG_ 753 VCFRONT_vcleftSelfTestResult 0;
BA_ "GenSigSNA" SG_ 753 VCFRONT_vcleftSelfTestResult "12";
BA_ "Confidence" SG_ 753 VCFRONT_leftControllerTemp 0;
BA_ "Confidence" SG_ 753 VCFRONT_leftControllerEFuseVNFSt 0;
BA_ "SystemSignalLongSymbol" SG_ 753 VCFRONT_leftControllerEFuseVNFSt "VCFRONT_leftControllerEFuseVNFState";
BA_ "Confidence" SG_ 753 VCFRONT_leftControllerEFuseOutpu 0;
BA_ "SystemSignalLongSymbol" SG_ 753 VCFRONT_leftControllerEFuseOutpu "VCFRONT_leftControllerEFuseOutput";
BA_ "Confidence" SG_ 753 VCFRONT_leftControllerEFuse_0002 0;
BA_ "SystemSignalLongSymbol" SG_ 753 VCFRONT_leftControllerEFuse_0002 "VCFRONT_leftControllerEFuseOutputDesired";
BA_ "Confidence" SG_ 753 VCFRONT_leftControllerVoltage 0;
BA_ "Confidence" SG_ 753 VCFRONT_leftControllerEFuseBypas 0;
BA_ "SystemSignalLongSymbol" SG_ 753 VCFRONT_leftControllerEFuseBypas "VCFRONT_leftControllerEFuseBypass";
BA_ "Confidence" SG_ 753 VCFRONT_leftControllerEFuse_0001 0;
BA_ "SystemSignalLongSymbol" SG_ 753 VCFRONT_leftControllerEFuse_0001 "VCFRONT_leftControllerEFuseBypassDesired";
BA_ "Confidence" SG_ 753 VCFRONT_leftControllerCurrent 0;
BA_ "Confidence" SG_ 753 VCFRONT_leftControllerEFuseVNFSe 0;
BA_ "SystemSignalLongSymbol" SG_ 753 VCFRONT_leftControllerEFuseVNFSe "VCFRONT_leftControllerEFuseVNFSelfTestStatus";
BA_ "Confidence" SG_ 753 VCFRONT_PCSState 0;
BA_ "GenSigSNA" SG_ 753 VCFRONT_PCSState "3";
BA_ "Confidence" SG_ 753 VCFRONT_PCSFault 0;
BA_ "Confidence" SG_ 753 VCFRONT_pcsSelfTestResult 0;
BA_ "GenSigSNA" SG_ 753 VCFRONT_pcsSelfTestResult "12";
BA_ "Confidence" SG_ 753 VCFRONT_PCSTemp 0;
BA_ "Confidence" SG_ 753 VCFRONT_PCSEFuseVNFState 0;
BA_ "Confidence" SG_ 753 VCFRONT_PCSEFuseOutput 0;
BA_ "Confidence" SG_ 753 VCFRONT_PCSEFuseOutputDesired 0;
BA_ "Confidence" SG_ 753 VCFRONT_PCSVoltage 0;
BA_ "Confidence" SG_ 753 VCFRONT_PCSEFuseBypass 0;
BA_ "Confidence" SG_ 753 VCFRONT_PCSEFuseBypassDesired 0;
BA_ "Confidence" SG_ 753 VCFRONT_PCSEFuseVNFSelfTestStatu 0;
BA_ "SystemSignalLongSymbol" SG_ 753 VCFRONT_PCSEFuseVNFSelfTestStatu "VCFRONT_PCSEFuseVNFSelfTestStatus";
BA_ "Confidence" SG_ 753 VCFRONT_iBoosterState 0;
BA_ "GenSigSNA" SG_ 753 VCFRONT_iBoosterState "3";
BA_ "Confidence" SG_ 753 VCFRONT_iBoosterFault 0;
BA_ "Confidence" SG_ 753 VCFRONT_iBoosterSelfTestResult 0;
BA_ "GenSigSNA" SG_ 753 VCFRONT_iBoosterSelfTestResult "12";
BA_ "Confidence" SG_ 753 VCFRONT_iBoosterTemp 0;
BA_ "Confidence" SG_ 753 VCFRONT_iBoosterEFuseVNFState 0;
BA_ "Confidence" SG_ 753 VCFRONT_iBoosterEFuseOutput 0;
BA_ "Confidence" SG_ 753 VCFRONT_iBoosterEFuseOutputDesir 0;
BA_ "SystemSignalLongSymbol" SG_ 753 VCFRONT_iBoosterEFuseOutputDesir "VCFRONT_iBoosterEFuseOutputDesired";
BA_ "Confidence" SG_ 753 VCFRONT_iBoosterVoltage 0;
BA_ "Confidence" SG_ 753 VCFRONT_iBoosterHardshortThresho 0;
BA_ "SystemSignalLongSymbol" SG_ 753 VCFRONT_iBoosterHardshortThresho "VCFRONT_iBoosterHardshortThresholdDbg";
BA_ "Confidence" SG_ 753 VCFRONT_iBoosterEFuseBypass 0;
BA_ "Confidence" SG_ 753 VCFRONT_iBoosterEFuseBypassDesir 0;
BA_ "SystemSignalLongSymbol" SG_ 753 VCFRONT_iBoosterEFuseBypassDesir "VCFRONT_iBoosterEFuseBypassDesired";
BA_ "Confidence" SG_ 753 VCFRONT_iBoosterCurrent 0;
BA_ "Confidence" SG_ 753 VCFRONT_iBoosterEFuseVNFSelfTest 0;
BA_ "SystemSignalLongSymbol" SG_ 753 VCFRONT_iBoosterEFuseVNFSelfTest "VCFRONT_iBoosterEFuseVNFSelfTestStatus";
BA_ "Confidence" SG_ 753 VCFRONT_EPAS3PState 0;
BA_ "GenSigSNA" SG_ 753 VCFRONT_EPAS3PState "3";
BA_ "Confidence" SG_ 753 VCFRONT_EPAS3PFault 0;
BA_ "Confidence" SG_ 753 VCFRONT_EPAS3PSelfTestResult 0;
BA_ "GenSigSNA" SG_ 753 VCFRONT_EPAS3PSelfTestResult "12";
BA_ "Confidence" SG_ 753 VCFRONT_EPAS3PTemp 0;
BA_ "Confidence" SG_ 753 VCFRONT_EPAS3PEFuseVNFState 0;
BA_ "Confidence" SG_ 753 VCFRONT_EPAS3PEFuseOutput 0;
BA_ "Confidence" SG_ 753 VCFRONT_EPAS3PEFuseOutputDesired 0;
BA_ "Confidence" SG_ 753 VCFRONT_EPAS3PVoltage 0;
BA_ "Confidence" SG_ 753 VCFRONT_EPAS3PEFuseHardshortThre 0;
BA_ "SystemSignalLongSymbol" SG_ 753 VCFRONT_EPAS3PEFuseHardshortThre "VCFRONT_EPAS3PEFuseHardshortThresholdDbg";
BA_ "Confidence" SG_ 753 VCFRONT_EPAS3PEFuseBypass 0;
BA_ "Confidence" SG_ 753 VCFRONT_EPAS3PEFuseBypassDesired 0;
BA_ "Confidence" SG_ 753 VCFRONT_EPAS3PCurrent 0;
BA_ "Confidence" SG_ 753 VCFRONT_EPAS3PEFuseVNFSelfTestSt 0;
BA_ "SystemSignalLongSymbol" SG_ 753 VCFRONT_EPAS3PEFuseVNFSelfTestSt "VCFRONT_EPAS3PEFuseVNFSelfTestStatus";
BA_ "Confidence" SG_ 753 VCFRONT_EPAS3SState 0;
BA_ "GenSigSNA" SG_ 753 VCFRONT_EPAS3SState "3";
BA_ "Confidence" SG_ 753 VCFRONT_EPAS3SFault 0;
BA_ "Confidence" SG_ 753 VCFRONT_EPAS3SSelfTestResult 0;
BA_ "GenSigSNA" SG_ 753 VCFRONT_EPAS3SSelfTestResult "12";
BA_ "Confidence" SG_ 753 VCFRONT_EPAS3STemp 0;
BA_ "Confidence" SG_ 753 VCFRONT_EPAS3SEFuseVNFState 0;
BA_ "Confidence" SG_ 753 VCFRONT_EPAS3SEFuseOutput 0;
BA_ "Confidence" SG_ 753 VCFRONT_EPAS3SEFuseOutputDesired 0;
BA_ "Confidence" SG_ 753 VCFRONT_EPAS3SVoltage 0;
BA_ "Confidence" SG_ 753 VCFRONT_EPAS3SEFuseBypass 0;
BA_ "Confidence" SG_ 753 VCFRONT_EPAS3SEFuseBypassDesired 0;
BA_ "Confidence" SG_ 753 VCFRONT_EPAS3SCurrent 0;
BA_ "Confidence" SG_ 753 VCFRONT_EPAS3SEFuseVNFSelfTestSt 0;
BA_ "SystemSignalLongSymbol" SG_ 753 VCFRONT_EPAS3SEFuseVNFSelfTestSt "VCFRONT_EPAS3SEFuseVNFSelfTestStatus";
BA_ "Confidence" SG_ 753 VCFRONT_ESPMotorState 0;
BA_ "GenSigSNA" SG_ 753 VCFRONT_ESPMotorState "3";
BA_ "Confidence" SG_ 753 VCFRONT_ESPMotorFault 0;
BA_ "Confidence" SG_ 753 VCFRONT_ESPMotorSelfTestResult 0;
BA_ "GenSigSNA" SG_ 753 VCFRONT_ESPMotorSelfTestResult "12";
BA_ "Confidence" SG_ 753 VCFRONT_ESPMotorTemp 0;
BA_ "Confidence" SG_ 753 VCFRONT_ESPMotorEFuseVNFState 0;
BA_ "Confidence" SG_ 753 VCFRONT_ESPMotorEFuseOutput 0;
BA_ "Confidence" SG_ 753 VCFRONT_ESPMotorEFuseOutputDesir 0;
BA_ "SystemSignalLongSymbol" SG_ 753 VCFRONT_ESPMotorEFuseOutputDesir "VCFRONT_ESPMotorEFuseOutputDesired";
BA_ "Confidence" SG_ 753 VCFRONT_ESPMotorVoltage 0;
BA_ "Confidence" SG_ 753 VCFRONT_ESPMotorEFuseBypass 0;
BA_ "Confidence" SG_ 753 VCFRONT_ESPMotorEFuseBypassDesir 0;
BA_ "SystemSignalLongSymbol" SG_ 753 VCFRONT_ESPMotorEFuseBypassDesir "VCFRONT_ESPMotorEFuseBypassDesired";
BA_ "Confidence" SG_ 753 VCFRONT_ESPMotorCurrent 0;
BA_ "Confidence" SG_ 753 VCFRONT_ESPMotorEFuseVNFSelfTest 0;
BA_ "SystemSignalLongSymbol" SG_ 753 VCFRONT_ESPMotorEFuseVNFSelfTest "VCFRONT_ESPMotorEFuseVNFSelfTestStatus";
BA_ "Confidence" SG_ 753 VCFRONT_ESPValveState 0;
BA_ "GenSigSNA" SG_ 753 VCFRONT_ESPValveState "3";
BA_ "Confidence" SG_ 753 VCFRONT_ESPValveFault 0;
BA_ "Confidence" SG_ 753 VCFRONT_ESPValveTemp 0;
BA_ "Confidence" SG_ 753 VCFRONT_ESPValveVoltage 0;
BA_ "Confidence" SG_ 753 VCFRONT_ESPValveCurrent 0;
BA_ "Confidence" SG_ 753 VCFRONT_autopilot2State 0;
BA_ "GenSigSNA" SG_ 753 VCFRONT_autopilot2State "3";
BA_ "Confidence" SG_ 753 VCFRONT_autopilot2Fault 0;
BA_ "Confidence" SG_ 753 VCFRONT_autopilot2Temp 0;
BA_ "Confidence" SG_ 753 VCFRONT_autopilot2Voltage 0;
BA_ "Confidence" SG_ 753 VCFRONT_autopilot2Current 0;
BA_ "Confidence" SG_ 753 VCFRONT_sleepBypassState 0;
BA_ "Confidence" SG_ 753 VCFRONT_sleepBypassFault 0;
BA_ "Confidence" SG_ 753 VCFRONT_sleepBypassVoltage 0;
BA_ "Confidence" SG_ 753 VCFRONT_sleepBypassCurrent 0;
BA_ "Confidence" SG_ 753 VCFRONT_vbatFusedHighState 0;
BA_ "Confidence" SG_ 753 VCFRONT_vbatFusedHighFault 0;
BA_ "Confidence" SG_ 753 VCFRONT_vbatFusedSelfTestResult 0;
BA_ "GenSigSNA" SG_ 753 VCFRONT_vbatFusedSelfTestResult "12";
BA_ "Confidence" SG_ 753 VCFRONT_vbatFusedHighTemp 0;
BA_ "Confidence" SG_ 753 VCFRONT_vbatFusedHighVoltage 0;
BA_ "Confidence" SG_ 753 VCFRONT_vbatFusedHighCurrent 0;
BA_ "Confidence" SG_ 753 VCFRONT_chargedIBSAmpHours 0;
BA_ "Confidence" SG_ 753 VCFRONT_dischargedIBSAmpHours 0;
BA_ "Confidence" SG_ 753 VCFRONT_IBSUnfilteredTemperature 0;
BA_ "GenSigSNA" SG_ 753 VCFRONT_IBSUnfilteredTemperature "32768";
BA_ "Confidence" SG_ 1353 VCFRONT_homelinkV2Response0 0;
BA_ "Confidence" SG_ 1353 VCFRONT_homelinkV2Response1 0;
BA_ "Confidence" SG_ 1353 VCFRONT_homelinkV2Response2 0;
BA_ "Confidence" SG_ 1353 VCFRONT_homelinkV2Response3 0;
BA_ "Confidence" SG_ 1353 VCFRONT_homelinkV2Response4 0;
BA_ "Confidence" SG_ 1353 VCFRONT_homelinkCommStatus 0;
BA_ "GenSigSNA" SG_ 1353 VCFRONT_homelinkCommStatus "0";
VAL_ 947 UI_lightSwitch 4 "LIGHT_SWITCH_SNA" 3 "LIGHT_SWITCH_OFF" 2 "LIGHT_SWITCH_PARKING" 1 "LIGHT_SWITCH_ON" 0 "LIGHT_SWITCH_AUTO" ;
VAL_ 947 UI_autopilotPowerStateRequest 2 "AUTOPILOT_SUSPEND" 1 "AUTOPILOT_SENTRY" 0 "AUTOPILOT_NOMINAL" ;
VAL_ 947 UI_frontLeftSeatFanReq 3 "FAN_REQUEST_LEVEL3" 2 "FAN_REQUEST_LEVEL2" 1 "FAN_REQUEST_LEVEL1" 0 "FAN_REQUEST_OFF" ;
VAL_ 947 UI_frontRightSeatFanReq 3 "FAN_REQUEST_LEVEL3" 2 "FAN_REQUEST_LEVEL2" 1 "FAN_REQUEST_LEVEL1" 0 "FAN_REQUEST_OFF" ;
VAL_ 660 UI_lightFlashRequest 3 "LIGHT_FLASH_SENTRY" 2 "LIGHT_FLASH_MOBILE_APP" 1 "LIGHT_FLASH_HOMELINK" 0 "LIGHT_FLASH_INACTIVE" ;
VAL_ 660 UI_steeringWheelHeatLevelReq 3 "STEERING_WHEEL_HEAT_LEVEL3" 2 "STEERING_WHEEL_HEAT_LEVEL2" 1 "STEERING_WHEEL_HEAT_LEVEL1" 0 "STEERING_WHEEL_HEAT_OFF" ;
VAL_ 660 UI_leftRearSeatAdjustmentRequest 6 "UI_ADJUSTABLE_FOLD_FLAT_REQUEST_STOP" 5 "UI_ADJUSTABLE_FOLD_FLAT_REQUEST_TOGGLE_FOLD" 4 "UI_ADJUSTABLE_FOLD_FLAT_REQUEST_REARWARD_FAST" 3 "UI_ADJUSTABLE_FOLD_FLAT_REQUEST_REARWARD_COMFORT" 2 "UI_ADJUSTABLE_FOLD_FLAT_REQUEST_FORWARD_FAST" 1 "UI_ADJUSTABLE_FOLD_FLAT_REQUEST_FORWARD_COMFORT" 0 "UI_ADJUSTABLE_FOLD_FLAT_REQUEST_NONE" ;
VAL_ 660 UI_rightRearSeatAdjustmentReques 6 "UI_ADJUSTABLE_FOLD_FLAT_REQUEST_STOP" 5 "UI_ADJUSTABLE_FOLD_FLAT_REQUEST_TOGGLE_FOLD" 4 "UI_ADJUSTABLE_FOLD_FLAT_REQUEST_REARWARD_FAST" 3 "UI_ADJUSTABLE_FOLD_FLAT_REQUEST_REARWARD_COMFORT" 2 "UI_ADJUSTABLE_FOLD_FLAT_REQUEST_FORWARD_FAST" 1 "UI_ADJUSTABLE_FOLD_FLAT_REQUEST_FORWARD_COMFORT" 0 "UI_ADJUSTABLE_FOLD_FLAT_REQUEST_NONE" ;
VAL_ 660 UI_rearSeatChildLock 3 "UI_ADJUSTABLE_FOLD_FLAT_CHILD_LOCK_BOTH" 2 "UI_ADJUSTABLE_FOLD_FLAT_CHILD_LOCK_RIGHT" 1 "UI_ADJUSTABLE_FOLD_FLAT_CHILD_LOCK_LEFT" 0 "UI_ADJUSTABLE_FOLD_FLAT_CHILD_LOCK_NONE" ;
VAL_ 660 UI_windowRequest 6 "WINDOW_REQUEST_GOTO_RELATIVE_PERCENT" 5 "WINDOW_REQUEST_GOTO_CLOSED_CARWASH" 4 "WINDOW_REQUEST_GOTO_OPEN" 3 "WINDOW_REQUEST_GOTO_CLOSED" 2 "WINDOW_REQUEST_GOTO_VENT" 1 "WINDOW_REQUEST_GOTO_PERCENT" 0 "WINDOW_REQUEST_IDLE" ;
VAL_ 1193 UI_firstRowLeftDomeLightRequest 1 "DOME_LIGHT_REQUEST_ACTIVE" 0 "DOME_LIGHT_REQUEST_NONE" ;
VAL_ 1193 UI_firstRowRightDomeLightRequest 1 "DOME_LIGHT_REQUEST_ACTIVE" 0 "DOME_LIGHT_REQUEST_NONE" ;
VAL_ 1193 UI_secondRowLeftDomeLightRequest 1 "DOME_LIGHT_REQUEST_ACTIVE" 0 "DOME_LIGHT_REQUEST_NONE" ;
VAL_ 1193 UI_secondRowCenterDomeLightReque 1 "DOME_LIGHT_REQUEST_ACTIVE" 0 "DOME_LIGHT_REQUEST_NONE" ;
VAL_ 1193 UI_secondRowRightDomeLightReques 1 "DOME_LIGHT_REQUEST_ACTIVE" 0 "DOME_LIGHT_REQUEST_NONE" ;
VAL_ 1193 UI_thirdRowLeftDomeLightRequest 1 "DOME_LIGHT_REQUEST_ACTIVE" 0 "DOME_LIGHT_REQUEST_NONE" ;
VAL_ 1193 UI_thirdRowRightDomeLightRequest 1 "DOME_LIGHT_REQUEST_ACTIVE" 0 "DOME_LIGHT_REQUEST_NONE" ;
VAL_ 644 UI_transportMode 1 "TRANSPORT_MODE_ENABLED" 0 "TRANSPORT_MODE_DISABLED" ;
VAL_ 644 UI_showroomMode 1 "SHOWROOM_MODE_ENABLED" 0 "SHOWROOM_MODE_DISABLED" ;
VAL_ 644 UI_serviceMode 1 "SERVICE_MODE_ENABLED" 0 "SERVICE_MODE_DISABLED" ;
VAL_ 644 UI_serviceModePlus 1 "SERVICE_MODE_PLUS_ENABLED" 0 "SERVICE_MODE_PLUS_DISABLED" ;
VAL_ 644 UI_lightShowType 5 "LIGHT_SHOW_TYPE_STANDARD_CNY24" 4 "LIGHT_SHOW_TYPE_STANDARD_THE_ARRIVAL" 3 "LIGHT_SHOW_TYPE_STANDARD_CNY23" 2 "LIGHT_SHOW_TYPE_STANDARD_AULD_LANG_SYNE" 1 "LIGHT_SHOW_TYPE_STANDARD_CAROL_OF_THE_BELLS" 0 "LIGHT_SHOW_TYPE_CUSTOM_USB" ;
VAL_ 644 UI_upkeepMode 1 "UI_UPKEEPMODE_ENABLED" 0 "UI_UPKEEPMODE_DISABLED" ;
VAL_ 595 UI_ventPanelControlRequestIndex 1 "1" 0 "0" ;
VAL_ 595 UI_ventPanelLeftLateralMode 2 "SWING" 1 "SPLIT" 0 "SINGLE" ;
VAL_ 595 UI_ventPanelRightLateralMode 2 "SWING" 1 "SPLIT" 0 "SINGLE" ;
VAL_ 595 UI_hvacReqActiveVents 3 "OFF" 2 "RIGHT" 1 "LEFT" 0 "BOTH" ;
VAL_ 595 UI_hvacReqThirdRowState 2 "ON" 1 "OFF" 0 "AUTO" ;
VAL_ 1285 SA_infoIndex 32 "Mux32" 31 "Mux31" 30 "Mux30" 29 "Mux29" 27 "Mux27" 26 "Mux26" 25 "Mux25" 11 "Mux11" 0 "Mux0" ;
VAL_ 1285 SA_region 6 "SA_REGION_INDIA" 5 "SA_REGION_SOUTH_KOREA" 4 "SA_REGION_AUSTRALIA" 3 "SA_REGION_JAPAN" 2 "SA_REGION_CHINA" 1 "SA_REGION_EU" 0 "SA_REGION_NA" ;
VAL_ 1949 V2G_evseLogDataSelect 17 "NUM_MSG" 16 "MSG_NONE" 15 "SESSION_STOP" 14 "WELDING_DETECTION" 13 "POWER_DELIVERY_END" 12 "CHARGING_STATUS" 11 "CURRENT_DEMAND" 10 "POWER_DELIVERY_START" 9 "PRECHARGE" 8 "CABLE_CHECK" 7 "CHARGE_PARAMETER_DISCOVERY" 6 "CONTRACT_AUTHENTICATION" 5 "PAYMENT_DETAILS" 4 "SERVICE_PAYMENT_SELECTION" 3 "SERVICE_DETAIL" 2 "SERVICE_DISCOVERY" 1 "SESSION_SETUP" 0 "SUPPORTED_APP_PROTOCOL" ;
VAL_ 1949 V2G_chgParamRes_respCode 27 "CCS_EVSE_RESP_CODE_MAX" 26 "CCS_EVSE_RESP_CODE_FAILED_CERT_REVOKED" 25 "CCS_EVSE_RESP_CODE_FAILED_CERT_NOT_ALLOWED_AT_EVSE" 24 "CCS_EVSE_RESP_CODE_FAILED_CONTACTOR_ERROR" 23 "CCS_EVSE_RESP_CODE_FAILED_NO_CHARGE_SERVICE_SELECTED" 22 "CCS_EVSE_RESP_CODE_FAILED_WRONG_ENERGY_TRANSFER_TYPE" 21 "CCS_EVSE_RESP_CODE_FAILED_METERING_SIGNATURE_NOT_VALID" 20 "CCS_EVSE_RESP_CODE_FAILED_EVSE_PRESENT_VOLTAGE_TOO_LOW" 19 "CCS_EVSE_RESP_CODE_FAILED_CHARGING_PROFILE_INVALID" 18 "CCS_EVSE_RESP_CODE_FAILED_TARIFF_SELECTION_INVALID" 17 "CCS_EVSE_RESP_CODE_FAILED_POWER_DELIVERY_NOT_APPLIED" 16 "CCS_EVSE_RESP_CODE_FAILED_WRONG_CHARGE_PARAMETER" 15 "CCS_EVSE_RESP_CODE_FAILED_CONTRACT_CANCELED" 14 "CCS_EVSE_RESP_CODE_FAILED_CHALLENGE_INVALID" 13 "CCS_EVSE_RESP_CODE_FAILED_CERT_CHAIN_ERROR" 12 "CCS_EVSE_RESP_CODE_FAILED_NO_CERTIFICATE_AVAILABLE" 11 "CCS_EVSE_RESP_CODE_FAILED_SIGNATURE_ERROR" 10 "CCS_EVSE_RESP_CODE_FAILED_CERTIFICATE_EXPIRED" 9 "CCS_EVSE_RESP_CODE_FAILED_PAYMENT_SELECTION_INVALID" 8 "CCS_EVSE_RESP_CODE_FAILED_SERVICE_SELECTION_INVALID" 7 "CCS_EVSE_RESP_CODE_FAILED_UNKNOWN_SESSION" 6 "CCS_EVSE_RESP_CODE_FAILED_SERVICE_ID_INVALID" 5 "CCS_EVSE_RESP_CODE_FAILED_SEQUENCE_ERROR" 4 "CCS_EVSE_RESP_CODE_FAILED" 3 "CCS_EVSE_RESP_CODE_OK_CERTIFICATE_EXPIRES_SOON" 2 "CCS_EVSE_RESP_CODE_OK_OLD_SESSION_JOINED" 1 "CCS_EVSE_RESP_CODE_OK_NEW_SESSION_ESTABLISHED" 0 "CCS_EVSE_RESP_CODE_OK" ;
VAL_ 1949 V2G_chgParamRes_evseStatus 12 "CCS_DC_EVSE_STATUS_MAX" 11 "CCS_DC_EVSE_STATUS_RESERVED_C" 10 "CCS_DC_EVSE_STATUS_RESERVED_B" 9 "CCS_DC_EVSE_STATUS_RESERVED_A" 8 "CCS_DC_EVSE_STATUS_RESERVED_9" 7 "CCS_DC_EVSE_STATUS_RESERVED_8" 6 "CCS_DC_EVSE_STATUS_MALFUNCTION" 5 "CCS_DC_EVSE_STATUS_EMERGENCY_SHUTDOWN" 4 "CCS_DC_EVSE_STATUS_ISOLATION_MONITORING_ACTIVE" 3 "CCS_DC_EVSE_STATUS_UTILITY_INTERRUPT_EVENT" 2 "CCS_DC_EVSE_STATUS_SHUTDOWN" 1 "CCS_DC_EVSE_STATUS_READY" 0 "CCS_DC_EVSE_STATUS_NOT_READY" ;
VAL_ 1949 V2G_chgParamRes_isoState 4 "CCS_ISOLATION_STATUS_NO_IMD" 3 "CCS_ISOLATION_STATUS_FAULT" 2 "CCS_ISOLATION_STATUS_WARNING" 1 "CCS_ISOLATION_STATUS_VALID" 0 "CCS_ISOLATION_STATUS_INVALID" ;
VAL_ 1858 VCBATT1_lvbmsStatusHighIndex 5 "INVALID" 4 "CELL_VITALS_2_AND_STATE_AND_COMMANDS" 3 "TARGETS" 2 "PCS_INTERFACE" 1 "CELL_VITALS_1" 0 "PACK_VITALS_1" ;
VAL_ 1858 VCBATT1_LVBMS_packCurrent 4194303 "SNA" ;
VAL_ 1858 VCBATT1_LVBMS_packVoltage 65535 "SNA" ;
VAL_ 1858 VCBATT1_LVBMS_packTemperature 511 "SNA" ;
VAL_ 1858 VCBATT1_LVBMS_MOSTemperature 4095 "SNA" ;
VAL_ 1858 VCBATT1_LVBMS_sumCellVoltage 65535 "SNA" 65534 "INVALID" ;
VAL_ 1858 VCBATT1_LVBMS_maxBrickVoltage 8191 "SNA" ;
VAL_ 1858 VCBATT1_LVBMS_maxBrickVoltageInd 255 "SNA" ;
VAL_ 1858 VCBATT1_LVBMS_voltageTarget 65535 "SNA" ;
VAL_ 1858 VCBATT1_LVBMS_currentTarget 262143 "SNA" ;
VAL_ 1858 VCBATT1_LVBMS_maxAllowedChargeCu 8191 "SNA" ;
VAL_ 1858 VCBATT1_LVBMS_maxAllowedDischarg 8191 "SNA" ;
VAL_ 1858 VCBATT1_LVBMS_ECPAState 3 "LVBMS_ECPA_STATE_SNA" 2 "LVBMS_ECPA_STATE_INVALID" 1 "LVBMS_ECPA_STATE_CLOSED" 0 "LVBMS_ECPA_STATE_OPEN" ;
VAL_ 1858 VCBATT1_LVBMS_MOSState 3 "LVBMS_MOS_STATE_SNA" 2 "LVBMS_MOS_STATE_INVALID" 1 "LVBMS_MOS_STATE_CLOSED" 0 "LVBMS_MOS_STATE_OPEN" ;
VAL_ 1858 VCBATT1_LVBMS_VehicleState 3 "LVBMS_VEHICLE_STATE_OFF" 2 "LVBMS_VEHICLE_STATE_CONDITIONING" 1 "LVBMS_VEHICLE_STATE_ACCESSORY" 0 "LVBMS_VEHICLE_STATE_DRIVE" ;
VAL_ 1858 VCBATT1_LVBMS_LINWakeDisabled 1 "LVBMS_LIN_WAKE_DISABLED" 0 "LVBMS_LIN_WAKE_ENABLED" ;
VAL_ 1858 VCBATT1_LVBMS_chargeType 4 "LVBMS_CHARGE_SNA" 3 "LVBMS_CHARGE_COMPLETE" 2 "LVBMS_CHARGE_CONSTANT_VOLTAGE" 1 "LVBMS_CHARGE_CONSTANT_CURRENT" 0 "LVBMS_CHARGE_UNDEFINED" ;
VAL_ 1858 VCBATT1_LVBMS_avgBrickVoltage 8191 "SNA" ;
VAL_ 1858 VCBATT1_LVBMS_minBrickVoltage 8191 "SNA" ;
VAL_ 1858 VCBATT1_LVBMS_minBrickVoltageInd 255 "SNA" ;
VAL_ 1119 VCBATT1_LVSelfTestsIndex 1 "STATES" 0 "ORCHESTRATOR" ;
VAL_ 1119 VCBATT1_battDomainOvercurrentSel 2 "VC_SELF_TEST_RESULT_PASSED" 1 "VC_SELF_TEST_RESULT_FAILED" 0 "VC_SELF_TEST_RESULT_INVALID" ;
VAL_ 1119 VCBATT1_battDomainOvercurre_0001 4 "VC_SELF_TEST_STATE_SNA" 3 "VC_SELF_TEST_STATE_NEW_RESULT" 2 "VC_SELF_TEST_STATE_RUNNING" 1 "VC_SELF_TEST_STATE_PENDING" 0 "VC_SELF_TEST_STATE_IDLE" ;
VAL_ 1119 VCBATT1_battDomainOvervoltageSel 2 "VC_SELF_TEST_RESULT_PASSED" 1 "VC_SELF_TEST_RESULT_FAILED" 0 "VC_SELF_TEST_RESULT_INVALID" ;
VAL_ 1119 VCBATT1_battDomainOvervolta_0001 4 "VC_SELF_TEST_STATE_SNA" 3 "VC_SELF_TEST_STATE_NEW_RESULT" 2 "VC_SELF_TEST_STATE_RUNNING" 1 "VC_SELF_TEST_STATE_PENDING" 0 "VC_SELF_TEST_STATE_IDLE" ;
VAL_ 1119 VCBATT1_battDomainUndervoltageSe 2 "VC_SELF_TEST_RESULT_PASSED" 1 "VC_SELF_TEST_RESULT_FAILED" 0 "VC_SELF_TEST_RESULT_INVALID" ;
VAL_ 1119 VCBATT1_battDomainUndervolt_0001 4 "VC_SELF_TEST_STATE_SNA" 3 "VC_SELF_TEST_STATE_NEW_RESULT" 2 "VC_SELF_TEST_STATE_RUNNING" 1 "VC_SELF_TEST_STATE_PENDING" 0 "VC_SELF_TEST_STATE_IDLE" ;
VAL_ 1119 VCBATT1_dualPowerLoadsSelfTestRe 2 "VC_SELF_TEST_RESULT_PASSED" 1 "VC_SELF_TEST_RESULT_FAILED" 0 "VC_SELF_TEST_RESULT_INVALID" ;
VAL_ 1119 VCBATT1_dualPowerLoadsSelfTestSt 4 "VC_SELF_TEST_STATE_SNA" 3 "VC_SELF_TEST_STATE_NEW_RESULT" 2 "VC_SELF_TEST_STATE_RUNNING" 1 "VC_SELF_TEST_STATE_PENDING" 0 "VC_SELF_TEST_STATE_IDLE" ;
VAL_ 1119 VCBATT1_vcbattBridgeEFuseASICSel 2 "VC_SELF_TEST_RESULT_PASSED" 1 "VC_SELF_TEST_RESULT_FAILED" 0 "VC_SELF_TEST_RESULT_INVALID" ;
VAL_ 1119 VCBATT1_vcbattBridgeEFuseAS_0001 4 "VC_SELF_TEST_STATE_SNA" 3 "VC_SELF_TEST_STATE_NEW_RESULT" 2 "VC_SELF_TEST_STATE_RUNNING" 1 "VC_SELF_TEST_STATE_PENDING" 0 "VC_SELF_TEST_STATE_IDLE" ;
VAL_ 1119 VCBATT1_uvProtectionState 12 "VC_UV_STATE_DELIBERATELY_TRIPPED" 11 "VC_UV_STATE_TRIPPED" 10 "VC_UV_STATE_ARMED" 9 "VC_UV_STATE_SELF_TEST_CLEAN_UP" 8 "VC_UV_STATE_SELF_TEST_CHECK_STUCK_ON" 7 "VC_UV_STATE_SELF_TEST_CHECK_STUCK_OFF_COMPLETE" 6 "VC_UV_STATE_SELF_TEST_CHECK_STUCK_OFF" 5 "VC_UV_STATE_SELF_TEST_LOADS_GOING_DOWN_COMPLETE" 4 "VC_UV_STATE_SELF_TEST_LOADS_GOING_DOWN" 3 "VC_UV_STATE_SELF_TEST_LOADS_ON" 2 "VC_UV_STATE_SELF_TEST_TURN_ON_LOADS" 1 "VC_UV_STATE_SELF_TEST_SETUP" 0 "VC_UV_STATE_IDLE" ;
VAL_ 1119 VC_selfTestsRunningMode 4 "DISABLED" 3 "REDUCED" 2 "FACTORY_REDUCED" 1 "FACTORY_NORMAL" 0 "NORMAL" ;
VAL_ 1030 VCBATT1_eFuseDebugStatusIndex 7 "SLEEP_BYPASS" 6 "MCU_LOGIC" 5 "BRAKE_MOTOR_ECU_1" 4 "LOADSHED" 3 "AUTOPILOT_1" 2 "BAT_BRIDGE" 1 "EPAS1" 0 "VCLEFT" ;
VAL_ 1030 VCBATT1_leftControllerEFuseState 7 "SELF_TEST" 6 "SELF_TEST_PREP" 5 "FAILSAFE" 4 "LOCKED" 3 "UNLOCKED" 2 "CONFIGURATION" 1 "WAKEUP" 0 "STANDBY" ;
VAL_ 1030 VCBATT1_leftControllerEFuseManag 8 "LOCKOUT" 7 "IDLE" 6 "UNLOCKING" 5 "LOCKED_ON_BOOT" 4 "LOCKING" 3 "STANDBY" 2 "WAKEUP" 1 "OFF" 0 "RESETTING" ;
VAL_ 1030 VCBATT1_leftControllerEFuseHardS 15 "160_MV" 14 "139_3_MV" 13 "121_3_MV" 12 "105_6_MV" 11 "91_9_MV" 10 "80_MV" 9 "69_6_MV" 8 "60_6_MV" 7 "52_8_MV" 6 "45_9_MV" 5 "40_MV" 4 "34_8_MV" 3 "30_3_MV" 2 "26_4_MV" 1 "23_MV" 0 "20_MV" ;
VAL_ 1030 VCBATT1_leftControllerEFuseOCThr 31 "89_3_MV" 30 "78_8_MV" 29 "69_5_MV" 28 "61_3_MV" 27 "54_MV" 26 "50_6_MV" 25 "47_5_MV" 24 "44_5_MV" 23 "41_7_MV" 22 "39_1_MV" 21 "36_6_MV" 20 "34_3_MV" 19 "32_2_MV" 18 "30_1_MV" 17 "28_2_MV" 16 "26_5_MV" 15 "24_8_MV" 14 "23_3_MV" 13 "21_8_MV" 12 "20_4_MV" 11 "19_1_MV" 10 "17_9_MV" 9 "16_8_MV" 8 "15_8_MV" 7 "14_8_MV" 6 "13_8_MV" 5 "13_MV" 4 "11_8_MV" 3 "10_4_MV" 2 "8_7_MV" 1 "7_2_MV" 0 "6_MV" ;
VAL_ 1030 VCBATT1_leftControllerEFuseType 2 "VNF1248" 1 "VNF1048" 0 "UNKNOWN" ;
VAL_ 1030 VCBATT1_EPAS1EFuseState 7 "SELF_TEST" 6 "SELF_TEST_PREP" 5 "FAILSAFE" 4 "LOCKED" 3 "UNLOCKED" 2 "CONFIGURATION" 1 "WAKEUP" 0 "STANDBY" ;
VAL_ 1030 VCBATT1_EPAS1EFuseManagerState 8 "LOCKOUT" 7 "IDLE" 6 "UNLOCKING" 5 "LOCKED_ON_BOOT" 4 "LOCKING" 3 "STANDBY" 2 "WAKEUP" 1 "OFF" 0 "RESETTING" ;
VAL_ 1030 VCBATT1_EPAS1EFuseHardShortThres 15 "160_MV" 14 "139_3_MV" 13 "121_3_MV" 12 "105_6_MV" 11 "91_9_MV" 10 "80_MV" 9 "69_6_MV" 8 "60_6_MV" 7 "52_8_MV" 6 "45_9_MV" 5 "40_MV" 4 "34_8_MV" 3 "30_3_MV" 2 "26_4_MV" 1 "23_MV" 0 "20_MV" ;
VAL_ 1030 VCBATT1_EPAS1EFuseOCThreshold 31 "89_3_MV" 30 "78_8_MV" 29 "69_5_MV" 28 "61_3_MV" 27 "54_MV" 26 "50_6_MV" 25 "47_5_MV" 24 "44_5_MV" 23 "41_7_MV" 22 "39_1_MV" 21 "36_6_MV" 20 "34_3_MV" 19 "32_2_MV" 18 "30_1_MV" 17 "28_2_MV" 16 "26_5_MV" 15 "24_8_MV" 14 "23_3_MV" 13 "21_8_MV" 12 "20_4_MV" 11 "19_1_MV" 10 "17_9_MV" 9 "16_8_MV" 8 "15_8_MV" 7 "14_8_MV" 6 "13_8_MV" 5 "13_MV" 4 "11_8_MV" 3 "10_4_MV" 2 "8_7_MV" 1 "7_2_MV" 0 "6_MV" ;
VAL_ 1030 VCBATT1_EPAS1EFuseType 2 "VNF1248" 1 "VNF1048" 0 "UNKNOWN" ;
VAL_ 1030 VCBATT1_autopilot1EFuseState 7 "SELF_TEST" 6 "SELF_TEST_PREP" 5 "FAILSAFE" 4 "LOCKED" 3 "UNLOCKED" 2 "CONFIGURATION" 1 "WAKEUP" 0 "STANDBY" ;
VAL_ 1030 VCBATT1_autopilot1EFuseManagerSt 8 "LOCKOUT" 7 "IDLE" 6 "UNLOCKING" 5 "LOCKED_ON_BOOT" 4 "LOCKING" 3 "STANDBY" 2 "WAKEUP" 1 "OFF" 0 "RESETTING" ;
VAL_ 1030 VCBATT1_autopilot1EFuseHardShort 15 "160_MV" 14 "139_3_MV" 13 "121_3_MV" 12 "105_6_MV" 11 "91_9_MV" 10 "80_MV" 9 "69_6_MV" 8 "60_6_MV" 7 "52_8_MV" 6 "45_9_MV" 5 "40_MV" 4 "34_8_MV" 3 "30_3_MV" 2 "26_4_MV" 1 "23_MV" 0 "20_MV" ;
VAL_ 1030 VCBATT1_autopilot1EFuseOCThresho 31 "89_3_MV" 30 "78_8_MV" 29 "69_5_MV" 28 "61_3_MV" 27 "54_MV" 26 "50_6_MV" 25 "47_5_MV" 24 "44_5_MV" 23 "41_7_MV" 22 "39_1_MV" 21 "36_6_MV" 20 "34_3_MV" 19 "32_2_MV" 18 "30_1_MV" 17 "28_2_MV" 16 "26_5_MV" 15 "24_8_MV" 14 "23_3_MV" 13 "21_8_MV" 12 "20_4_MV" 11 "19_1_MV" 10 "17_9_MV" 9 "16_8_MV" 8 "15_8_MV" 7 "14_8_MV" 6 "13_8_MV" 5 "13_MV" 4 "11_8_MV" 3 "10_4_MV" 2 "8_7_MV" 1 "7_2_MV" 0 "6_MV" ;
VAL_ 1030 VCBATT1_autopilot1EFuseType 2 "VNF1248" 1 "VNF1048" 0 "UNKNOWN" ;
VAL_ 1399 VCBATT2_vehiclePowerStateDBG 16 "VEHICLE_POWER_STATE_DBG_RESET" 15 "VEHICLE_POWER_STATE_DBG_LOW_POWER_STANDBY" 14 "VEHICLE_POWER_STATE_DBG_SLEEP_SHUTDOWN" 13 "VEHICLE_POWER_STATE_DBG_GO_QUIET" 12 "VEHICLE_POWER_STATE_DBG_LV_SHUTDOWN" 11 "VEHICLE_POWER_STATE_DBG_JUMP_START" 10 "VEHICLE_POWER_STATE_DBG_LV_ON" 9 "VEHICLE_POWER_STATE_DBG_SYSTEM_CHECKS" 8 "VEHICLE_POWER_STATE_DBG_TURN_ON_LV" 7 "VEHICLE_POWER_STATE_DBG_WAIT_FOR_HIGH_POWER" 6 "VEHICLE_POWER_STATE_DBG_OTA" 5 "VEHICLE_POWER_STATE_DBG_DRIVE" 4 "VEHICLE_POWER_STATE_DBG_ACCESSORY_PLUS" 3 "VEHICLE_POWER_STATE_DBG_ACCESSORY" 2 "VEHICLE_POWER_STATE_DBG_CONDITIONING" 1 "VEHICLE_POWER_STATE_DBG_LOW_POWER_AWAKE" 0 "VEHICLE_POWER_STATE_DBG_INIT" ;
VAL_ 1399 VCBATT2_nmWakeUpReasonDBG 32 "VCBATT_WAKEUP_REASON_UNKNOWN" 24 "VCBATT_WAKEUP_REASON_LV_BATTERY_IMPEDANCE_TEST" 23 "VCBATT_WAKEUP_REASON_LV_BATTERY_CAPACITY_TEST" 22 "VCBATT_WAKEUP_REASON_PERSIST_ACC_PORT_POWER" 21 "VCBATT_WAKEUP_REASON_FRONTPRIV" 20 "VCBATT_WAKEUP_REASON_LIN_3" 19 "VCBATT_WAKEUP_REASON_HW_PROT_SELF_TESTS" 18 "VCBATT_WAKEUP_REASON_EPAS_EFUSE" 17 "VCBATT_WAKEUP_REASON_VCLEFT_EFUSE" 16 "VCBATT_WAKEUP_REASON_AUTOPILOT_EFUSE" 15 "VCBATT_WAKEUP_REASON_LVBMB" 14 "VCBATT_WAKEUP_REASON_FRUNK_EMERGENCY_RELEASE" 13 "VCBATT_WAKEUP_REASON_PARTY_BDY_CAN" 12 "VCBATT_WAKEUP_REASON_VEH_CAN" 11 "VCBATT_WAKEUP_REASON_IPC_CAN" 10 "VCBATT_WAKEUP_REASON_FRUNK_LATCH_SWITCH" 9 "VCBATT_WAKEUP_REASON_FRUNK_ACCESS_POST_MONITOR" 8 "VCBATT_WAKEUP_REASON_FRUNK_ACCESS_POST" 7 "VCBATT_WAKEUP_REASON_TRUNK_EXTERIOR_SWITCH" 6 "VCBATT_WAKEUP_REASON_LIN" 5 "VCBATT_WAKEUP_REASON_CAN" 4 "VCBATT_WAKEUP_REASON_12V_SUPPORT_REQUIRED" 3 "VCBATT_WAKEUP_REASON_HIGH_SLEEP_CURRENT" 2 "VCBATT_WAKEUP_REASON_POWER_ON_RESET" 1 "VCBATT_WAKEUP_REASON_RESET" 0 "VCBATT_WAKEUP_REASON_NONE" ;
VAL_ 1399 VCBATT2_nmKeepAwakeReasonDBG 15 "VCBATT_KEEPAWAKE_REASON_MULTIPLE" 13 "VCBATT_KEEPAWAKE_REASON_PERSIST_ACC_PORT_POWER" 12 "VCBATT_KEEPAWAKE_REASON_CLOSURE_SWITCH" 11 "VCBATT_KEEPAWAKE_REASON_HW_PROT_SELF_TESTS" 10 "VCBATT_KEEPAWAKE_REASON_HEADLAMP_CALIBRATION" 9 "VCBATT_KEEPAWAKE_REASON_CLOSURE_LATCH" 8 "VCBATT_KEEPAWAKE_REASON_FRUNK_ACCESS_POST" 7 "VCBATT_KEEPAWAKE_REASON_FRUNK_LIGHT" 6 "VCBATT_KEEPAWAKE_REASON_SLEEP_BYPASS_NOT_SUPPORTING" 5 "VCBATT_KEEPAWAKE_REASON_EXTERIOR_LIGHTS_ON" 4 "VCBATT_KEEPAWAKE_REASON_HIBERNATION_RECOVERY" 3 "VCBATT_KEEPAWAKE_REASON_LVBMS_PACK_TEMPERATURE_LOW" 2 "VCBATT_KEEPAWAKE_REASON_UDS_ACTIVE" 1 "VCBATT_KEEPAWAKE_REASON_12V_SUPPORT_REQUIRED" 0 "VCBATT_KEEPAWAKE_REASON_NONE_SNA" ;
VAL_ 1399 VCBATT2_hibernationStateDBG 5 "VC_HIBERNATION_STATE_PREP" 4 "VC_HIBERNATION_STATE_EXIT" 3 "VC_HIBERNATION_STATE_RECOVERY" 2 "VC_HIBERNATION_STATE_ACTIVE" 1 "VC_HIBERNATION_STATE_NOT_ACTIVE" 0 "VC_HIBERNATION_STATE_INIT" ;
VAL_ 945 VCBATT_LVHealthStatus 6 "POWER_SUPPLY_COMPROMISED" 5 "ENERGY_RESERVE_CRITICAL" 4 "ENERGY_RESERVE_COMPROMISED" 3 "BACKUP_COMPROMISED" 2 "LATENT_FAULT" 1 "HEALTHY_LIMITED" 0 "DOMAIN_HEALTHY" ;
VAL_ 945 VCBATT_LVStatusForDrive 6 "STATUS_FOR_DRIVE_ACTIVE_DECEL" 5 "STATUS_FOR_DRIVE_PULL_TO_SHOULDER" 4 "STATUS_FOR_DRIVE_LIMP" 3 "STATUS_FOR_DRIVE_RETURN_TO_SERVICE" 2 "STATUS_FOR_DRIVE_READY_LIMITED" 1 "STATUS_FOR_DRIVE_READY" 0 "STATUS_FOR_DRIVE_NOT_READY" ;
VAL_ 945 VCBATT_LVPowerSecondsToSafeHarbo 65535 "INDEFINITE" ;
VAL_ 945 VCBATT_autonomyBehavior 2 "DRIVERLESS_NO_TAKEOVER" 1 "DRIVERLESS_TAKEOVER" 0 "DRIVER" ;
VAL_ 945 VCBATT_12vStatusForDrive 2 "EXIT_DRIVE_REQUESTED_12V" 1 "READY_FOR_DRIVE_12V" 0 "NOT_READY_FOR_DRIVE_12V" ;
VAL_ 1090 VCBATT_pcsInterfaceMuxIndex 1 "1" 0 "0" ;
VAL_ 1090 VCBATT_pcsResistanceFiltered 65535 "SNA" ;
VAL_ 1027 VCFRONT1_eFuseDebugStatusIndex 5 "BRIDGE" 4 "BRAKE_MOTOR_ECU_2" 3 "AUTOPILOT_2" 2 "PCS" 1 "RIGHT_CONTROLLER" 0 "EPAS2" ;
VAL_ 1027 VCFRONT1_EPAS2EFuseState 7 "SELF_TEST" 6 "SELF_TEST_PREP" 5 "FAILSAFE" 4 "LOCKED" 3 "UNLOCKED" 2 "CONFIGURATION" 1 "WAKEUP" 0 "STANDBY" ;
VAL_ 1027 VCFRONT1_EPAS2EFuseManagerState 8 "LOCKOUT" 7 "IDLE" 6 "UNLOCKING" 5 "LOCKED_ON_BOOT" 4 "LOCKING" 3 "STANDBY" 2 "WAKEUP" 1 "OFF" 0 "RESETTING" ;
VAL_ 1027 VCFRONT1_EPAS2EFuseHardShortThre 15 "160_MV" 14 "139_3_MV" 13 "121_3_MV" 12 "105_6_MV" 11 "91_9_MV" 10 "80_MV" 9 "69_6_MV" 8 "60_6_MV" 7 "52_8_MV" 6 "45_9_MV" 5 "40_MV" 4 "34_8_MV" 3 "30_3_MV" 2 "26_4_MV" 1 "23_MV" 0 "20_MV" ;
VAL_ 1027 VCFRONT1_EPAS2EFuseOCThreshold 31 "89_3_MV" 30 "78_8_MV" 29 "69_5_MV" 28 "61_3_MV" 27 "54_MV" 26 "50_6_MV" 25 "47_5_MV" 24 "44_5_MV" 23 "41_7_MV" 22 "39_1_MV" 21 "36_6_MV" 20 "34_3_MV" 19 "32_2_MV" 18 "30_1_MV" 17 "28_2_MV" 16 "26_5_MV" 15 "24_8_MV" 14 "23_3_MV" 13 "21_8_MV" 12 "20_4_MV" 11 "19_1_MV" 10 "17_9_MV" 9 "16_8_MV" 8 "15_8_MV" 7 "14_8_MV" 6 "13_8_MV" 5 "13_MV" 4 "11_8_MV" 3 "10_4_MV" 2 "8_7_MV" 1 "7_2_MV" 0 "6_MV" ;
VAL_ 1027 VCFRONT1_EPAS2EFuseType 2 "VNF1248" 1 "VNF1048" 0 "UNKNOWN" ;
VAL_ 1027 VCFRONT1_rightControllerEFuseSta 7 "SELF_TEST" 6 "SELF_TEST_PREP" 5 "FAILSAFE" 4 "LOCKED" 3 "UNLOCKED" 2 "CONFIGURATION" 1 "WAKEUP" 0 "STANDBY" ;
VAL_ 1027 VCFRONT1_rightControllerEFuseMan 8 "LOCKOUT" 7 "IDLE" 6 "UNLOCKING" 5 "LOCKED_ON_BOOT" 4 "LOCKING" 3 "STANDBY" 2 "WAKEUP" 1 "OFF" 0 "RESETTING" ;
VAL_ 1027 VCFRONT1_rightControllerEFuseHar 15 "160_MV" 14 "139_3_MV" 13 "121_3_MV" 12 "105_6_MV" 11 "91_9_MV" 10 "80_MV" 9 "69_6_MV" 8 "60_6_MV" 7 "52_8_MV" 6 "45_9_MV" 5 "40_MV" 4 "34_8_MV" 3 "30_3_MV" 2 "26_4_MV" 1 "23_MV" 0 "20_MV" ;
VAL_ 1027 VCFRONT1_rightControllerEFuseOCT 31 "89_3_MV" 30 "78_8_MV" 29 "69_5_MV" 28 "61_3_MV" 27 "54_MV" 26 "50_6_MV" 25 "47_5_MV" 24 "44_5_MV" 23 "41_7_MV" 22 "39_1_MV" 21 "36_6_MV" 20 "34_3_MV" 19 "32_2_MV" 18 "30_1_MV" 17 "28_2_MV" 16 "26_5_MV" 15 "24_8_MV" 14 "23_3_MV" 13 "21_8_MV" 12 "20_4_MV" 11 "19_1_MV" 10 "17_9_MV" 9 "16_8_MV" 8 "15_8_MV" 7 "14_8_MV" 6 "13_8_MV" 5 "13_MV" 4 "11_8_MV" 3 "10_4_MV" 2 "8_7_MV" 1 "7_2_MV" 0 "6_MV" ;
VAL_ 1027 VCFRONT1_rightControllerEFuseTyp 2 "VNF1248" 1 "VNF1048" 0 "UNKNOWN" ;
VAL_ 1027 VCFRONT1_autopilot2EFuseState 7 "SELF_TEST" 6 "SELF_TEST_PREP" 5 "FAILSAFE" 4 "LOCKED" 3 "UNLOCKED" 2 "CONFIGURATION" 1 "WAKEUP" 0 "STANDBY" ;
VAL_ 1027 VCFRONT1_autopilot2EFuseManagerS 8 "LOCKOUT" 7 "IDLE" 6 "UNLOCKING" 5 "LOCKED_ON_BOOT" 4 "LOCKING" 3 "STANDBY" 2 "WAKEUP" 1 "OFF" 0 "RESETTING" ;
VAL_ 1027 VCFRONT1_autopilot2EFuseHardShor 15 "160_MV" 14 "139_3_MV" 13 "121_3_MV" 12 "105_6_MV" 11 "91_9_MV" 10 "80_MV" 9 "69_6_MV" 8 "60_6_MV" 7 "52_8_MV" 6 "45_9_MV" 5 "40_MV" 4 "34_8_MV" 3 "30_3_MV" 2 "26_4_MV" 1 "23_MV" 0 "20_MV" ;
VAL_ 1027 VCFRONT1_autopilot2EFuseOCThresh 31 "89_3_MV" 30 "78_8_MV" 29 "69_5_MV" 28 "61_3_MV" 27 "54_MV" 26 "50_6_MV" 25 "47_5_MV" 24 "44_5_MV" 23 "41_7_MV" 22 "39_1_MV" 21 "36_6_MV" 20 "34_3_MV" 19 "32_2_MV" 18 "30_1_MV" 17 "28_2_MV" 16 "26_5_MV" 15 "24_8_MV" 14 "23_3_MV" 13 "21_8_MV" 12 "20_4_MV" 11 "19_1_MV" 10 "17_9_MV" 9 "16_8_MV" 8 "15_8_MV" 7 "14_8_MV" 6 "13_8_MV" 5 "13_MV" 4 "11_8_MV" 3 "10_4_MV" 2 "8_7_MV" 1 "7_2_MV" 0 "6_MV" ;
VAL_ 1027 VCFRONT1_autopilot2EFuseType 2 "VNF1248" 1 "VNF1048" 0 "UNKNOWN" ;
VAL_ 609 VCFRONT_12VBatteryStatusIndex 5 "Mux5" 4 "Mux4" 3 "Mux3" 2 "Mux2" 1 "Mux1" 0 "Mux0" ;
VAL_ 609 VCFRONT_batterySMState 10 "BATTERY_SM_STATE_EXTERNAL_LV_BUS_CONTROL" 9 "BATTERY_SM_STATE_RECOVERY" 8 "BATTERY_SM_STATE_FAULT" 7 "BATTERY_SM_STATE_SHORTED_CELL_TEST" 6 "BATTERY_SM_STATE_DISCONNECTED_BATTERY_TEST" 5 "BATTERY_SM_STATE_OTA_STANDBY" 4 "BATTERY_SM_STATE_RESISTANCE_ESTIMATION" 3 "BATTERY_SM_STATE_STANDBY" 2 "BATTERY_SM_STATE_DISCHARGE" 1 "BATTERY_SM_STATE_CHARGE" 0 "BATTERY_SM_STATE_INIT" ;
VAL_ 609 VCFRONT_eFuseRecoveryStateDBG 4 "VC_LVBMB_EFUSE_RECOVERY_STATE_BLOCKED" 3 "VC_LVBMB_EFUSE_RECOVERY_STATE_FINISH" 2 "VC_LVBMB_EFUSE_RECOVERY_STATE_CONNECT" 1 "VC_LVBMB_EFUSE_RECOVERY_STATE_SETUP" 0 "VC_LVBMB_EFUSE_RECOVERY_STATE_INACTIVE" ;
VAL_ 609 VCFRONT_batteryLINScheduleDBG 7 "VC_LVBMS_LIN_SCHEDULE_SNA" 6 "VC_LVBMS_LIN_SCHEDULE_OTHER" 4 "VC_LVBMS_LIN_SCHEDULE_DEFAULT_2" 3 "VC_LVBMS_LIN_SCHEDULE_DEFAULT_1" 2 "VC_LVBMS_LIN_SCHEDULE_DIAGNOSTIC" 1 "VC_LVBMS_LIN_SCHEDULE_RESET" 0 "VC_LVBMS_LIN_SCHEDULE_OFF" ;
VAL_ 609 VCFRONT_IBSVoltage 4095 "SNA" ;
VAL_ 609 VCFRONT_IBSTemperature 2047 "IBS_TEMPERATURE_SNA" ;
VAL_ 609 VCFRONT_LVBatteryStatusForDrive 2 "LV_BATTERY_EXIT_DRIVE_REQUESTED" 1 "LV_BATTERY_READY_FOR_DRIVE" 0 "LV_BATTERY_NOT_READY_FOR_DRIVE" ;
VAL_ 609 VCFRONT_LVBatteryType 5 "LV_BATTERY_TYPE_TESLA_48V_LI_ION" 4 "LV_BATTERY_TYPE_TESLA_16V_LI_ION" 3 "LV_BATTERY_TYPE_CATL_LI_ION" 2 "LV_BATTERY_TYPE_CLARIOS_B24_FLOODED" 1 "LV_BATTERY_TYPE_ATLASBX_B24_FLOODED" 0 "LV_BATTERY_TYPE_UNKNOWN" ;
VAL_ 609 VCFRONT_IBSVoltageFiltered 16383 "SNA" 16382 "MAX" 16381 "MIN" ;
VAL_ 609 VCFRONT_LVBMS_LVBusVoltageSource 3 "VC_LVBMS_VOLTAGE_SOURCE_LVBMS" 2 "VC_LVBMS_VOLTAGE_SOURCE_VBAT_MONITOR" 1 "VC_LVBMS_VOLTAGE_SOURCE_IBS" 0 "VC_LVBMS_VOLTAGE_SOURCE_NONE" ;
VAL_ 609 VCFRONT_LVBMS_LVPackCurrentSourc 2 "VC_LV_PACK_CURRENT_SOURCE_LVBMS" 1 "VC_LV_PACK_CURRENT_SOURCE_IBS" 0 "VC_LV_PACK_CURRENT_SOURCE_NONE" ;
VAL_ 609 VCFRONT_LVBatterySupportRqrdTrig 14336 "LV_BATTERY_SUPPORT_REQUIRED_TRIGGER_SOC_IMBALANCE_AND_CORRECTION" 12288 "LV_BATTERY_SUPPORT_REQUIRED_TRIGGER_IMBALANCE_AND_CORRECTION" 10240 "LV_BATTERY_SUPPORT_REQUIRED_TRIGGER_SOC_AND_CORRECTION" 8192 "LV_BATTERY_SUPPORT_REQUIRED_TRIGGER_CORRECTION" 6144 "LV_BATTERY_SUPPORT_REQUIRED_TRIGGER_SOC_AND_IMBALANCE" 4096 "LV_BATTERY_SUPPORT_REQUIRED_TRIGGER_IMBALANCE" 2048 "LV_BATTERY_SUPPORT_REQUIRED_TRIGGER_SOC" 1024 "LV_BATTERY_SUPPORT_REQUIRED_TRIGGER_POST_OTA" 512 "LV_BATTERY_SUPPORT_REQUIRED_TRIGGER_EXIT_TRANSPORT_MODE" 256 "LV_BATTERY_SUPPORT_REQUIRED_TRIGGER_POWER_ON_RESET" 128 "LV_BATTERY_SUPPORT_REQUIRED_TRIGGER_PERIODIC_CHARGE" 64 "LV_BATTERY_SUPPORT_REQUIRED_TRIGGER_AH_COUNT" 32 "LV_BATTERY_SUPPORT_REQUIRED_TRIGGER_UNKNOWN_VOLTAGE" 20 "LV_BATTERY_SUPPORT_REQUIRED_TRIGGER_RAW_VC_VOLTAGES" 16 "LV_BATTERY_SUPPORT_REQUIRED_TRIGGER_VBAT_RAW_VOLTAGE" 12 "LV_BATTERY_SUPPORT_REQUIRED_TRIGGER_RAW_BATTERY_VOLTAGES" 10 "LV_BATTERY_SUPPORT_REQUIRED_TRIGGER_PACK_VOLTAGES" 8 "LV_BATTERY_SUPPORT_REQUIRED_TRIGGER_PACK_RAW_VOLTAGE" 5 "LV_BATTERY_SUPPORT_REQUIRED_TRIGGER_IBS_VOLTAGES" 4 "LV_BATTERY_SUPPORT_REQUIRED_TRIGGER_IBS_RAW_VOLTAGE" 3 "LV_BATTERY_SUPPORT_REQUIRED_TRIGGER_FILTERED_VOLTAGES" 2 "LV_BATTERY_SUPPORT_REQUIRED_TRIGGER_PACK_FILTERED_VOLTAGE" 1 "LV_BATTERY_SUPPORT_REQUIRED_TRIGGER_IBS_FILTERED_VOLTAGE" 0 "LV_BATTERY_SUPPORT_REQUIRED_TRIGGER_NONE" ;
VAL_ 609 VCFRONT_voltageProfile 3 "VOLTAGE_PROFILE_ALWAYS_CLOSED_CONTACTORS" 2 "VOLTAGE_PROFILE_REDUCED_FLOAT" 1 "VOLTAGE_PROFILE_FLOAT" 0 "VOLTAGE_PROFILE_CHARGE" ;
VAL_ 609 VCFRONT_IBSVoltageRawDBG 16383 "SNA" 16382 "MAX" 16381 "MIN" ;
VAL_ 609 VCFRONT_LVBusControlMode 15 "MODE_RESERVED" 9 "JUMP_POST" 8 "DISCONNECTED_BATTERY_TEST" 7 "LVBMB_EFUSE_RECOVERY" 6 "BATTERY_IMPEDANCE_TEST" 5 "LVBMB_EFUSE_TEST" 4 "BATTERY_CAPACITY_TEST" 3 "BRIDGE_MANAGER" 2 "BLOCK_LV_BATT_CHARGING" 1 "HW_PROT_SELF_TESTS" 0 "LV_BUS_IDLE" ;
VAL_ 1847 VCFRONT_LVBMS_InfoIndex 5 "INVALID" 4 "SERIAL_NUMBER" 3 "BUILDTYPE" 2 "GITHASH" 1 "APP_USAGEID_CRC" 0 "PCBAID_ASSYID" ;
VAL_ 1847 VCFRONT_LVBMS_SubUsageId 65535 "SNA" ;
VAL_ 1847 VCFRONT_LVBMS_FWBuildType 4 "INFO_MFG_BUILD" 3 "INFO_TRACEABLE_CI_BUILD" 2 "INFO_LOCAL_BUILD" 1 "INFO_PLATFORM_BUILD" 0 "INFO_UNKNOWN_BUILD" ;
VAL_ 1140 VCFRONT_LVHealthStatus 6 "POWER_SUPPLY_COMPROMISED" 5 "ENERGY_RESERVE_CRITICAL" 4 "ENERGY_RESERVE_COMPROMISED" 3 "BACKUP_COMPROMISED" 2 "LATENT_FAULT" 1 "HEALTHY_LIMITED" 0 "DOMAIN_HEALTHY" ;
VAL_ 1140 VCFRONT_LVStatusForDrive 6 "STATUS_FOR_DRIVE_ACTIVE_DECEL" 5 "STATUS_FOR_DRIVE_PULL_TO_SHOULDER" 4 "STATUS_FOR_DRIVE_LIMP" 3 "STATUS_FOR_DRIVE_RETURN_TO_SERVICE" 2 "STATUS_FOR_DRIVE_READY_LIMITED" 1 "STATUS_FOR_DRIVE_READY" 0 "STATUS_FOR_DRIVE_NOT_READY" ;
VAL_ 1140 VCFRONT_LVPowerSecondsToSafeHarb 65535 "INDEFINITE" ;
VAL_ 1140 VCFRONT_lockoutStrategy 1 "PARK_STATUS" 0 "POWER_STATE" ;
VAL_ 1173 VCFRONT_LVHealthDebugIndex 1 "FRONT_CHECK_RESULTS_1" 0 "UNHEALTHY_REASONS" ;
VAL_ 545 VCFRONT_LVPowerStateIndex 1 "Mux1" 0 "Mux0" ;
VAL_ 545 VCFRONT_vehiclePowerState 3 "VEHICLE_POWER_STATE_DRIVE" 2 "VEHICLE_POWER_STATE_ACCESSORY" 1 "VEHICLE_POWER_STATE_CONDITIONING" 0 "VEHICLE_POWER_STATE_OFF" ;
VAL_ 545 VCFRONT_cpLVRequest 3 "LV_FAULT" 2 "LV_GOING_DOWN" 1 "LV_ON" 0 "LV_OFF" ;
VAL_ 545 VCFRONT_epasLVState 3 "LV_FAULT" 2 "LV_GOING_DOWN" 1 "LV_ON" 0 "LV_OFF" ;
VAL_ 545 VCFRONT_hvcLVRequest 3 "LV_FAULT" 2 "LV_GOING_DOWN" 1 "LV_ON" 0 "LV_OFF" ;
VAL_ 545 VCFRONT_tasLVState 3 "LV_FAULT" 2 "LV_GOING_DOWN" 1 "LV_ON" 0 "LV_OFF" ;
VAL_ 545 VCFRONT_pcsLVState 3 "LV_FAULT" 2 "LV_GOING_DOWN" 1 "LV_ON" 0 "LV_OFF" ;
VAL_ 545 VCFRONT_CMPDLVState 3 "LV_FAULT" 2 "LV_GOING_DOWN" 1 "LV_ON" 0 "LV_OFF" ;
VAL_ 545 VCFRONT_hcmlLVState 3 "LV_FAULT" 2 "LV_GOING_DOWN" 1 "LV_ON" 0 "LV_OFF" ;
VAL_ 545 VCFRONT_hcmrLVState 3 "LV_FAULT" 2 "LV_GOING_DOWN" 1 "LV_ON" 0 "LV_OFF" ;
VAL_ 545 VCFRONT_MCUAudioLVState 3 "LV_FAULT" 2 "LV_GOING_DOWN" 1 "LV_ON" 0 "LV_OFF" ;
VAL_ 545 VCFRONT_espValveLVState 3 "LV_FAULT" 2 "LV_GOING_DOWN" 1 "LV_ON" 0 "LV_OFF" ;
VAL_ 545 VCFRONT_MCUGraphicsLVState 3 "LV_FAULT" 2 "LV_GOING_DOWN" 1 "LV_ON" 0 "LV_OFF" ;
VAL_ 545 VC_hvStateRequest 7 "VC_HV_REQUEST_STATE_RESERVED" 2 "VC_HV_REQUEST_STATE_HV_UP" 1 "VC_HV_REQUEST_STATE_LV_SUPPORT_ONLY" 0 "VC_HV_REQUEST_STATE_NONE" ;
VAL_ 545 VC_autonomyBehavior 2 "DRIVERLESS_NO_TAKEOVER" 1 "DRIVERLESS_TAKEOVER" 0 "DRIVER" ;
VAL_ 545 VC_persistAccPortPowerState 4 "STATE_KEEP_AWAKE_OVERRIDDEN_NOTIFY_USER" 3 "STATE_KEEP_AWAKE_ALLOW_SLEEP" 2 "STATE_KEEP_AWAKE_ACTIVE" 1 "STATE_KEEP_AWAKE_ARMED" 0 "STATE_KEEP_AWAKE_DISARMED" ;
VAL_ 700 VCFRONT_LVThermalMotorsIndex 12 "END" 11 "COOLANT_FLOW_DIAGNOSTICS" 10 "WINDMILL_1" 9 "WINDMILL_0" 8 "PUMP_BATT_2" 7 "PUMP_BATT_1" 6 "PUMP_BATT_0" 5 "PUMP_PT_2" 4 "PUMP_PT_1" 3 "PUMP_PT_0" 2 "RAD_FAN_2" 1 "RAD_FAN_1" 0 "RAD_FAN_0" ;
VAL_ 700 VCFRONT_radiatorFanState 7 "VC_mlxControllerState_MIA" 6 "VC_mlxControllerState_FAULTED" 5 "VC_mlxControllerState_UV_TEST" 4 "VC_mlxControllerState_SELF_TEST" 3 "VC_mlxControllerState_STANDBY" 2 "VC_mlxControllerState_COLD_STARTUP" 1 "VC_mlxControllerState_ENABLE" 0 "VC_mlxControllerState_IDLE" ;
VAL_ 700 VCFRONT_radiatorFanTorque 1023 "SNA" ;
VAL_ 700 VCFRONT_radiatorFanIDc 127 "SNA" ;
VAL_ 700 VCFRONT_mlxLINCurrentSchedule 2 "DIAGNOSTIC" 1 "NORMAL" 0 "OFF" ;
VAL_ 700 VCFRONT_pumpPowertrainState 7 "VC_mlxControllerState_MIA" 6 "VC_mlxControllerState_FAULTED" 5 "VC_mlxControllerState_UV_TEST" 4 "VC_mlxControllerState_SELF_TEST" 3 "VC_mlxControllerState_STANDBY" 2 "VC_mlxControllerState_COLD_STARTUP" 1 "VC_mlxControllerState_ENABLE" 0 "VC_mlxControllerState_IDLE" ;
VAL_ 700 VCFRONT_pumpPowertrainTorque 1023 "SNA" ;
VAL_ 700 VCFRONT_pumpPowertrainIDc 127 "SNA" ;
VAL_ 700 VCFRONT_pumpBatteryState 7 "VC_mlxControllerState_MIA" 6 "VC_mlxControllerState_FAULTED" 5 "VC_mlxControllerState_UV_TEST" 4 "VC_mlxControllerState_SELF_TEST" 3 "VC_mlxControllerState_STANDBY" 2 "VC_mlxControllerState_COLD_STARTUP" 1 "VC_mlxControllerState_ENABLE" 0 "VC_mlxControllerState_IDLE" ;
VAL_ 700 VCFRONT_pumpBatteryTorque 1023 "SNA" ;
VAL_ 700 VCFRONT_pumpBatteryIDc 127 "SNA" ;
VAL_ 577 VCFRONT_coolantFlowBatReason 21 "AP_AIR_PURGE" 20 "DRIVERLESS_SELF_TEST" 19 "BATTERY_DISCHARGE_FLOW_REQ" 18 "DI_BURN_IN_FLOW_REQ" 17 "UI_FLOW_REQ" 16 "DI_PPR_FLOW_REQ" 15 "BMS_PPR_FLOW_REQ" 14 "HP_FLOW_REQ" 13 "DIS_FLOW_REQ" 12 "DI_FLOW_REQ" 11 "PCS_FLOW_REQ" 10 "PASSIVE_MANAGER_PT" 9 "ACTIVE_MANAGER_PT" 8 "OVERRIDE_PT" 7 "DAS_FLOW_REQ" 6 "BMS_FLOW_REQ" 5 "PASSIVE_MANAGER_BATT" 4 "ACTIVE_MANAGER_BATT" 3 "OVERRIDE_BATT" 2 "NO_FLOW_REQ" 1 "COOLANT_AIR_PURGE" 0 "NONE" ;
VAL_ 577 VCFRONT_coolantFlowPTReason 21 "AP_AIR_PURGE" 20 "DRIVERLESS_SELF_TEST" 19 "BATTERY_DISCHARGE_FLOW_REQ" 18 "DI_BURN_IN_FLOW_REQ" 17 "UI_FLOW_REQ" 16 "DI_PPR_FLOW_REQ" 15 "BMS_PPR_FLOW_REQ" 14 "HP_FLOW_REQ" 13 "DIS_FLOW_REQ" 12 "DI_FLOW_REQ" 11 "PCS_FLOW_REQ" 10 "PASSIVE_MANAGER_PT" 9 "ACTIVE_MANAGER_PT" 8 "OVERRIDE_PT" 7 "DAS_FLOW_REQ" 6 "BMS_FLOW_REQ" 5 "PASSIVE_MANAGER_BATT" 4 "ACTIVE_MANAGER_BATT" 3 "OVERRIDE_BATT" 2 "NO_FLOW_REQ" 1 "COOLANT_AIR_PURGE" 0 "NONE" ;
VAL_ 577 VCFRONT_wasteHeatRequestType 3 "WASTE_TYPE_BURN_IN" 2 "WASTE_TYPE_FULL" 1 "WASTE_TYPE_PARTIAL" 0 "WASTE_TYPE_NONE" ;
VAL_ 577 VCFRONT_coolantAirPurgeBatState 4 "AIR_PURGE_STATE_PENDING" 3 "AIR_PURGE_STATE_INTERRUPTED" 2 "AIR_PURGE_STATE_COMPLETE" 1 "AIR_PURGE_STATE_ACTIVE" 0 "AIR_PURGE_STATE_INACTIVE" ;
VAL_ 577 VCFRONT_coolantFlowTableConfig 1 "FLOW_TABLE_CONFIG_BMS_TYPE_5" 0 "FLOW_TABLE_CONFIG_DEFAULT" ;
VAL_ 753 VCFRONT_eFuseDebugStatusIndex 19 "INVALID" 18 "MCU_MISC" 17 "LV_BATTERY_DEBUG" 16 "MISC_RAILS" 15 "RAILS_A_B" 14 "PUMPS" 13 "VBAT_FUSED_HIGH_CURRENT" 12 "HEADLAMPS" 11 "MCU_LOGIC" 10 "SLEEP_BYPASS" 9 "AUTOPILOT_2" 8 "AUTOPILOT_1" 7 "ESP_VALVE" 6 "ESP_MOTOR" 5 "EPAS3S" 4 "EPAS3P" 3 "IBOOSTER" 2 "PCS" 1 "VCLEFT" 0 "VCRIGHT" ;
VAL_ 753 VCFRONT_leftControllerState 3 "EFUSE_STATE_SNA" 2 "EFUSE_STATE_LOCKED_OUT" 1 "EFUSE_STATE_ON" 0 "EFUSE_STATE_OFF" ;
VAL_ 753 VCFRONT_vcleftSelfTestResult 12 "EFUSE_SELF_TEST_EFUSE_RESULT_SNA" 11 "EFUSE_SELF_TEST_EFUSE_RESULT_SKIPPED" 10 "EFUSE_SELF_TEST_EFUSE_RESULT_FAILED_NOT_LATCHED" 9 "EFUSE_SELF_TEST_EFUSE_RESULT_FAILED_TURN_OFF_PATH_TOO_SLOW" 8 "EFUSE_SELF_TEST_EFUSE_RESULT_FAILED_ENABLE_HIGH_MALFUNCTION" 7 "EFUSE_SELF_TEST_EFUSE_RESULT_FAILED_POWER_FET_CHANNEL_OPEN" 6 "EFUSE_SELF_TEST_EFUSE_RESULT_FAILED_ENABLE_LOW_MALFUNCTION" 5 "EFUSE_SELF_TEST_EFUSE_RESULT_FAILED_POWER_FET_STUCK_ON" 4 "EFUSE_SELF_TEST_EFUSE_RESULT_FAILED_EFUSE_OUTPUT_SHORT" 3 "EFUSE_SELF_TEST_EFUSE_RESULT_FAILED_RAILS_UNSTABLE" 2 "EFUSE_SELF_TEST_EFUSE_RESULT_PASSED" 1 "EFUSE_SELF_TEST_EFUSE_RESULT_RUNNING" 0 "EFUSE_SELF_TEST_EFUSE_RESULT_NOT_RUN" ;
VAL_ 753 VCFRONT_leftControllerEFuseVNFSt 7 "EFUSE_ASIC_STATE_SELF_TEST" 6 "EFUSE_ASIC_STATE_SELF_TEST_PREP" 5 "EFUSE_ASIC_STATE_LOCKED" 4 "EFUSE_ASIC_STATE_UNLOCKED" 3 "EFUSE_ASIC_STATE_CONFIGURATION" 2 "EFUSE_ASIC_STATE_WAKEUP" 1 "EFUSE_ASIC_STATE_STANDBY" 0 "EFUSE_ASIC_STATE_UNKNOWN" ;
VAL_ 753 VCFRONT_leftControllerEFuseVNFSe 3 "EFUSE_SELF_TEST_SKIPPED" 2 "EFUSE_SELF_TEST_COMPLETE" 1 "EFUSE_SELF_TEST_ACTIVE" 0 "EFUSE_SELF_TEST_NOT_COMPLETE" ;
VAL_ 753 VCFRONT_PCSState 3 "EFUSE_STATE_SNA" 2 "EFUSE_STATE_LOCKED_OUT" 1 "EFUSE_STATE_ON" 0 "EFUSE_STATE_OFF" ;
VAL_ 753 VCFRONT_pcsSelfTestResult 12 "EFUSE_SELF_TEST_EFUSE_RESULT_SNA" 11 "EFUSE_SELF_TEST_EFUSE_RESULT_SKIPPED" 10 "EFUSE_SELF_TEST_EFUSE_RESULT_FAILED_NOT_LATCHED" 9 "EFUSE_SELF_TEST_EFUSE_RESULT_FAILED_TURN_OFF_PATH_TOO_SLOW" 8 "EFUSE_SELF_TEST_EFUSE_RESULT_FAILED_ENABLE_HIGH_MALFUNCTION" 7 "EFUSE_SELF_TEST_EFUSE_RESULT_FAILED_POWER_FET_CHANNEL_OPEN" 6 "EFUSE_SELF_TEST_EFUSE_RESULT_FAILED_ENABLE_LOW_MALFUNCTION" 5 "EFUSE_SELF_TEST_EFUSE_RESULT_FAILED_POWER_FET_STUCK_ON" 4 "EFUSE_SELF_TEST_EFUSE_RESULT_FAILED_EFUSE_OUTPUT_SHORT" 3 "EFUSE_SELF_TEST_EFUSE_RESULT_FAILED_RAILS_UNSTABLE" 2 "EFUSE_SELF_TEST_EFUSE_RESULT_PASSED" 1 "EFUSE_SELF_TEST_EFUSE_RESULT_RUNNING" 0 "EFUSE_SELF_TEST_EFUSE_RESULT_NOT_RUN" ;
VAL_ 753 VCFRONT_PCSEFuseVNFState 7 "EFUSE_ASIC_STATE_SELF_TEST" 6 "EFUSE_ASIC_STATE_SELF_TEST_PREP" 5 "EFUSE_ASIC_STATE_LOCKED" 4 "EFUSE_ASIC_STATE_UNLOCKED" 3 "EFUSE_ASIC_STATE_CONFIGURATION" 2 "EFUSE_ASIC_STATE_WAKEUP" 1 "EFUSE_ASIC_STATE_STANDBY" 0 "EFUSE_ASIC_STATE_UNKNOWN" ;
VAL_ 753 VCFRONT_PCSEFuseVNFSelfTestStatu 3 "EFUSE_SELF_TEST_SKIPPED" 2 "EFUSE_SELF_TEST_COMPLETE" 1 "EFUSE_SELF_TEST_ACTIVE" 0 "EFUSE_SELF_TEST_NOT_COMPLETE" ;
VAL_ 753 VCFRONT_iBoosterState 3 "EFUSE_STATE_SNA" 2 "EFUSE_STATE_LOCKED_OUT" 1 "EFUSE_STATE_ON" 0 "EFUSE_STATE_OFF" ;
VAL_ 753 VCFRONT_iBoosterSelfTestResult 12 "EFUSE_SELF_TEST_EFUSE_RESULT_SNA" 11 "EFUSE_SELF_TEST_EFUSE_RESULT_SKIPPED" 10 "EFUSE_SELF_TEST_EFUSE_RESULT_FAILED_NOT_LATCHED" 9 "EFUSE_SELF_TEST_EFUSE_RESULT_FAILED_TURN_OFF_PATH_TOO_SLOW" 8 "EFUSE_SELF_TEST_EFUSE_RESULT_FAILED_ENABLE_HIGH_MALFUNCTION" 7 "EFUSE_SELF_TEST_EFUSE_RESULT_FAILED_POWER_FET_CHANNEL_OPEN" 6 "EFUSE_SELF_TEST_EFUSE_RESULT_FAILED_ENABLE_LOW_MALFUNCTION" 5 "EFUSE_SELF_TEST_EFUSE_RESULT_FAILED_POWER_FET_STUCK_ON" 4 "EFUSE_SELF_TEST_EFUSE_RESULT_FAILED_EFUSE_OUTPUT_SHORT" 3 "EFUSE_SELF_TEST_EFUSE_RESULT_FAILED_RAILS_UNSTABLE" 2 "EFUSE_SELF_TEST_EFUSE_RESULT_PASSED" 1 "EFUSE_SELF_TEST_EFUSE_RESULT_RUNNING" 0 "EFUSE_SELF_TEST_EFUSE_RESULT_NOT_RUN" ;
VAL_ 753 VCFRONT_iBoosterEFuseVNFState 7 "EFUSE_ASIC_STATE_SELF_TEST" 6 "EFUSE_ASIC_STATE_SELF_TEST_PREP" 5 "EFUSE_ASIC_STATE_LOCKED" 4 "EFUSE_ASIC_STATE_UNLOCKED" 3 "EFUSE_ASIC_STATE_CONFIGURATION" 2 "EFUSE_ASIC_STATE_WAKEUP" 1 "EFUSE_ASIC_STATE_STANDBY" 0 "EFUSE_ASIC_STATE_UNKNOWN" ;
VAL_ 753 VCFRONT_iBoosterHardshortThresho 15 "VNF1048_HSHT_160_MV" 14 "VNF1048_HSHT_139_3_MV" 13 "VNF1048_HSHT_121_3_MV" 12 "VNF1048_HSHT_105_6_MV" 11 "VNF1048_HSHT_91_9_MV" 10 "VNF1048_HSHT_80_MV" 9 "VNF1048_HSHT_69_6_MV" 8 "VNF1048_HSHT_60_6_MV" 7 "VNF1048_HSHT_52_8_MV" 6 "VNF1048_HSHT_45_9_MV" 5 "VNF1048_HSHT_40_MV" 4 "VNF1048_HSHT_34_8_MV" 3 "VNF1048_HSHT_30_3_MV" 2 "VNF1048_HSHT_26_4_MV" 1 "VNF1048_HSHT_23_MV" 0 "VNF1048_HSHT_20_MV" ;
VAL_ 753 VCFRONT_iBoosterEFuseVNFSelfTest 3 "EFUSE_SELF_TEST_SKIPPED" 2 "EFUSE_SELF_TEST_COMPLETE" 1 "EFUSE_SELF_TEST_ACTIVE" 0 "EFUSE_SELF_TEST_NOT_COMPLETE" ;
VAL_ 753 VCFRONT_EPAS3PState 3 "EFUSE_STATE_SNA" 2 "EFUSE_STATE_LOCKED_OUT" 1 "EFUSE_STATE_ON" 0 "EFUSE_STATE_OFF" ;
VAL_ 753 VCFRONT_EPAS3PSelfTestResult 12 "EFUSE_SELF_TEST_EFUSE_RESULT_SNA" 11 "EFUSE_SELF_TEST_EFUSE_RESULT_SKIPPED" 10 "EFUSE_SELF_TEST_EFUSE_RESULT_FAILED_NOT_LATCHED" 9 "EFUSE_SELF_TEST_EFUSE_RESULT_FAILED_TURN_OFF_PATH_TOO_SLOW" 8 "EFUSE_SELF_TEST_EFUSE_RESULT_FAILED_ENABLE_HIGH_MALFUNCTION" 7 "EFUSE_SELF_TEST_EFUSE_RESULT_FAILED_POWER_FET_CHANNEL_OPEN" 6 "EFUSE_SELF_TEST_EFUSE_RESULT_FAILED_ENABLE_LOW_MALFUNCTION" 5 "EFUSE_SELF_TEST_EFUSE_RESULT_FAILED_POWER_FET_STUCK_ON" 4 "EFUSE_SELF_TEST_EFUSE_RESULT_FAILED_EFUSE_OUTPUT_SHORT" 3 "EFUSE_SELF_TEST_EFUSE_RESULT_FAILED_RAILS_UNSTABLE" 2 "EFUSE_SELF_TEST_EFUSE_RESULT_PASSED" 1 "EFUSE_SELF_TEST_EFUSE_RESULT_RUNNING" 0 "EFUSE_SELF_TEST_EFUSE_RESULT_NOT_RUN" ;
VAL_ 753 VCFRONT_EPAS3PEFuseVNFState 7 "EFUSE_ASIC_STATE_SELF_TEST" 6 "EFUSE_ASIC_STATE_SELF_TEST_PREP" 5 "EFUSE_ASIC_STATE_LOCKED" 4 "EFUSE_ASIC_STATE_UNLOCKED" 3 "EFUSE_ASIC_STATE_CONFIGURATION" 2 "EFUSE_ASIC_STATE_WAKEUP" 1 "EFUSE_ASIC_STATE_STANDBY" 0 "EFUSE_ASIC_STATE_UNKNOWN" ;
VAL_ 753 VCFRONT_EPAS3PEFuseHardshortThre 15 "VNF1048_HSHT_160_MV" 14 "VNF1048_HSHT_139_3_MV" 13 "VNF1048_HSHT_121_3_MV" 12 "VNF1048_HSHT_105_6_MV" 11 "VNF1048_HSHT_91_9_MV" 10 "VNF1048_HSHT_80_MV" 9 "VNF1048_HSHT_69_6_MV" 8 "VNF1048_HSHT_60_6_MV" 7 "VNF1048_HSHT_52_8_MV" 6 "VNF1048_HSHT_45_9_MV" 5 "VNF1048_HSHT_40_MV" 4 "VNF1048_HSHT_34_8_MV" 3 "VNF1048_HSHT_30_3_MV" 2 "VNF1048_HSHT_26_4_MV" 1 "VNF1048_HSHT_23_MV" 0 "VNF1048_HSHT_20_MV" ;
VAL_ 753 VCFRONT_EPAS3PEFuseVNFSelfTestSt 3 "EFUSE_SELF_TEST_SKIPPED" 2 "EFUSE_SELF_TEST_COMPLETE" 1 "EFUSE_SELF_TEST_ACTIVE" 0 "EFUSE_SELF_TEST_NOT_COMPLETE" ;
VAL_ 753 VCFRONT_EPAS3SState 3 "EFUSE_STATE_SNA" 2 "EFUSE_STATE_LOCKED_OUT" 1 "EFUSE_STATE_ON" 0 "EFUSE_STATE_OFF" ;
VAL_ 753 VCFRONT_EPAS3SSelfTestResult 12 "EFUSE_SELF_TEST_EFUSE_RESULT_SNA" 11 "EFUSE_SELF_TEST_EFUSE_RESULT_SKIPPED" 10 "EFUSE_SELF_TEST_EFUSE_RESULT_FAILED_NOT_LATCHED" 9 "EFUSE_SELF_TEST_EFUSE_RESULT_FAILED_TURN_OFF_PATH_TOO_SLOW" 8 "EFUSE_SELF_TEST_EFUSE_RESULT_FAILED_ENABLE_HIGH_MALFUNCTION" 7 "EFUSE_SELF_TEST_EFUSE_RESULT_FAILED_POWER_FET_CHANNEL_OPEN" 6 "EFUSE_SELF_TEST_EFUSE_RESULT_FAILED_ENABLE_LOW_MALFUNCTION" 5 "EFUSE_SELF_TEST_EFUSE_RESULT_FAILED_POWER_FET_STUCK_ON" 4 "EFUSE_SELF_TEST_EFUSE_RESULT_FAILED_EFUSE_OUTPUT_SHORT" 3 "EFUSE_SELF_TEST_EFUSE_RESULT_FAILED_RAILS_UNSTABLE" 2 "EFUSE_SELF_TEST_EFUSE_RESULT_PASSED" 1 "EFUSE_SELF_TEST_EFUSE_RESULT_RUNNING" 0 "EFUSE_SELF_TEST_EFUSE_RESULT_NOT_RUN" ;
VAL_ 753 VCFRONT_EPAS3SEFuseVNFState 7 "EFUSE_ASIC_STATE_SELF_TEST" 6 "EFUSE_ASIC_STATE_SELF_TEST_PREP" 5 "EFUSE_ASIC_STATE_LOCKED" 4 "EFUSE_ASIC_STATE_UNLOCKED" 3 "EFUSE_ASIC_STATE_CONFIGURATION" 2 "EFUSE_ASIC_STATE_WAKEUP" 1 "EFUSE_ASIC_STATE_STANDBY" 0 "EFUSE_ASIC_STATE_UNKNOWN" ;
VAL_ 753 VCFRONT_EPAS3SEFuseVNFSelfTestSt 3 "EFUSE_SELF_TEST_SKIPPED" 2 "EFUSE_SELF_TEST_COMPLETE" 1 "EFUSE_SELF_TEST_ACTIVE" 0 "EFUSE_SELF_TEST_NOT_COMPLETE" ;
VAL_ 753 VCFRONT_ESPMotorState 3 "EFUSE_STATE_SNA" 2 "EFUSE_STATE_LOCKED_OUT" 1 "EFUSE_STATE_ON" 0 "EFUSE_STATE_OFF" ;
VAL_ 753 VCFRONT_ESPMotorSelfTestResult 12 "EFUSE_SELF_TEST_EFUSE_RESULT_SNA" 11 "EFUSE_SELF_TEST_EFUSE_RESULT_SKIPPED" 10 "EFUSE_SELF_TEST_EFUSE_RESULT_FAILED_NOT_LATCHED" 9 "EFUSE_SELF_TEST_EFUSE_RESULT_FAILED_TURN_OFF_PATH_TOO_SLOW" 8 "EFUSE_SELF_TEST_EFUSE_RESULT_FAILED_ENABLE_HIGH_MALFUNCTION" 7 "EFUSE_SELF_TEST_EFUSE_RESULT_FAILED_POWER_FET_CHANNEL_OPEN" 6 "EFUSE_SELF_TEST_EFUSE_RESULT_FAILED_ENABLE_LOW_MALFUNCTION" 5 "EFUSE_SELF_TEST_EFUSE_RESULT_FAILED_POWER_FET_STUCK_ON" 4 "EFUSE_SELF_TEST_EFUSE_RESULT_FAILED_EFUSE_OUTPUT_SHORT" 3 "EFUSE_SELF_TEST_EFUSE_RESULT_FAILED_RAILS_UNSTABLE" 2 "EFUSE_SELF_TEST_EFUSE_RESULT_PASSED" 1 "EFUSE_SELF_TEST_EFUSE_RESULT_RUNNING" 0 "EFUSE_SELF_TEST_EFUSE_RESULT_NOT_RUN" ;
VAL_ 753 VCFRONT_ESPMotorEFuseVNFState 7 "EFUSE_ASIC_STATE_SELF_TEST" 6 "EFUSE_ASIC_STATE_SELF_TEST_PREP" 5 "EFUSE_ASIC_STATE_LOCKED" 4 "EFUSE_ASIC_STATE_UNLOCKED" 3 "EFUSE_ASIC_STATE_CONFIGURATION" 2 "EFUSE_ASIC_STATE_WAKEUP" 1 "EFUSE_ASIC_STATE_STANDBY" 0 "EFUSE_ASIC_STATE_UNKNOWN" ;
VAL_ 753 VCFRONT_ESPMotorEFuseVNFSelfTest 3 "EFUSE_SELF_TEST_SKIPPED" 2 "EFUSE_SELF_TEST_COMPLETE" 1 "EFUSE_SELF_TEST_ACTIVE" 0 "EFUSE_SELF_TEST_NOT_COMPLETE" ;
VAL_ 753 VCFRONT_ESPValveState 3 "EFUSE_STATE_SNA" 2 "EFUSE_STATE_LOCKED_OUT" 1 "EFUSE_STATE_ON" 0 "EFUSE_STATE_OFF" ;
VAL_ 753 VCFRONT_autopilot2State 3 "EFUSE_STATE_SNA" 2 "EFUSE_STATE_LOCKED_OUT" 1 "EFUSE_STATE_ON" 0 "EFUSE_STATE_OFF" ;
VAL_ 753 VCFRONT_vbatFusedSelfTestResult 12 "EFUSE_SELF_TEST_EFUSE_RESULT_SNA" 11 "EFUSE_SELF_TEST_EFUSE_RESULT_SKIPPED" 10 "EFUSE_SELF_TEST_EFUSE_RESULT_FAILED_NOT_LATCHED" 9 "EFUSE_SELF_TEST_EFUSE_RESULT_FAILED_TURN_OFF_PATH_TOO_SLOW" 8 "EFUSE_SELF_TEST_EFUSE_RESULT_FAILED_ENABLE_HIGH_MALFUNCTION" 7 "EFUSE_SELF_TEST_EFUSE_RESULT_FAILED_POWER_FET_CHANNEL_OPEN" 6 "EFUSE_SELF_TEST_EFUSE_RESULT_FAILED_ENABLE_LOW_MALFUNCTION" 5 "EFUSE_SELF_TEST_EFUSE_RESULT_FAILED_POWER_FET_STUCK_ON" 4 "EFUSE_SELF_TEST_EFUSE_RESULT_FAILED_EFUSE_OUTPUT_SHORT" 3 "EFUSE_SELF_TEST_EFUSE_RESULT_FAILED_RAILS_UNSTABLE" 2 "EFUSE_SELF_TEST_EFUSE_RESULT_PASSED" 1 "EFUSE_SELF_TEST_EFUSE_RESULT_RUNNING" 0 "EFUSE_SELF_TEST_EFUSE_RESULT_NOT_RUN" ;
VAL_ 753 VCFRONT_IBSUnfilteredTemperature -32768 "SNA" ;
VAL_ 1353 VCFRONT_homelinkCommStatus 3 "HOMELINK_COMM_STATUS_FAULT" 2 "HOMELINK_COMM_STATUS_ON" 1 "HOMELINK_COMM_STATUS_OFF" 0 "HOMELINK_COMM_STATUS_SNA" ;
